[part 7 of 22: package /Cluster]
AUTOSAR XML (schema 4-3-0)
package /Cluster  (continued)
  can cluster E3V_K2CANFD: baudrate=500000, protocol-name=CAN, protocol-version=2.0, bus-off-recovery={bor-counter-l-1-to-l-2=1, bor-time-l-1=0.05, bor-time-l-2=0.2}, can-fd-baudrate=500000  (continued)
    can physical channel CHNL: comm-connectors=CN_E3V_K2CANFD  (continued)
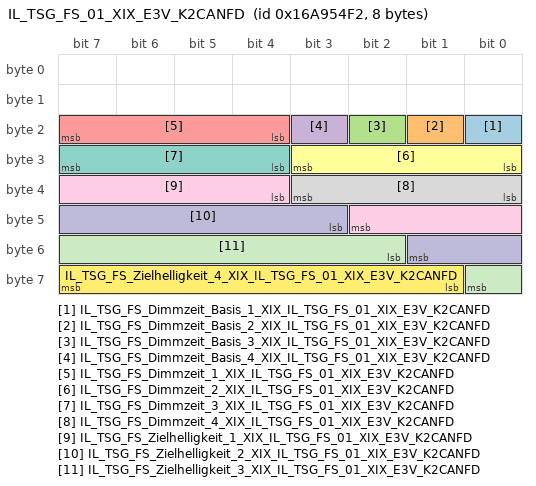
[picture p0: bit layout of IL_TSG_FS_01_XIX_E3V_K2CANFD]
      frame IL_TSG_FS_01_XIX_E3V_K2CANFD: id 0x16A954F2, from SAM, frame-length=8, can-addressing-mode=EXTENDED, can-frame-rx-behavior=CAN-FD, can-frame-tx-behavior=CAN-FD
        pdu IL_TSG_FS_01_XIX_E3V_K2CANFD: length=8, minimum-delay=0.05, transmission-mode-true-timing={cyclic-timing={time-offset=0.0, time-period=0.5}, event-controlled-timing={number-of-repetitions=0, repetition-period=0.0}}, unused-bit-pattern=0
          signal IL_TSG_FS_Dimmzeit_Basis_1_XIX_IL_TSG_FS_01_XIX_E3V_K2CANFD: start 16, 1 bit, little-endian, data-type-policy=OVERRIDE, i-signal-type=PRIMITIVE, init-value=0, base-type=BT_IL_TSG_FS_Dimmzeit_Basis_1, compu {0=Cx0_Zeitbasis_50ms (CM_IL_TSG_FS_Dimmzeit_Basis_1_Cx0_Zeitbasis_50ms), 1=Cx1_Zeitbasis_250ms (CM_IL_TSG_FS_Dimmzeit_Basis_1_Cx1_Zeitbasis_250ms)}, range raw 0..1, transfer-property=TRIGGERED-ON-CHANGE-WITHOUT-REPETITION  # Dimmzeit Zeitbasis für Lichtausgang 1 TSG FS umschaltbar zwischen 250ms und 50ms.
          signal IL_TSG_FS_Dimmzeit_Basis_2_XIX_IL_TSG_FS_01_XIX_E3V_K2CANFD: start 17, 1 bit, little-endian, data-type-policy=OVERRIDE, i-signal-type=PRIMITIVE, init-value=0, base-type=BT_IL_TSG_FS_Dimmzeit_Basis_2, compu {0=Cx0_Zeitbasis_50ms (CM_IL_TSG_FS_Dimmzeit_Basis_2_Cx0_Zeitbasis_50ms), 1=Cx1_Zeitbasis_250ms (CM_IL_TSG_FS_Dimmzeit_Basis_2_Cx1_Zeitbasis_250ms)}, range raw 0..1, transfer-property=TRIGGERED-ON-CHANGE-WITHOUT-REPETITION  # Dimmzeit Zeitbasis für Lichtausgang 2 TSG FS umschaltbar zwischen 250ms und 50ms.
          signal IL_TSG_FS_Dimmzeit_Basis_3_XIX_IL_TSG_FS_01_XIX_E3V_K2CANFD: start 18, 1 bit, little-endian, data-type-policy=OVERRIDE, i-signal-type=PRIMITIVE, init-value=0, base-type=BT_IL_TSG_FS_Dimmzeit_Basis_3, compu {0=Cx0_Zeitbasis_50ms (CM_IL_TSG_FS_Dimmzeit_Basis_3_Cx0_Zeitbasis_50ms), 1=Cx1_Zeitbasis_250ms (CM_IL_TSG_FS_Dimmzeit_Basis_3_Cx1_Zeitbasis_250ms)}, range raw 0..1, transfer-property=TRIGGERED-ON-CHANGE-WITHOUT-REPETITION  # Dimmzeit Zeitbasis für Lichtausgang 3 TSG FS umschaltbar zwischen 250ms und 50ms.
          signal IL_TSG_FS_Dimmzeit_Basis_4_XIX_IL_TSG_FS_01_XIX_E3V_K2CANFD: start 19, 1 bit, little-endian, data-type-policy=OVERRIDE, i-signal-type=PRIMITIVE, init-value=0, base-type=BT_IL_TSG_FS_Dimmzeit_Basis_4, compu {0=Cx0_Zeitbasis_50ms (CM_IL_TSG_FS_Dimmzeit_Basis_4_Cx0_Zeitbasis_50ms), 1=Cx1_Zeitbasis_250ms (CM_IL_TSG_FS_Dimmzeit_Basis_4_Cx1_Zeitbasis_250ms)}, range raw 0..1, transfer-property=TRIGGERED-ON-CHANGE-WITHOUT-REPETITION  # Dimmzeit Zeitbasis für Lichtausgang 4 TSG FS umschaltbar zwischen 250ms und 50ms.
          signal IL_TSG_FS_Dimmzeit_1_XIX_IL_TSG_FS_01_XIX_E3V_K2CANFD: start 20, 4 bit, little-endian, data-type-policy=OVERRIDE, i-signal-type=PRIMITIVE, init-value=0, base-type=BT_IL_TSG_FS_Dimmzeit_1, compu {phys=raw for raw 0..15; unit Unit_None}, range phys 0..15 Unit_None, raw 0..15, unit=Unit_None, transfer-property=TRIGGERED-ON-CHANGE-WITHOUT-REPETITION  # Dimmzeit für Ausgang 1 TSG FS als Multiplikator der Dimmzeit Zeitbasis (Hinweis: Dimmzeit Zeitbasis für Ausgang 1 TSG FS beachten)
          signal IL_TSG_FS_Dimmzeit_2_XIX_IL_TSG_FS_01_XIX_E3V_K2CANFD: start 24, 4 bit, little-endian, data-type-policy=OVERRIDE, i-signal-type=PRIMITIVE, init-value=0, base-type=BT_IL_TSG_FS_Dimmzeit_2, compu {phys=raw for raw 0..15; unit Unit_None}, range phys 0..15 Unit_None, raw 0..15, unit=Unit_None, transfer-property=TRIGGERED-ON-CHANGE-WITHOUT-REPETITION  # Dimmzeit für Ausgang 2 TSG FS als Multiplikator der Dimmzeit Zeitbasis (Hinweis: Dimmzeit Zeitbasis für Ausgang 2 TSG FS beachten)
          signal IL_TSG_FS_Dimmzeit_3_XIX_IL_TSG_FS_01_XIX_E3V_K2CANFD: start 28, 4 bit, little-endian, data-type-policy=OVERRIDE, i-signal-type=PRIMITIVE, init-value=0, base-type=BT_IL_TSG_FS_Dimmzeit_3, compu {phys=raw for raw 0..15; unit Unit_None}, range phys 0..15 Unit_None, raw 0..15, unit=Unit_None, transfer-property=TRIGGERED-ON-CHANGE-WITHOUT-REPETITION  # Dimmzeit für Ausgang 3 TSG FS als Multiplikator der Dimmzeit Zeitbasis (Hinweis: Dimmzeit Zeitbasis für Ausgang 3 TSG FS beachten)
          signal IL_TSG_FS_Dimmzeit_4_XIX_IL_TSG_FS_01_XIX_E3V_K2CANFD: start 32, 4 bit, little-endian, data-type-policy=OVERRIDE, i-signal-type=PRIMITIVE, init-value=0, base-type=BT_IL_TSG_FS_Dimmzeit_4, compu {phys=raw for raw 0..15; unit Unit_None}, range phys 0..15 Unit_None, raw 0..15, unit=Unit_None, transfer-property=TRIGGERED-ON-CHANGE-WITHOUT-REPETITION  # Dimmzeit für Ausgang 4 TSG FS als Multiplikator der Dimmzeit Zeitbasis (Hinweis: Dimmzeit Zeitbasis für Ausgang 4 TSG FS beachten)
          signal IL_TSG_FS_Zielhelligkeit_1_XIX_IL_TSG_FS_01_XIX_E3V_K2CANFD: start 36, 7 bit, little-endian, data-type-policy=OVERRIDE, i-signal-type=PRIMITIVE, init-value=0, base-type=BT_IL_TSG_FS_Zielhelligkeit_1, compu {phys=raw for raw 0..100; unit Unit_PerCent}, range phys 0..100 Unit_PerCent, raw 0..100, unit=Unit_PerCent, transfer-property=TRIGGERED-ON-CHANGE-WITHOUT-REPETITION  # Intensität für Ausgang 1 TSG FS
          signal IL_TSG_FS_Zielhelligkeit_2_XIX_IL_TSG_FS_01_XIX_E3V_K2CANFD: start 43, 7 bit, little-endian, data-type-policy=OVERRIDE, i-signal-type=PRIMITIVE, init-value=0, base-type=BT_IL_TSG_FS_Zielhelligkeit_2, compu {phys=raw for raw 0..100; unit Unit_PerCent}, range phys 0..100 Unit_PerCent, raw 0..100, unit=Unit_PerCent, transfer-property=TRIGGERED-ON-CHANGE-WITHOUT-REPETITION  # Intensität für Ausgang 2 TSG FS
          signal IL_TSG_FS_Zielhelligkeit_3_XIX_IL_TSG_FS_01_XIX_E3V_K2CANFD: start 50, 7 bit, little-endian, data-type-policy=OVERRIDE, i-signal-type=PRIMITIVE, init-value=0, base-type=BT_IL_TSG_FS_Zielhelligkeit_3, compu {phys=raw for raw 0..100; unit Unit_PerCent}, range phys 0..100 Unit_PerCent, raw 0..100, unit=Unit_PerCent, transfer-property=TRIGGERED-ON-CHANGE-WITHOUT-REPETITION  # Intensität für Ausgang 3 TSG FS
          signal IL_TSG_FS_Zielhelligkeit_4_XIX_IL_TSG_FS_01_XIX_E3V_K2CANFD: start 57, 7 bit, little-endian, data-type-policy=OVERRIDE, i-signal-type=PRIMITIVE, init-value=0, base-type=BT_IL_TSG_FS_Zielhelligkeit_4, compu {phys=raw for raw 0..100; unit Unit_PerCent}, range phys 0..100 Unit_PerCent, raw 0..100, unit=Unit_PerCent, transfer-property=TRIGGERED-ON-CHANGE-WITHOUT-REPETITION  # Intensität für Ausgang 4 TSG FS
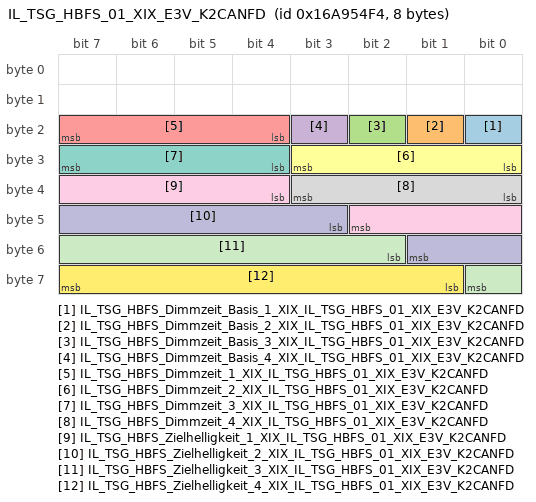
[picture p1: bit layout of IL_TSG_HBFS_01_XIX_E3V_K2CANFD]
      frame IL_TSG_HBFS_01_XIX_E3V_K2CANFD: id 0x16A954F4, from SAM, frame-length=8, can-addressing-mode=EXTENDED, can-frame-rx-behavior=CAN-FD, can-frame-tx-behavior=CAN-FD
        pdu IL_TSG_HBFS_01_XIX_E3V_K2CANFD: length=8, minimum-delay=0.05, transmission-mode-true-timing={cyclic-timing={time-offset=0.0, time-period=0.5}, event-controlled-timing={number-of-repetitions=0, repetition-period=0.0}}, unused-bit-pattern=0
          signal IL_TSG_HBFS_Dimmzeit_Basis_1_XIX_IL_TSG_HBFS_01_XIX_E3V_K2CANFD: start 16, 1 bit, little-endian, data-type-policy=OVERRIDE, i-signal-type=PRIMITIVE, init-value=0, base-type=BT_IL_TSG_HBFS_Dimmzeit_Basis_1, compu {0=Cx0_Zeitbasis_50ms (CM_IL_TSG_HBFS_Dimmzeit_Basis_1_Cx0_Zeitbasis_50ms), 1=Cx1_Zeitbasis_250ms (CM_IL_TSG_HBFS_Dimmzeit_Basis_1_Cx1_Zeitbasis_250ms)}, range raw 0..1, transfer-property=TRIGGERED-ON-CHANGE-WITHOUT-REPETITION  # Dimmzeit Zeitbasis für Lichtausgang 1 TSG HBFS umschaltbar zwischen 250ms und 50ms.
          signal IL_TSG_HBFS_Dimmzeit_Basis_2_XIX_IL_TSG_HBFS_01_XIX_E3V_K2CANFD: start 17, 1 bit, little-endian, data-type-policy=OVERRIDE, i-signal-type=PRIMITIVE, init-value=0, base-type=BT_IL_TSG_HBFS_Dimmzeit_Basis_2, compu {0=Cx0_Zeitbasis_50ms (CM_IL_TSG_HBFS_Dimmzeit_Basis_2_Cx0_Zeitbasis_50ms), 1=Cx1_Zeitbasis_250ms (CM_IL_TSG_HBFS_Dimmzeit_Basis_2_Cx1_Zeitbasis_250ms)}, range raw 0..1, transfer-property=TRIGGERED-ON-CHANGE-WITHOUT-REPETITION  # Dimmzeit Zeitbasis für Lichtausgang 2 TSG HBFS umschaltbar zwischen 250ms und 50ms.
          signal IL_TSG_HBFS_Dimmzeit_Basis_3_XIX_IL_TSG_HBFS_01_XIX_E3V_K2CANFD: start 18, 1 bit, little-endian, data-type-policy=OVERRIDE, i-signal-type=PRIMITIVE, init-value=0, base-type=BT_IL_TSG_HBFS_Dimmzeit_Basis_3, compu {0=Cx0_Zeitbasis_50ms (CM_IL_TSG_HBFS_Dimmzeit_Basis_3_Cx0_Zeitbasis_50ms), 1=Cx1_Zeitbasis_250ms (CM_IL_TSG_HBFS_Dimmzeit_Basis_3_Cx1_Zeitbasis_250ms)}, range raw 0..1, transfer-property=TRIGGERED-ON-CHANGE-WITHOUT-REPETITION  # Dimmzeit Zeitbasis für Lichtausgang 3 TSG HBFS umschaltbar zwischen 250ms und 50ms.
          signal IL_TSG_HBFS_Dimmzeit_Basis_4_XIX_IL_TSG_HBFS_01_XIX_E3V_K2CANFD: start 19, 1 bit, little-endian, data-type-policy=OVERRIDE, i-signal-type=PRIMITIVE, init-value=0, base-type=BT_IL_TSG_HBFS_Dimmzeit_Basis_4, compu {0=Cx0_Zeitbasis_50ms (CM_IL_TSG_HBFS_Dimmzeit_Basis_4_Cx0_Zeitbasis_50ms), 1=Cx1_Zeitbasis_250ms (CM_IL_TSG_HBFS_Dimmzeit_Basis_4_Cx1_Zeitbasis_250ms)}, range raw 0..1, transfer-property=TRIGGERED-ON-CHANGE-WITHOUT-REPETITION  # Dimmzeit Zeitbasis für Lichtausgang 4 TSG HBFS umschaltbar zwischen 250ms und 50ms.
          signal IL_TSG_HBFS_Dimmzeit_1_XIX_IL_TSG_HBFS_01_XIX_E3V_K2CANFD: start 20, 4 bit, little-endian, data-type-policy=OVERRIDE, i-signal-type=PRIMITIVE, init-value=0, base-type=BT_IL_TSG_HBFS_Dimmzeit_1, compu {phys=raw for raw 0..15; unit Unit_None}, range phys 0..15 Unit_None, raw 0..15, unit=Unit_None, transfer-property=TRIGGERED-ON-CHANGE-WITHOUT-REPETITION  # Dimmzeit für Ausgang 1 TSG HBFS als Multiplikator der Dimmzeit Zeitbasis (Hinweis: Dimmzeit Zeitbasis für Ausgang 1 TSG HBFS beachten)
          signal IL_TSG_HBFS_Dimmzeit_2_XIX_IL_TSG_HBFS_01_XIX_E3V_K2CANFD: start 24, 4 bit, little-endian, data-type-policy=OVERRIDE, i-signal-type=PRIMITIVE, init-value=0, base-type=BT_IL_TSG_HBFS_Dimmzeit_2, compu {phys=raw for raw 0..15; unit Unit_None}, range phys 0..15 Unit_None, raw 0..15, unit=Unit_None, transfer-property=TRIGGERED-ON-CHANGE-WITHOUT-REPETITION  # Dimmzeit für Ausgang 2 TSG HBFS als Multiplikator der Dimmzeit Zeitbasis (Hinweis: Dimmzeit Zeitbasis für Ausgang 2 TSG HBFS beachten)
          signal IL_TSG_HBFS_Dimmzeit_3_XIX_IL_TSG_HBFS_01_XIX_E3V_K2CANFD: start 28, 4 bit, little-endian, data-type-policy=OVERRIDE, i-signal-type=PRIMITIVE, init-value=0, base-type=BT_IL_TSG_HBFS_Dimmzeit_3, compu {phys=raw for raw 0..15; unit Unit_None}, range phys 0..15 Unit_None, raw 0..15, unit=Unit_None, transfer-property=TRIGGERED-ON-CHANGE-WITHOUT-REPETITION  # Dimmzeit für Ausgang 3 TSG HBFS als Multiplikator der Dimmzeit Zeitbasis (Hinweis: Dimmzeit Zeitbasis für Ausgang 3 TSG HBFS beachten)
          signal IL_TSG_HBFS_Dimmzeit_4_XIX_IL_TSG_HBFS_01_XIX_E3V_K2CANFD: start 32, 4 bit, little-endian, data-type-policy=OVERRIDE, i-signal-type=PRIMITIVE, init-value=0, base-type=BT_IL_TSG_HBFS_Dimmzeit_4, compu {phys=raw for raw 0..15; unit Unit_None}, range phys 0..15 Unit_None, raw 0..15, unit=Unit_None, transfer-property=TRIGGERED-ON-CHANGE-WITHOUT-REPETITION  # Dimmzeit für Ausgang 4 TSG HBFS als Multiplikator der Dimmzeit Zeitbasis (Hinweis: Dimmzeit Zeitbasis für Ausgang 4 TSG HBFS beachten)
          signal IL_TSG_HBFS_Zielhelligkeit_1_XIX_IL_TSG_HBFS_01_XIX_E3V_K2CANFD: start 36, 7 bit, little-endian, data-type-policy=OVERRIDE, i-signal-type=PRIMITIVE, init-value=0, base-type=BT_IL_TSG_HBFS_Zielhelligkeit_1, compu {phys=raw for raw 0..100; unit Unit_PerCent}, range phys 0..100 Unit_PerCent, raw 0..100, unit=Unit_PerCent, transfer-property=TRIGGERED-ON-CHANGE-WITHOUT-REPETITION  # Intensität für Ausgang 1 TSG HBFS
          signal IL_TSG_HBFS_Zielhelligkeit_2_XIX_IL_TSG_HBFS_01_XIX_E3V_K2CANFD: start 43, 7 bit, little-endian, data-type-policy=OVERRIDE, i-signal-type=PRIMITIVE, init-value=0, base-type=BT_IL_TSG_HBFS_Zielhelligkeit_2, compu {phys=raw for raw 0..100; unit Unit_PerCent}, range phys 0..100 Unit_PerCent, raw 0..100, unit=Unit_PerCent, transfer-property=TRIGGERED-ON-CHANGE-WITHOUT-REPETITION  # Intensität für Ausgang 2 TSG HBFS
          signal IL_TSG_HBFS_Zielhelligkeit_3_XIX_IL_TSG_HBFS_01_XIX_E3V_K2CANFD: start 50, 7 bit, little-endian, data-type-policy=OVERRIDE, i-signal-type=PRIMITIVE, init-value=0, base-type=BT_IL_TSG_HBFS_Zielhelligkeit_3, compu {phys=raw for raw 0..100; unit Unit_PerCent}, range phys 0..100 Unit_PerCent, raw 0..100, unit=Unit_PerCent, transfer-property=TRIGGERED-ON-CHANGE-WITHOUT-REPETITION  # Intensität für Ausgang 3 TSG HBFS
          signal IL_TSG_HBFS_Zielhelligkeit_4_XIX_IL_TSG_HBFS_01_XIX_E3V_K2CANFD: start 57, 7 bit, little-endian, data-type-policy=OVERRIDE, i-signal-type=PRIMITIVE, init-value=0, base-type=BT_IL_TSG_HBFS_Zielhelligkeit_4, compu {phys=raw for raw 0..100; unit Unit_PerCent}, range phys 0..100 Unit_PerCent, raw 0..100, unit=Unit_PerCent, transfer-property=TRIGGERED-ON-CHANGE-WITHOUT-REPETITION  # Intensität für Ausgang 4 TSG HBFS
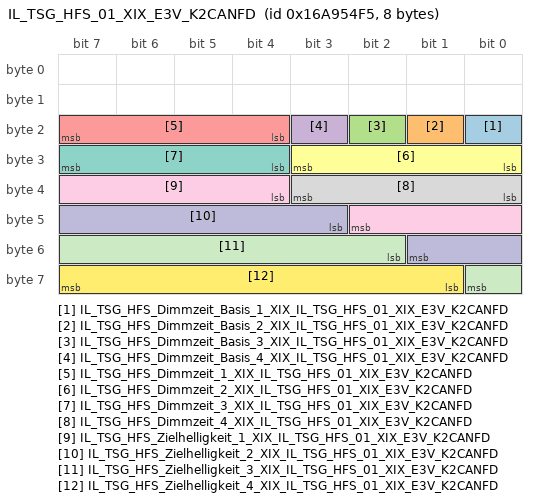
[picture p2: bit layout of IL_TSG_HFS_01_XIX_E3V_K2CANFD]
      frame IL_TSG_HFS_01_XIX_E3V_K2CANFD: id 0x16A954F5, from SAM, frame-length=8, can-addressing-mode=EXTENDED, can-frame-rx-behavior=CAN-FD, can-frame-tx-behavior=CAN-FD
        pdu IL_TSG_HFS_01_XIX_E3V_K2CANFD: length=8, minimum-delay=0.05, transmission-mode-true-timing={cyclic-timing={time-offset=0.0, time-period=0.5}, event-controlled-timing={number-of-repetitions=0, repetition-period=0.0}}, unused-bit-pattern=0
          signal IL_TSG_HFS_Dimmzeit_Basis_1_XIX_IL_TSG_HFS_01_XIX_E3V_K2CANFD: start 16, 1 bit, little-endian, data-type-policy=OVERRIDE, i-signal-type=PRIMITIVE, init-value=0, base-type=BT_IL_TSG_HFS_Dimmzeit_Basis_1, compu {0=Cx0_Zeitbasis_50ms (CM_IL_TSG_HFS_Dimmzeit_Basis_1_Cx0_Zeitbasis_50ms), 1=Cx1_Zeitbasis_250ms (CM_IL_TSG_HFS_Dimmzeit_Basis_1_Cx1_Zeitbasis_250ms)}, range raw 0..1, transfer-property=TRIGGERED-ON-CHANGE-WITHOUT-REPETITION  # Dimmzeit Zeitbasis für Lichtausgang 1 TSG HFS umschaltbar zwischen 250ms und 50ms.
          signal IL_TSG_HFS_Dimmzeit_Basis_2_XIX_IL_TSG_HFS_01_XIX_E3V_K2CANFD: start 17, 1 bit, little-endian, data-type-policy=OVERRIDE, i-signal-type=PRIMITIVE, init-value=0, base-type=BT_IL_TSG_HFS_Dimmzeit_Basis_2, compu {0=Cx0_Zeitbasis_50ms (CM_IL_TSG_HFS_Dimmzeit_Basis_2_Cx0_Zeitbasis_50ms), 1=Cx1_Zeitbasis_250ms (CM_IL_TSG_HFS_Dimmzeit_Basis_2_Cx1_Zeitbasis_250ms)}, range raw 0..1, transfer-property=TRIGGERED-ON-CHANGE-WITHOUT-REPETITION  # Dimmzeit Zeitbasis für Lichtausgang 2 TSG HFS umschaltbar zwischen 250ms und 50ms.
          signal IL_TSG_HFS_Dimmzeit_Basis_3_XIX_IL_TSG_HFS_01_XIX_E3V_K2CANFD: start 18, 1 bit, little-endian, data-type-policy=OVERRIDE, i-signal-type=PRIMITIVE, init-value=0, base-type=BT_IL_TSG_HFS_Dimmzeit_Basis_3, compu {0=Cx0_Zeitbasis_50ms (CM_IL_TSG_HFS_Dimmzeit_Basis_3_Cx0_Zeitbasis_50ms), 1=Cx1_Zeitbasis_250ms (CM_IL_TSG_HFS_Dimmzeit_Basis_3_Cx1_Zeitbasis_250ms)}, range raw 0..1, transfer-property=TRIGGERED-ON-CHANGE-WITHOUT-REPETITION  # Dimmzeit Zeitbasis für Lichtausgang 3 TSG HFS umschaltbar zwischen 250ms und 50ms.
          signal IL_TSG_HFS_Dimmzeit_Basis_4_XIX_IL_TSG_HFS_01_XIX_E3V_K2CANFD: start 19, 1 bit, little-endian, data-type-policy=OVERRIDE, i-signal-type=PRIMITIVE, init-value=0, base-type=BT_IL_TSG_HFS_Dimmzeit_Basis_4, compu {0=Cx0_Zeitbasis_50ms (CM_IL_TSG_HFS_Dimmzeit_Basis_4_Cx0_Zeitbasis_50ms), 1=Cx1_Zeitbasis_250ms (CM_IL_TSG_HFS_Dimmzeit_Basis_4_Cx1_Zeitbasis_250ms)}, range raw 0..1, transfer-property=TRIGGERED-ON-CHANGE-WITHOUT-REPETITION  # Dimmzeit Zeitbasis für Lichtausgang 4 TSG HFS umschaltbar zwischen 250ms und 50ms.
          signal IL_TSG_HFS_Dimmzeit_1_XIX_IL_TSG_HFS_01_XIX_E3V_K2CANFD: start 20, 4 bit, little-endian, data-type-policy=OVERRIDE, i-signal-type=PRIMITIVE, init-value=0, base-type=BT_IL_TSG_HFS_Dimmzeit_1, compu {phys=raw for raw 0..15; unit Unit_None}, range phys 0..15 Unit_None, raw 0..15, unit=Unit_None, transfer-property=TRIGGERED-ON-CHANGE-WITHOUT-REPETITION  # Dimmzeit für Ausgang 1 TSG HFS als Multiplikator der Dimmzeit Zeitbasis (Hinweis: Dimmzeit Zeitbasis für Ausgang 1 TSG HFS beachten)
          signal IL_TSG_HFS_Dimmzeit_2_XIX_IL_TSG_HFS_01_XIX_E3V_K2CANFD: start 24, 4 bit, little-endian, data-type-policy=OVERRIDE, i-signal-type=PRIMITIVE, init-value=0, base-type=BT_IL_TSG_HFS_Dimmzeit_2, compu {phys=raw for raw 0..15; unit Unit_None}, range phys 0..15 Unit_None, raw 0..15, unit=Unit_None, transfer-property=TRIGGERED-ON-CHANGE-WITHOUT-REPETITION  # Dimmzeit für Ausgang TSG HFS als Multiplikator der Dimmzeit Zeitbasis (Hinweis: Dimmzeit Zeitbasis für Ausgang 2 TSG HFS beachten)
          signal IL_TSG_HFS_Dimmzeit_3_XIX_IL_TSG_HFS_01_XIX_E3V_K2CANFD: start 28, 4 bit, little-endian, data-type-policy=OVERRIDE, i-signal-type=PRIMITIVE, init-value=0, base-type=BT_IL_TSG_HFS_Dimmzeit_3, compu {phys=raw for raw 0..15; unit Unit_None}, range phys 0..15 Unit_None, raw 0..15, unit=Unit_None, transfer-property=TRIGGERED-ON-CHANGE-WITHOUT-REPETITION  # Dimmzeit für Ausgang 3 TSG HFS als Multiplikator der Dimmzeit Zeitbasis (Hinweis: Dimmzeit Zeitbasis für Ausgang 3 TSG HFS beachten)
          signal IL_TSG_HFS_Dimmzeit_4_XIX_IL_TSG_HFS_01_XIX_E3V_K2CANFD: start 32, 4 bit, little-endian, data-type-policy=OVERRIDE, i-signal-type=PRIMITIVE, init-value=0, base-type=BT_IL_TSG_HFS_Dimmzeit_4, compu {phys=raw for raw 0..15; unit Unit_None}, range phys 0..15 Unit_None, raw 0..15, unit=Unit_None, transfer-property=TRIGGERED-ON-CHANGE-WITHOUT-REPETITION  # Dimmzeit für Ausgang 4 TSG HFS als Multiplikator der Dimmzeit Zeitbasis (Hinweis: Dimmzeit Zeitbasis für Ausgang 4 TSG HFS beachten)
          signal IL_TSG_HFS_Zielhelligkeit_1_XIX_IL_TSG_HFS_01_XIX_E3V_K2CANFD: start 36, 7 bit, little-endian, data-type-policy=OVERRIDE, i-signal-type=PRIMITIVE, init-value=0, base-type=BT_IL_TSG_HFS_Zielhelligkeit_1, compu {phys=raw for raw 0..100; unit Unit_PerCent}, range phys 0..100 Unit_PerCent, raw 0..100, unit=Unit_PerCent, transfer-property=TRIGGERED-ON-CHANGE-WITHOUT-REPETITION  # Intensität für Ausgang 1 TSG HFS
          signal IL_TSG_HFS_Zielhelligkeit_2_XIX_IL_TSG_HFS_01_XIX_E3V_K2CANFD: start 43, 7 bit, little-endian, data-type-policy=OVERRIDE, i-signal-type=PRIMITIVE, init-value=0, base-type=BT_IL_TSG_HFS_Zielhelligkeit_2, compu {phys=raw for raw 0..100; unit Unit_PerCent}, range phys 0..100 Unit_PerCent, raw 0..100, unit=Unit_PerCent, transfer-property=TRIGGERED-ON-CHANGE-WITHOUT-REPETITION  # Intensität für Ausgang 2 TSG HFS
          signal IL_TSG_HFS_Zielhelligkeit_3_XIX_IL_TSG_HFS_01_XIX_E3V_K2CANFD: start 50, 7 bit, little-endian, data-type-policy=OVERRIDE, i-signal-type=PRIMITIVE, init-value=0, base-type=BT_IL_TSG_HFS_Zielhelligkeit_3, compu {phys=raw for raw 0..100; unit Unit_PerCent}, range phys 0..100 Unit_PerCent, raw 0..100, unit=Unit_PerCent, transfer-property=TRIGGERED-ON-CHANGE-WITHOUT-REPETITION  # Intensität für Ausgang 3 TSG HFS
          signal IL_TSG_HFS_Zielhelligkeit_4_XIX_IL_TSG_HFS_01_XIX_E3V_K2CANFD: start 57, 7 bit, little-endian, data-type-policy=OVERRIDE, i-signal-type=PRIMITIVE, init-value=0, base-type=BT_IL_TSG_HFS_Zielhelligkeit_4, compu {phys=raw for raw 0..100; unit Unit_PerCent}, range phys 0..100 Unit_PerCent, raw 0..100, unit=Unit_PerCent, transfer-property=TRIGGERED-ON-CHANGE-WITHOUT-REPETITION  # Intensität für Ausgang 4 TSG HFS
      frame Innenlicht_11_XIX_E3V_K2CANFD: id 0x5F4, from SAM, frame-length=8, can-addressing-mode=STANDARD, can-frame-rx-behavior=CAN-FD, can-frame-tx-behavior=CAN-FD
        pdu Innenlicht_11_XIX_E3V_K2CANFD: length=8, minimum-delay=0.05, transmission-mode-true-timing={cyclic-timing={time-offset=0.0, time-period=0.5}, event-controlled-timing={number-of-repetitions=0, repetition-period=0.0}}, unused-bit-pattern=0
          signal IL_Dimmung_V_Tuerkontur_XIX_Innenlicht_11_XIX_E3V_K2CANFD: start 0, 8 bit, little-endian, data-type-policy=OVERRIDE, i-signal-type=PRIMITIVE, init-value=0, base-type=BT_IL_Dimmung_V_Tuerkontur, compu {phys=raw for raw 0..100; unit Unit_PerCent}, range phys 0..100 Unit_PerCent, raw 0..100, unit=Unit_PerCent, transfer-property=TRIGGERED-ON-CHANGE-WITHOUT-REPETITION  # Dimmung Türkontur vorne (bei Änderung im 30 ms Raster)
          signal IL_Dimmung_H_Tuerkontur_XIX_Innenlicht_11_XIX_E3V_K2CANFD: start 8, 8 bit, little-endian, data-type-policy=OVERRIDE, i-signal-type=PRIMITIVE, init-value=0, base-type=BT_IL_Dimmung_H_Tuerkontur, compu {phys=raw for raw 0..100; unit Unit_PerCent}, range phys 0..100 Unit_PerCent, raw 0..100, unit=Unit_PerCent, transfer-property=TRIGGERED-ON-CHANGE-WITHOUT-REPETITION  # Dimmung Türkontur hinten (bei Änderung im 30 ms Raster)
          signal IL_Dimmung_Tuerinnengriff_XIX_Innenlicht_11_XIX_E3V_K2CANFD: start 16, 8 bit, little-endian, data-type-policy=OVERRIDE, i-signal-type=PRIMITIVE, init-value=0, base-type=BT_IL_Dimmung_Tuerinnengriff, compu {phys=raw for raw 0..100; unit Unit_PerCent}, range phys 0..100 Unit_PerCent, raw 0..100, unit=Unit_PerCent, transfer-property=TRIGGERED-ON-CHANGE-WITHOUT-REPETITION  # Dimmung Türinnengriff
          signal IL_Dimmung_Umfeldbel_XIX_Innenlicht_11_XIX_E3V_K2CANFD: start 24, 8 bit, little-endian, data-type-policy=OVERRIDE, i-signal-type=PRIMITIVE, init-value=0, base-type=BT_IL_Dimmung_Umfeldbel, compu {phys=raw for raw 0..100; unit Unit_PerCent}, range phys 0..100 Unit_PerCent, raw 0..100, unit=Unit_PerCent, transfer-property=TRIGGERED-ON-CHANGE-WITHOUT-REPETITION  # Dimmung Umfeldbeleuchtung an Türaußenseite oder Außenspiegel
          signal IL_Bel_FS_Ausstieg_XIX_Innenlicht_11_XIX_E3V_K2CANFD: start 32, 1 bit, little-endian, data-type-policy=OVERRIDE, i-signal-type=PRIMITIVE, init-value=0, base-type=BT_IL_Bel_FS_Ausstieg, compu {0=Cx0_inaktiv (CM_IL_Bel_FS_Ausstieg_Cx0_inaktiv), 1=Cx1_aktiv (CM_IL_Bel_FS_Ausstieg_Cx1_aktiv)}, range raw 0..1, transfer-property=TRIGGERED-ON-CHANGE-WITHOUT-REPETITION  # Einschalten der Ausstiegsleuchten oder Türwarnleuchten in Tür oder im Schweller
          signal IL_Bel_BFS_Ausstieg_XIX_Innenlicht_11_XIX_E3V_K2CANFD: start 33, 1 bit, little-endian, data-type-policy=OVERRIDE, i-signal-type=PRIMITIVE, init-value=0, base-type=BT_IL_Bel_BFS_Ausstieg, compu {0=Cx0_inaktiv (CM_IL_Bel_BFS_Ausstieg_Cx0_inaktiv), 1=Cx1_aktiv (CM_IL_Bel_BFS_Ausstieg_Cx1_aktiv)}, range raw 0..1, transfer-property=TRIGGERED-ON-CHANGE-WITHOUT-REPETITION  # Einschalten der Ausstiegsleuchten oder Türwarnleuchten in Tür oder im Schweller
          signal IL_Bel_HFS_Ausstieg_XIX_Innenlicht_11_XIX_E3V_K2CANFD: start 34, 1 bit, little-endian, data-type-policy=OVERRIDE, i-signal-type=PRIMITIVE, init-value=0, base-type=BT_IL_Bel_HFS_Ausstieg, compu {0=Cx0_inaktiv (CM_IL_Bel_HFS_Ausstieg_Cx0_inaktiv), 1=Cx1_aktiv (CM_IL_Bel_HFS_Ausstieg_Cx1_aktiv)}, range raw 0..1, transfer-property=TRIGGERED-ON-CHANGE-WITHOUT-REPETITION  # Einschalten der Ausstiegsleuchten oder Türwarnleuchten in Tür oder im Schweller
          signal IL_Bel_HBFS_Ausstieg_XIX_Innenlicht_11_XIX_E3V_K2CANFD: start 35, 1 bit, little-endian, data-type-policy=OVERRIDE, i-signal-type=PRIMITIVE, init-value=0, base-type=BT_IL_Bel_HBFS_Ausstieg, compu {0=Cx0_inaktiv (CM_IL_Bel_HBFS_Ausstieg_Cx0_inaktiv), 1=Cx1_aktiv (CM_IL_Bel_HBFS_Ausstieg_Cx1_aktiv)}, range raw 0..1, transfer-property=TRIGGERED-ON-CHANGE-WITHOUT-REPETITION  # Einschalten der Ausstiegsleuchten oder Türwarnleuchten in Tür oder im Schweller
          signal BCM1_Innenlicht_gedimmt_V_XIX_Innenlicht_11_XIX_E3V_K2CANFD: start 36, 1 bit, little-endian, data-type-policy=OVERRIDE, i-signal-type=PRIMITIVE, init-value=0, base-type=BT_BCM1_Innenlicht_gedimmt_V, compu {0=Cx0_100_Innenlicht (CM_BCM1_Innenlicht_gedimmt_V_Cx0_100_Innenlicht) (100% Innenlicht), 1=Cx1_gedimmtes_Innenlicht (CM_BCM1_Innenlicht_gedimmt_V_Cx1_gedimmtes_Innenlicht) (gedimmtes Innenlicht)}, range raw 0..1, transfer-property=TRIGGERED-ON-CHANGE-WITHOUT-REPETITION  # Steuerung von BCM_Innenlicht_V
          signal BCM1_Innenlicht_gedimmt_H_XIX_Innenlicht_11_XIX_E3V_K2CANFD: start 37, 1 bit, little-endian, data-type-policy=OVERRIDE, i-signal-type=PRIMITIVE, init-value=0, base-type=BT_BCM1_Innenlicht_gedimmt_H, compu {0=Cx0_100_Innenlicht (CM_BCM1_Innenlicht_gedimmt_H_Cx0_100_Innenlicht) (100% Innenlicht), 1=Cx1_gedimmtes_Innenlicht (CM_BCM1_Innenlicht_gedimmt_H_Cx1_gedimmtes_Innenlicht) (gedimmtes Innenlicht)}, range raw 0..1, transfer-property=TRIGGERED-ON-CHANGE-WITHOUT-REPETITION  # Steuerung von BCM_Innenlicht_H
          signal IL_Innenlicht_aktiv_XIX_Innenlicht_11_XIX_E3V_K2CANFD: start 38, 1 bit, little-endian, data-type-policy=OVERRIDE, i-signal-type=PRIMITIVE, init-value=1, base-type=BT_IL_Innenlicht_aktiv, compu {0=Cx0_Innenlicht_inaktiv (CM_IL_Innenlicht_aktiv_Cx0_Innenlicht_inaktiv) (Innenlicht inaktiv), 1=Cx1_Innenlicht_aktiv (CM_IL_Innenlicht_aktiv_Cx1_Innenlicht_aktiv) (Innenlicht aktiv)}, range raw 0..1, transfer-property=TRIGGERED-ON-CHANGE-WITHOUT-REPETITION  # Status Innenlicht
          signal IL_Klemme_30G_aktiv_XIX_Innenlicht_11_XIX_E3V_K2CANFD: start 39, 1 bit, little-endian, data-type-policy=OVERRIDE, i-signal-type=PRIMITIVE, init-value=0, base-type=BT_IL_Klemme_30G_aktiv, compu {0=Cx0_Kl_30G_abgeschaltet (CM_IL_Klemme_30G_aktiv_Cx0_Kl_30G_abgeschaltet), 1=Cx1_eingeschaltet (CM_IL_Klemme_30G_aktiv_Cx1_eingeschaltet)}, range raw 0..1, transfer-property=TRIGGERED-ON-CHANGE-WITHOUT-REPETITION  # Synchrones Abschalten
          signal BCM1_DI_Rampe_Innenlicht_XIX_Innenlicht_11_XIX_E3V_K2CANFD: start 40, 1 bit, little-endian, data-type-policy=OVERRIDE, i-signal-type=PRIMITIVE, init-value=0, base-type=BT_BCM1_DI_Rampe_Innenlicht, compu {0=Cx0_Dimmrampe_0 (CM_BCM1_DI_Rampe_Innenlicht_Cx0_Dimmrampe_0) (Dimmrampe 0), 1=Cx1_Dimmrampe_1 (CM_BCM1_DI_Rampe_Innenlicht_Cx1_Dimmrampe_1) (Dimmrampe 1)}, range raw 0..1, transfer-property=TRIGGERED-ON-CHANGE-WITHOUT-REPETITION  # Dimmrampe Innenlicht
          signal BCM1_DI_Rampe_Leselicht_XIX_Innenlicht_11_XIX_E3V_K2CANFD: start 41, 1 bit, little-endian, data-type-policy=OVERRIDE, i-signal-type=PRIMITIVE, init-value=0, base-type=BT_BCM1_DI_Rampe_Leselicht, compu {0=Cx0_Dimmrampe_0 (CM_BCM1_DI_Rampe_Leselicht_Cx0_Dimmrampe_0) (Dimmrampe 0), 1=Cx1_Dimmrampe_1 (CM_BCM1_DI_Rampe_Leselicht_Cx1_Dimmrampe_1) (Dimmrampe 1)}, range raw 0..1, transfer-property=TRIGGERED-ON-CHANGE-WITHOUT-REPETITION  # Dimmrampe Leselicht
          signal BCM1_Innenlicht_H_XIX_Innenlicht_11_XIX_E3V_K2CANFD: start 42, 1 bit, little-endian, data-type-policy=OVERRIDE, i-signal-type=PRIMITIVE, init-value=0, base-type=BT_BCM1_Innenlicht_H, compu {0=Cx0_Aus (CM_BCM1_Innenlicht_H_Cx0_Aus), 1=Cx1_Ein (CM_BCM1_Innenlicht_H_Cx1_Ein)}, range raw 0..1, transfer-property=TRIGGERED-ON-CHANGE-WITHOUT-REPETITION  # Anforderung Innenlicht hinten
          signal BCM1_Innenlicht_V_XIX_Innenlicht_11_XIX_E3V_K2CANFD: start 43, 1 bit, little-endian, data-type-policy=OVERRIDE, i-signal-type=PRIMITIVE, init-value=0, base-type=BT_BCM1_Innenlicht_V, compu {0=Cx0_Aus (CM_BCM1_Innenlicht_V_Cx0_Aus), 1=Cx1_Ein (CM_BCM1_Innenlicht_V_Cx1_Ein)}, range raw 0..1, transfer-property=TRIGGERED-ON-CHANGE-WITHOUT-REPETITION  # Anforderung Innenlicht vorne
          signal BCM1_Leselicht_Anf_hl_XIX_Innenlicht_11_XIX_E3V_K2CANFD: start 44, 1 bit, little-endian, data-type-policy=OVERRIDE, i-signal-type=PRIMITIVE, init-value=0, base-type=BT_BCM1_Leselicht_Anf_hl, compu {0=Cx0_Aus (CM_BCM1_Leselicht_Anf_hl_Cx0_Aus), 1=Cx1_Ein (CM_BCM1_Leselicht_Anf_hl_Cx1_Ein)}, range raw 0..1, transfer-property=TRIGGERED-ON-CHANGE-WITHOUT-REPETITION  # Leselicht hinten links Anforderung
          signal BCM1_Leselicht_Anf_hr_XIX_Innenlicht_11_XIX_E3V_K2CANFD: start 45, 1 bit, little-endian, data-type-policy=OVERRIDE, i-signal-type=PRIMITIVE, init-value=0, base-type=BT_BCM1_Leselicht_Anf_hr, compu {0=Cx0_Aus (CM_BCM1_Leselicht_Anf_hr_Cx0_Aus), 1=Cx1_Ein (CM_BCM1_Leselicht_Anf_hr_Cx1_Ein)}, range raw 0..1, transfer-property=TRIGGERED-ON-CHANGE-WITHOUT-REPETITION  # Leselicht hinten rechts Anforderung
          signal BCM1_Leselicht_Anf_vl_XIX_Innenlicht_11_XIX_E3V_K2CANFD: start 46, 1 bit, little-endian, data-type-policy=OVERRIDE, i-signal-type=PRIMITIVE, init-value=0, base-type=BT_BCM1_Leselicht_Anf_vl, compu {0=Cx0_Aus (CM_BCM1_Leselicht_Anf_vl_Cx0_Aus), 1=Cx1_Ein (CM_BCM1_Leselicht_Anf_vl_Cx1_Ein)}, range raw 0..1, transfer-property=TRIGGERED-ON-CHANGE-WITHOUT-REPETITION  # Leselicht vorne links Anforderung
          signal BCM1_Leselicht_Anf_vr_XIX_Innenlicht_11_XIX_E3V_K2CANFD: start 47, 1 bit, little-endian, data-type-policy=OVERRIDE, i-signal-type=PRIMITIVE, init-value=0, base-type=BT_BCM1_Leselicht_Anf_vr, compu {0=Cx0_Aus (CM_BCM1_Leselicht_Anf_vr_Cx0_Aus), 1=Cx1_Ein (CM_BCM1_Leselicht_Anf_vr_Cx1_Ein)}, range raw 0..1, transfer-property=TRIGGERED-ON-CHANGE-WITHOUT-REPETITION  # Leselicht vorne rechts Anforderung
          signal BCM1_Leuchten_Aus_XIX_Innenlicht_11_XIX_E3V_K2CANFD: start 48, 1 bit, little-endian, data-type-policy=OVERRIDE, i-signal-type=PRIMITIVE, init-value=0, base-type=BT_BCM1_Leuchten_Aus, compu {0=Cx0_keine_Aenderung (CM_BCM1_Leuchten_Aus_Cx0_keine_Aenderung) (keine Aenderung), 1=Cx1_Aus (CM_BCM1_Leuchten_Aus_Cx1_Aus)}, range raw 0..1, transfer-property=TRIGGERED-ON-CHANGE-WITHOUT-REPETITION  # Innenbeleuchtung ausschalten (keine Änderung / ausschalten)
          signal AMB_Charisma_FahrPr_XIX_Innenlicht_11_XIX_E3V_K2CANFD: start 49, 4 bit, little-endian, data-type-policy=OVERRIDE, i-signal-type=PRIMITIVE, init-value=0, base-type=BT_AMB_Charisma_FahrPr, compu {0=Cx0_keine_Funktion (CM_AMB_Charisma_FahrPr_Cx0_keine_Funktion), 1=Cx1_Programm_1 (CM_AMB_Charisma_FahrPr_Cx1_Programm_1), 2=Cx2_Programm_2 (CM_AMB_Charisma_FahrPr_Cx2_Programm_2), 3=Cx3_Programm_3 (CM_AMB_Charisma_FahrPr_Cx3_Programm_3), 4=Cx4_Programm_4 (CM_AMB_Charisma_FahrPr_Cx4_Programm_4), 5=Cx5_Programm_5 (CM_AMB_Charisma_FahrPr_Cx5_Programm_5), 6=Cx6_Programm_6 (CM_AMB_Charisma_FahrPr_Cx6_Programm_6), 7=Cx7_Programm_7 (CM_AMB_Charisma_FahrPr_Cx7_Programm_7), 8=Cx8_Programm_8 (CM_AMB_Charisma_FahrPr_Cx8_Programm_8), 9=Cx9_Programm_9 (CM_AMB_Charisma_FahrPr_Cx9_Programm_9), 10=Cxa_Programm_10 (CM_AMB_Charisma_FahrPr_Cxa_Programm_10), 11=Cxb_Programm_11 (CM_AMB_Charisma_FahrPr_Cxb_Programm_11), 12=Cxc_Programm_12 (CM_AMB_Charisma_FahrPr_Cxc_Programm_12), 13=Cxd_Programm_13 (CM_AMB_Charisma_FahrPr_Cxd_Programm_13), 14=Cxe_Programm_14 (CM_AMB_Charisma_FahrPr_Cxe_Programm_14), 15=Cxf_Programm_15 (CM_AMB_Charisma_FahrPr_Cxf_Programm_15)}, range raw 0..15, transfer-property=TRIGGERED-ON-CHANGE-WITHOUT-REPETITION  # MLBevo: Aktuelles Fahrprogramm des Charisma-Teilnehmers (siehe Systemlastenheft Drive Select) MQB: Istwert der Kennlinie (siehe Systemlastenheft MQB FPA)
          signal AMB_Charisma_Status_XIX_Innenlicht_11_XIX_E3V_K2CANFD: start 53, 2 bit, little-endian, data-type-policy=OVERRIDE, i-signal-type=PRIMITIVE, init-value=0, base-type=BT_AMB_Charisma_Status, compu {0=Cx0_Init (CM_AMB_Charisma_Status_Cx0_Init), 1=Cx1_verfuegbar (CM_AMB_Charisma_Status_Cx1_verfuegbar), 2=Cx2_nicht_verfuegbar (CM_AMB_Charisma_Status_Cx2_nicht_verfuegbar), 3=Cx3_asynchron_durch_Fahrerwunsch (CM_AMB_Charisma_Status_Cx3_asynchron_durch_Fahrerwunsch)}, range raw 0..3, transfer-property=TRIGGERED-ON-CHANGE-WITHOUT-REPETITION  # Systemstatus des Charismateilnehmers Wert 0x3 ist nur für Fahrzeuge ab MQB relevant
          signal IL_Tuerkontakt_Taster_XIX_Innenlicht_11_XIX_E3V_K2CANFD: start 55, 1 bit, little-endian, data-type-policy=OVERRIDE, i-signal-type=PRIMITIVE, init-value=0, base-type=BT_IL_Tuerkontakt_Taster, compu {0=Cx0_nicht_betaetigt (CM_IL_Tuerkontakt_Taster_Cx0_nicht_betaetigt), 1=Cx1_betaetigt (CM_IL_Tuerkontakt_Taster_Cx1_betaetigt)}, range raw 0..1, transfer-property=TRIGGERED-ON-CHANGE-WITHOUT-REPETITION  # Statussignal des Türkontakts-Tasters der Dachkonsole
          signal IL_Dimmung_Lautspr_XIX_Innenlicht_11_XIX_E3V_K2CANFD: start 56, 8 bit, little-endian, data-type-policy=OVERRIDE, i-signal-type=PRIMITIVE, init-value=0, base-type=BT_IL_Dimmung_Lautspr, compu {phys=raw for raw 0..100; unit Unit_PerCent}, range phys 0..100 Unit_PerCent, raw 0..100, unit=Unit_PerCent, transfer-property=TRIGGERED-ON-CHANGE-WITHOUT-REPETITION  # Dimmung Umfeldbeleuchtung an Türaußenseite oder Außenspiegel
      frame IPA_02_XIX_E3V_K2CANFD: id 0x16A9545F, to SAM, frame-length=8, can-addressing-mode=EXTENDED, can-frame-rx-behavior=CAN-FD, can-frame-tx-behavior=CAN-FD
        pdu IPA_02_XIX_E3V_K2CANFD: length=8, minimum-delay=0.05, transmission-mode-true-timing={cyclic-timing={time-offset=0.0, time-period=1.0}, event-controlled-timing={number-of-repetitions=5, repetition-period=0.1}}, unused-bit-pattern=0  # ehemals ZFAS_01
          signal IPA_02_CRC_XIX_IPA_02_XIX_E3V_K2CANFD: start 0, 8 bit, little-endian, data-type-policy=OVERRIDE, i-signal-type=PRIMITIVE, base-type=BT_IPA_02_CRC, compu {phys=raw for raw 0..255}, range phys 0..255, raw 0..255, transfer-property=PENDING  # Für MLB: Berechnung siehe Lastenheft "Kommunikationsabsicherung für FlexRay und CAN" Ab MQB und MLBevo: Berechnung siehe Lastenheft "End-to-End Kommunikationsabsicherung" Endwerte siehe Begleitdokument "S-PDU Kennungsfolgen"
          signal IPA_02_BZ_XIX_IPA_02_XIX_E3V_K2CANFD: start 8, 4 bit, little-endian, data-type-policy=OVERRIDE, i-signal-type=PRIMITIVE, base-type=BT_IPA_02_BZ, compu {phys=raw for raw 0..15}, range phys 0..15, raw 0..15, transfer-property=PENDING  # 4bit Botschaftszähler, wird mit jeder Sendebotschaft inkrementiert
          signal IPA_PL_Anzeige_links_XIX_IPA_02_XIX_E3V_K2CANFD: start 12, 2 bit, little-endian, data-type-policy=OVERRIDE, i-signal-type=PRIMITIVE, init-value=0, base-type=BT_IPA_PL_Anzeige_links, compu {0=Cx0_keine_PL_erkannt (CM_IPA_PL_Anzeige_links_Cx0_keine_PL_erkannt), 1=Cx1_links_Quer (CM_IPA_PL_Anzeige_links_Cx1_links_Quer), 2=Cx2_links_Laengs (CM_IPA_PL_Anzeige_links_Cx2_links_Laengs), 3=Cx3_reserviert (CM_IPA_PL_Anzeige_links_Cx3_reserviert)}, range raw 0..3, transfer-property=PENDING  # Zeigt an, ob auf der linken Seite eine Parklücke erkannt wurde.
          signal IPA_PL_Anzeige_rechts_XIX_IPA_02_XIX_E3V_K2CANFD: start 14, 2 bit, little-endian, data-type-policy=OVERRIDE, i-signal-type=PRIMITIVE, init-value=0, base-type=BT_IPA_PL_Anzeige_rechts, compu {0=Cx0_keine_PL_erkannt (CM_IPA_PL_Anzeige_rechts_Cx0_keine_PL_erkannt), 1=Cx1_rechts_Quer (CM_IPA_PL_Anzeige_rechts_Cx1_rechts_Quer), 2=Cx2_rechts_Laengs (CM_IPA_PL_Anzeige_rechts_Cx2_rechts_Laengs), 3=Cx3_reserviert (CM_IPA_PL_Anzeige_rechts_Cx3_reserviert)}, range raw 0..3, transfer-property=PENDING  # Zeigt an, ob auf der rechten Seite eine Parklücke erkannt wurde.
          signal FoD_DTC_RPA_EPH_XIX_IPA_02_XIX_E3V_K2CANFD: start 16, 1 bit, little-endian, data-type-policy=OVERRIDE, i-signal-type=PRIMITIVE, init-value=0, base-type=BT_FoD_DTC_RPA_EPH, compu {0=Cx0_Kein_DTC (CM_FoD_DTC_RPA_EPH_Cx0_Kein_DTC), 1=Cx1_RPA_DTC_vorhanden (CM_FoD_DTC_RPA_EPH_Cx1_RPA_DTC_vorhanden)}, range raw 0..1, transfer-property=PENDING  # Function on Demand DTC for RPA from EPH to Function Master
          signal FoD_DTC_IPA_EPH_XIX_IPA_02_XIX_E3V_K2CANFD: start 17, 1 bit, little-endian, data-type-policy=OVERRIDE, i-signal-type=PRIMITIVE, init-value=0, base-type=BT_FoD_DTC_IPA_EPH, compu {0=Cx0_Kein_DTC (CM_FoD_DTC_IPA_EPH_Cx0_Kein_DTC), 1=Cx1_IPA_DTC_vorhanden (CM_FoD_DTC_IPA_EPH_Cx1_IPA_DTC_vorhanden)}, range raw 0..1, transfer-property=PENDING  # Function on Demand DTC for IPA from EPH to Function Master
          signal FoD_DTC_TPA_rTPA_EPH_XIX_IPA_02_XIX_E3V_K2CANFD: start 18, 2 bit, little-endian, data-type-policy=OVERRIDE, i-signal-type=PRIMITIVE, init-value=0, base-type=BT_FoD_DTC_TPA_rTPA_EPH, compu {0=Cx0_Kein_DTC (CM_FoD_DTC_TPA_rTPA_EPH_Cx0_Kein_DTC), 1=Cx1_TPA_DTC_vorhanden (CM_FoD_DTC_TPA_rTPA_EPH_Cx1_TPA_DTC_vorhanden), 2=Cx2_rTPA_DTC_vorhanden (CM_FoD_DTC_TPA_rTPA_EPH_Cx2_rTPA_DTC_vorhanden), 3=Cx3_TPA_und_rTPA_DTC_vorhanden (CM_FoD_DTC_TPA_rTPA_EPH_Cx3_TPA_und_rTPA_DTC_vorhanden)}, range raw 0..3, transfer-property=PENDING  # Function on Demand DTC for TPA and rTPA from EPH to Function Master
          signal Parken_Seitenspiegel_Anf_XIX_IPA_02_XIX_E3V_K2CANFD: start 20, 2 bit, little-endian, data-type-policy=OVERRIDE, i-signal-type=PRIMITIVE, init-value=0, base-type=BT_Parken_Seitenspiegel_Anf, compu {0=Cx0_Keine_Anforderung (CM_Parken_Seitenspiegel_Anf_Cx0_Keine_Anforderung), 1=Cx1_Seitenspiegel_anklappen (CM_Parken_Seitenspiegel_Anf_Cx1_Seitenspiegel_anklappen), 2=Cx2_Seitenspiegel_abklappen (CM_Parken_Seitenspiegel_Anf_Cx2_Seitenspiegel_abklappen)}, range raw 0..2, transfer-property=TRIGGERED-ON-CHANGE  # Anforderung für Seitenspiegel an- oder abklappen beim PiloPa
          signal Parken_ZV_Schliessen_XIX_IPA_02_XIX_E3V_K2CANFD: start 22, 2 bit, little-endian, data-type-policy=OVERRIDE, i-signal-type=PRIMITIVE, init-value=0, base-type=BT_Parken_ZV_Schliessen, compu {0=Cx0_Keine_Anforderung (CM_Parken_ZV_Schliessen_Cx0_Keine_Anforderung), 1=Cx1_ZV_verriegeln (CM_Parken_ZV_Schliessen_Cx1_ZV_verriegeln), 2=Cx2_ZV_safen (CM_Parken_ZV_Schliessen_Cx2_ZV_safen)}, range raw 0..2, transfer-property=TRIGGERED-ON-CHANGE  # Anforderung für Zentralverriegelung verriegeln oder safen beim PiloPa
          signal Parken_aktives_System_02_XIX_IPA_02_XIX_E3V_K2CANFD: start 24, 5 bit, little-endian, data-type-policy=OVERRIDE, i-signal-type=PRIMITIVE, init-value=0, base-type=BT_Parken_aktives_System_02, compu {0=Cx0_Init (CM_Parken_aktives_System_02_Cx0_Init), 1=Cx1_Keine_Aktivitaet (CM_Parken_aktives_System_02_Cx1_Keine_Aktivitaet), 2=Cx2_RPA (CM_Parken_aktives_System_02_Cx2_RPA), 3=Cx3_IPA (CM_Parken_aktives_System_02_Cx3_IPA), 4=Cx4_MA (CM_Parken_aktives_System_02_Cx4_MA), 5=Cx5_TP (CM_Parken_aktives_System_02_Cx5_TP), 6=Cx6_rTP (CM_Parken_aktives_System_02_Cx6_rTP), 7=Cx7_AAA (CM_Parken_aktives_System_02_Cx7_AAA), 8=Cx8_rAAA (CM_Parken_aktives_System_02_Cx8_rAAA), 9=Cx9_ARA_1 (CM_Parken_aktives_System_02_Cx9_ARA_1), 10=Cxa_PLA (CM_Parken_aktives_System_02_Cxa_PLA), 11=Cxb_RBF (CM_Parken_aktives_System_02_Cxb_RBF), 12=Cxc_PHP (CM_Parken_aktives_System_02_Cxc_PHP), 13=Cxd_RA (CM_Parken_aktives_System_02_Cxd_RA)}, range raw 0..13, transfer-property=TRIGGERED-ON-CHANGE, to SAM(timeout 5 s)  # zeigt an welches parkendes System aktiv ist
          signal Parken_ZR_Sondermodus_Anf_XIX_IPA_02_XIX_E3V_K2CANFD: start 29, 2 bit, little-endian, data-type-policy=OVERRIDE, i-signal-type=PRIMITIVE, init-value=0, base-type=BT_Parken_ZR_Sondermodus_Anf, compu {0=Cx0_Init (CM_Parken_ZR_Sondermodus_Anf_Cx0_Init), 1=Cx1_Keine_Anforderung (CM_Parken_ZR_Sondermodus_Anf_Cx1_Keine_Anforderung), 2=Cx2_Anforderung_Sondermodus (CM_Parken_ZR_Sondermodus_Anf_Cx2_Anforderung_Sondermodus)}, range raw 0..2, transfer-property=TRIGGERED-ON-CHANGE  # Anforderung Sondermodus, um beim „pilotierten Parken“ spezielle Funktionsanpassungen im Infotainment-Bereich zu ermöglichen (u.a. schnellerer Startup, Abschaltung BT)
          signal Parken_Schluesselsuche_Anf_XIX_IPA_02_XIX_E3V_K2CANFD: start 31, 1 bit, little-endian, data-type-policy=OVERRIDE, i-signal-type=PRIMITIVE, init-value=0, base-type=BT_Parken_Schluesselsuche_Anf, compu {0=Cx0_keine_Anforderung (CM_Parken_Schluesselsuche_Anf_Cx0_keine_Anforderung), 1=Cx1_Anforderung_Schluesselsuche (CM_Parken_Schluesselsuche_Anf_Cx1_Anforderung_Schluesselsuche)}, range raw 0..1, transfer-property=TRIGGERED-ON-CHANGE  # Ansteuerung der Schlüsselsuche für das pilotierte Parken.
          signal Parken_FFB_LED_Anf_XIX_IPA_02_XIX_E3V_K2CANFD: start 32, 2 bit, little-endian, data-type-policy=OVERRIDE, i-signal-type=PRIMITIVE, init-value=0, base-type=BT_Parken_FFB_LED_Anf, compu {0=Cx0_keine_Anforderung (CM_Parken_FFB_LED_Anf_Cx0_keine_Anforderung), 1=Cx1_Abbruch_Fehler (CM_Parken_FFB_LED_Anf_Cx1_Abbruch_Fehler), 2=Cx2_Bereit_OK (CM_Parken_FFB_LED_Anf_Cx2_Bereit_OK), 3=Cx3_Beendet (CM_Parken_FFB_LED_Anf_Cx3_Beendet)}, range raw 0..3, transfer-property=TRIGGERED-ON-CHANGE  # Statusinformation des Pilotierten Parkens für die Ansteuerung der LED auf der Funkfernbedienung.
          signal Parken_Wegfahrsperren_Anf_XIX_IPA_02_XIX_E3V_K2CANFD: start 34, 2 bit, little-endian, data-type-policy=OVERRIDE, i-signal-type=PRIMITIVE, init-value=0, base-type=BT_Parken_Wegfahrsperren_Anf, compu {0=Cx0_keine_Anforderung (CM_Parken_Wegfahrsperren_Anf_Cx0_keine_Anforderung), 1=Cx1_Anforderung_Fahreruebernahme (CM_Parken_Wegfahrsperren_Anf_Cx1_Anforderung_Fahreruebernahme), 2=Cx2_Anforderung_Fahreruebergabe (CM_Parken_Wegfahrsperren_Anf_Cx2_Anforderung_Fahreruebergabe)}, range raw 0..2, transfer-property=TRIGGERED-ON-CHANGE  # Ansteuerung der Wegfahrsperren Komponenten für das pilotierte Parken.
          signal Parken_Aktivierungslicht_Anf_XIX_IPA_02_XIX_E3V_K2CANFD: start 36, 1 bit, little-endian, data-type-policy=OVERRIDE, i-signal-type=PRIMITIVE, init-value=0, base-type=BT_Parken_Aktivierungslicht_Anf, compu {0=Cx0_keine_Anforderung (CM_Parken_Aktivierungslicht_Anf_Cx0_keine_Anforderung), 1=Cx1_Aktivierungslicht (CM_Parken_Aktivierungslicht_Anf_Cx1_Aktivierungslicht)}, range raw 0..1, transfer-property=TRIGGERED-ON-CHANGE  # Anforderung des Aktivierungslichts nach erfolgreicher Aktivierungshandlung seitens Pilotiertem Parken.
          signal Parken_Fahrtrichtungslicht_Anf_XIX_IPA_02_XIX_E3V_K2CANFD: start 37, 2 bit, little-endian, data-type-policy=OVERRIDE, i-signal-type=PRIMITIVE, init-value=0, base-type=BT_Parken_Fahrtrichtungslicht_Anf, compu {0=Cx0_keine_Anforderung (CM_Parken_Fahrtrichtungslicht_Anf_Cx0_keine_Anforderung), 1=Cx1_Vorwaerts (CM_Parken_Fahrtrichtungslicht_Anf_Cx1_Vorwaerts), 2=Cx2_Rueckwaerts (CM_Parken_Fahrtrichtungslicht_Anf_Cx2_Rueckwaerts)}, range raw 0..2, transfer-property=TRIGGERED-ON-CHANGE  # Anforderung seitens Pilotiertem Parken für die Anzeige der initialen Fahrtrichtung nach Systemaktivierung.
          signal Parken_Lichtnachlauf_Anf_XIX_IPA_02_XIX_E3V_K2CANFD: start 39, 1 bit, little-endian, data-type-policy=OVERRIDE, i-signal-type=PRIMITIVE, init-value=0, base-type=BT_Parken_Lichtnachlauf_Anf, compu {0=Cx0_keine_Anforderung (CM_Parken_Lichtnachlauf_Anf_Cx0_keine_Anforderung), 1=Cx1_Anforderung_Lichtnachlauf (CM_Parken_Lichtnachlauf_Anf_Cx1_Anforderung_Lichtnachlauf)}, range raw 0..1, transfer-property=TRIGGERED-ON-CHANGE  # Anforderung des Lichtnachlaufs beim BCM1 (analog Verlassenskonzept) für das Pilotierte Parken.
          signal IPA_Akustik_PL_gefunden_XIX_IPA_02_XIX_E3V_K2CANFD: start 45, 1 bit, little-endian, data-type-policy=OVERRIDE, i-signal-type=PRIMITIVE, init-value=0, base-type=BT_IPA_Akustik_PL_gefunden, compu {0=Cx0_keinen_Ton_ausgeben (CM_IPA_Akustik_PL_gefunden_Cx0_keinen_Ton_ausgeben), 1=Cx1_Ton_ausgeben (CM_IPA_Akustik_PL_gefunden_Cx1_Ton_ausgeben)}, range raw 0..1, transfer-property=PENDING  # Signalisiert ein akustische Benachrichtigung, dass Parklücken gefunden wurden.
          signal Parken_Fahrerhinweise_Anf_XIX_IPA_02_XIX_E3V_K2CANFD: start 51, 1 bit, little-endian, data-type-policy=OVERRIDE, i-signal-type=PRIMITIVE, init-value=0, base-type=BT_Parken_Fahrerhinweise_Anf, compu {0=Cx0_keine_Anforderung (CM_Parken_Fahrerhinweise_Anf_Cx0_keine_Anforderung), 1=Cx1_Fahrerhinweise_anzeigen (CM_Parken_Fahrerhinweise_Anf_Cx1_Fahrerhinweise_anzeigen)}, range raw 0..1, transfer-property=TRIGGERED-ON-CHANGE  # Anforderung zur erneuten Lampenaufprüfung und Anzeige von Warnhinweisen nach einem pilotierten Ausparkvorgang.
          signal Parken_Bestaetigungsblinken_Anf_XIX_IPA_02_XIX_E3V_K2CANFD: start 52, 2 bit, little-endian, data-type-policy=OVERRIDE, i-signal-type=PRIMITIVE, init-value=0, base-type=BT_Parken_Bestaetigungsblinken_Anf, compu {0=Cx0_keine_Anforderung (CM_Parken_Bestaetigungsblinken_Anf_Cx0_keine_Anforderung), 1=Cx1_Erfolgsblinken_Einparken (CM_Parken_Bestaetigungsblinken_Anf_Cx1_Erfolgsblinken_Einparken), 2=Cx2_Abbruchsblinken (CM_Parken_Bestaetigungsblinken_Anf_Cx2_Abbruchsblinken), 3=Cx3_Erfolgsblinken_Ausparken (CM_Parken_Bestaetigungsblinken_Anf_Cx3_Erfolgsblinken_Ausparken)}, range raw 0..3, transfer-property=TRIGGERED-ON-CHANGE  # Anforderung seitens Pilotiertem Parken für ein Erfolgsblinken nach dem Erreichen der Zielposition bzw. für ein Abbruchsblinken bei Eintreten einer Abbruchsbedingung.
          signal Parken_Fahrbereitschaftlicht_Anf_XIX_IPA_02_XIX_E3V_K2CANFD: start 54, 1 bit, little-endian, data-type-policy=OVERRIDE, i-signal-type=PRIMITIVE, init-value=0, base-type=BT_Parken_Fahrbereitschaftlicht_Anf, compu {0=Cx0_keine_Anforderung (CM_Parken_Fahrbereitschaftlicht_Anf_Cx0_keine_Anforderung), 1=Cx1_Fahrbereitschaftslicht (CM_Parken_Fahrbereitschaftlicht_Anf_Cx1_Fahrbereitschaftslicht)}, range raw 0..1, transfer-property=TRIGGERED-ON-CHANGE  # Anforderung des Fahrbereitschaftslichts
          signal Parken_Lichtsteuerung_Anf_XIX_IPA_02_XIX_E3V_K2CANFD: start 55, 1 bit, little-endian, data-type-policy=OVERRIDE, i-signal-type=PRIMITIVE, init-value=0, base-type=BT_Parken_Lichtsteuerung_Anf, compu {0=Cx0_keine_Anforderung (CM_Parken_Lichtsteuerung_Anf_Cx0_keine_Anforderung), 1=Cx1_Automatik_Lichtmodus_aktivieren (CM_Parken_Lichtsteuerung_Anf_Cx1_Automatik_Lichtmodus_aktivieren)}, range raw 0..1, transfer-property=TRIGGERED-ON-CHANGE  # Anforderung zum Setzen des Lichtmodus des Fahrzeuges von der Parkfunktion
          signal IPA_Anf_Meldungen_XIX_IPA_02_XIX_E3V_K2CANFD: start 56, 8 bit, little-endian, data-type-policy=OVERRIDE, i-signal-type=PRIMITIVE, init-value=0, base-type=BT_IPA_Anf_Meldungen, compu {0=Cx0_keine_Meldung (CM_IPA_Anf_Meldungen_Cx0_keine_Meldung) (keine Meldung), 1=Cx1_beendet (CM_IPA_Anf_Meldungen_Cx1_beendet), 2=Cx2_Fahrinf_Bremse_FT_betaetigen (CM_IPA_Anf_Meldungen_Cx2_Fahrinf_Bremse_FT_betaetigen), 3=Cx3_Suche_fortsetzen_ESC_Eingriff (CM_IPA_Anf_Meldungen_Cx3_Suche_fortsetzen_ESC_Eingriff), 4=Cx4_n_a_temp_ESC_deaktiviert (CM_IPA_Anf_Meldungen_Cx4_n_a_temp_ESC_deaktiviert), 5=Cx5_n_a_temp_Anhaengerbetrieb (CM_IPA_Anf_Meldungen_Cx5_n_a_temp_Anhaengerbetrieb), 6=Cx6_Suche_Zeitlimit_ueberschritten (CM_IPA_Anf_Meldungen_Cx6_Suche_Zeitlimit_ueberschritten), 7=Cx7_IPAAP_Touch_nicht_moegl (CM_IPA_Anf_Meldungen_Cx7_IPAAP_Touch_nicht_moegl), 8=Cx8_IPALP_nicht_verf_Kamera (CM_IPA_Anf_Meldungen_Cx8_IPALP_nicht_verf_Kamera), 9=Cx9_RPARemoteWunschAbgebrochen (CM_IPA_Anf_Meldungen_Cx9_RPARemoteWunschAbgebrochen), 10=Cxa_IPAGeschwindigkeitReduzieren (CM_IPA_Anf_Meldungen_Cxa_IPAGeschwindigkeitReduzieren), 11=Cxb_IPARPAAktivierung2 (CM_IPA_Anf_Meldungen_Cxb_IPARPAAktivierung2), 12=Cxc_AP_nicht_moeglich (CM_IPA_Anf_Meldungen_Cxc_AP_nicht_moeglich), 13=Cxd_RPAGarageStart (CM_IPA_Anf_Meldungen_Cxd_RPAGarageStart), 14=Cxe_IPAAbbruch_Suchfahrt_Tuer (CM_IPA_Anf_Meldungen_Cxe_IPAAbbruch_Suchfahrt_Tuer), 15=Cxf_Stby_Tuer_Heckklappe_schliessen (CM_IPA_Anf_Meldungen_Cxf_Stby_Tuer_Heckklappe_schliessen), 16=Cx10_PP_aktiv_nur_aussen_bedienbar (CM_IPA_Anf_Meldungen_Cx10_PP_aktiv_nur_aussen_bedienbar), 17=Cx11_IPALP (CM_IPA_Anf_Meldungen_Cx11_IPALP) (IPALP_), 18=Cx12_IPALP_nicht_verf_Spiegel (CM_IPA_Anf_Meldungen_Cx12_IPALP_nicht_verf_Spiegel), 19=Cx13_PP_Schluessel_oder_App_bedienen (CM_IPA_Anf_Meldungen_Cx13_PP_Schluessel_oder_App_bedienen), 20=Cx14_RPAUebergabe1 (CM_IPA_Anf_Meldungen_Cx14_RPAUebergabe1), 21=Cx15_PP_Schluessel_bedienen (CM_IPA_Anf_Meldungen_Cx15_PP_Schluessel_bedienen), 22=Cx16_IPAAbbruchSuchfahrt (CM_IPA_Anf_Meldungen_Cx16_IPAAbbruchSuchfahrt), 23=Cx17_IPA_Lokalisierungsfehler (CM_IPA_Anf_Meldungen_Cx17_IPA_Lokalisierungsfehler), 24=Cx18_n_a_temp_Sensorsicht (CM_IPA_Anf_Meldungen_Cx18_n_a_temp_Sensorsicht), 25=Cx19_IPAAbbruchSuchfahrtLadestecke (CM_IPA_Anf_Meldungen_Cx19_IPAAbbruchSuchfahrtLadestecke), 26=Cx1a_IPAPausierenWeiterfahrt (CM_IPA_Anf_Meldungen_Cx1a_IPAPausierenWeiterfahrt), 27=Cx1b_n_a_temp_FAS_aktiv (CM_IPA_Anf_Meldungen_Cx1b_n_a_temp_FAS_aktiv), 28=Cx1c_PP_BT_unterbrochen (CM_IPA_Anf_Meldungen_Cx1c_PP_BT_unterbrochen), 29=Cx1d_Hindernis_in_Fahrtrichtung (CM_IPA_Anf_Meldungen_Cx1d_Hindernis_in_Fahrtrichtung), 30=Cx1e_IPAAusparkenBlinker (CM_IPA_Anf_Meldungen_Cx1e_IPAAusparkenBlinker), 31=Cx1f_RPAUebernahme (CM_IPA_Anf_Meldungen_Cx1f_RPAUebernahme), 32=Cx20_Suche_Rangierflaeche_zu_klein (CM_IPA_Anf_Meldungen_Cx20_Suche_Rangierflaeche_zu_klein), 33=Cx21_n_a_temp_Drive_Select (CM_IPA_Anf_Meldungen_Cx21_n_a_temp_Drive_Select), 34=Cx22_IPAAktivierung1 (CM_IPA_Anf_Meldungen_Cx22_IPAAktivierung1), 35=Cx23_Fahrinf_Fahrtrichtungswechsel (CM_IPA_Anf_Meldungen_Cx23_Fahrinf_Fahrtrichtungswechsel), 36=Cx24_RPARemoteWunsch (CM_IPA_Anf_Meldungen_Cx24_RPARemoteWunsch), 37=Cx25_GP_Fzgposition_vor_Garage (CM_IPA_Anf_Meldungen_Cx25_GP_Fzgposition_vor_Garage), 38=Cx26_GP_RT_Garage_oeffnen (CM_IPA_Anf_Meldungen_Cx26_GP_RT_Garage_oeffnen), 39=Cx27_GP_Kein_Zuparken (CM_IPA_Anf_Meldungen_Cx27_GP_Kein_Zuparken), 40=Cx28_Suche_Fahrinfo_beachten (CM_IPA_Anf_Meldungen_Cx28_Suche_Fahrinfo_beachten), 41=Cx29_GP_Fzgposition_freie_Parkflaeche (CM_IPA_Anf_Meldungen_Cx29_GP_Fzgposition_freie_Parkflaeche), 42=Cx2a_GP_n_a_temp_Laser (CM_IPA_Anf_Meldungen_Cx2a_GP_n_a_temp_Laser), 43=Cx2b_Geschwindigkeitsueberschreitung (CM_IPA_Anf_Meldungen_Cx2b_Geschwindigkeitsueberschreitung), 44=Cx2c_Fahrinf_Weiter_vorfahren (CM_IPA_Anf_Meldungen_Cx2c_Fahrinf_Weiter_vorfahren), 45=Cx2d_RPAAktivierung1 (CM_IPA_Anf_Meldungen_Cx2d_RPAAktivierung1), 46=Cx2e_Fahrinf_Anhalten (CM_IPA_Anf_Meldungen_Cx2e_Fahrinf_Anhalten), 47=Cx2f_GP_AP_nicht_moeglich_Fahrweg (CM_IPA_Anf_Meldungen_Cx2f_GP_AP_nicht_moeglich_Fahrweg), 48=Cx30_RPAAbbruch_RGang (CM_IPA_Anf_Meldungen_Cx30_RPAAbbruch_RGang), 49=Cx31_IPAAP_Blinker_Touch (CM_IPA_Anf_Meldungen_Cx31_IPAAP_Blinker_Touch), 50=Cx32_IPAEingeparkt_Linieueberschrit (CM_IPA_Anf_Meldungen_Cx32_IPAEingeparkt_Linieueberschrit), 128=Cx80_Disclaimer_LP_rechts (CM_IPA_Anf_Meldungen_Cx80_Disclaimer_LP_rechts), 129=Cx81_Disclaimer_LP_links (CM_IPA_Anf_Meldungen_Cx81_Disclaimer_LP_links), 130=Cx82_Disclaimer_RQ_rechts (CM_IPA_Anf_Meldungen_Cx82_Disclaimer_RQ_rechts), 131=Cx83_Disclaimer_RQ_links (CM_IPA_Anf_Meldungen_Cx83_Disclaimer_RQ_links), 132=Cx84_Disclaimer_VQ_rechts (CM_IPA_Anf_Meldungen_Cx84_Disclaimer_VQ_rechts), 133=Cx85_Disclaimer_VQ_links (CM_IPA_Anf_Meldungen_Cx85_Disclaimer_VQ_links), 134=Cx86_Disclaimer_AP_rechts (CM_IPA_Anf_Meldungen_Cx86_Disclaimer_AP_rechts), 135=Cx87_Disclaimer_AP_links (CM_IPA_Anf_Meldungen_Cx87_Disclaimer_AP_links), 136=Cx88_IPARPAAktivierung3 (CM_IPA_Anf_Meldungen_Cx88_IPARPAAktivierung3), 137=Cx89_IPAAbbruchLenkeingriff (CM_IPA_Anf_Meldungen_Cx89_IPAAbbruchLenkeingriff), 138=Cx8a_IPAAbbruchAnhaenger (CM_IPA_Anf_Meldungen_Cx8a_IPAAbbruchAnhaenger), 139=Cx8b_IPARPAAktivierung4 (CM_IPA_Anf_Meldungen_Cx8b_IPARPAAktivierung4), 140=Cx8c_IPAAbbruchZeitlimit (CM_IPA_Anf_Meldungen_Cx8c_IPAAbbruchZeitlimit), 141=Cx8d_IPAFahrzeugAusgeparkt (CM_IPA_Anf_Meldungen_Cx8d_IPAFahrzeugAusgeparkt), 142=Cx8e_IPAFahrzeugEingeparkt (CM_IPA_Anf_Meldungen_Cx8e_IPAFahrzeugEingeparkt), 143=Cx8f_IPAPausieren (CM_IPA_Anf_Meldungen_Cx8f_IPAPausieren), 144=Cx90_IPAAbbruchESC (CM_IPA_Anf_Meldungen_Cx90_IPAAbbruchESC), 145=Cx91_Stby_Verkehr_erkannt (CM_IPA_Anf_Meldungen_Cx91_Stby_Verkehr_erkannt), 146=Cx92_MAAbbruchLenkeingriff (CM_IPA_Anf_Meldungen_Cx92_MAAbbruchLenkeingriff), 147=Cx93_IPAAbbruchSchaltung (CM_IPA_Anf_Meldungen_Cx93_IPAAbbruchSchaltung), 148=Cx94_IPAAbbruchParklueckeKlein (CM_IPA_Anf_Meldungen_Cx94_IPAAbbruchParklueckeKlein), 149=Cx95_IPASteigung_zu_gross (CM_IPA_Anf_Meldungen_Cx95_IPASteigung_zu_gross), 150=Cx96_IPAAbbruchSensorsicht (CM_IPA_Anf_Meldungen_Cx96_IPAAbbruchSensorsicht), 151=Cx97_Beendet_Stoerung_Fzgverbindung (CM_IPA_Anf_Meldungen_Cx97_Beendet_Stoerung_Fzgverbindung), 152=Cx98_Beendet_selbst_bremsen (CM_IPA_Anf_Meldungen_Cx98_Beendet_selbst_bremsen), 153=Cx99_IPAAbbruchFahrdynamischerEing (CM_IPA_Anf_Meldungen_Cx99_IPAAbbruchFahrdynamischerEing), 154=Cx9a_IPAAbbruchFalscheBewegungsric (CM_IPA_Anf_Meldungen_Cx9a_IPAAbbruchFalscheBewegungsric), 155=Cx9b_IPAAbbruchDiETaSchliesskreuz (CM_IPA_Anf_Meldungen_Cx9b_IPAAbbruchDiETaSchliesskreuz), 156=Cx9c_IPAPausierenHindernis (CM_IPA_Anf_Meldungen_Cx9c_IPAPausierenHindernis), 157=Cx9d_FUEN_moeglich (CM_IPA_Anf_Meldungen_Cx9d_FUEN_moeglich), 158=Cx9e_IPABordsteinheber4 (CM_IPA_Anf_Meldungen_Cx9e_IPABordsteinheber4), 159=Cx9f_IPAAbbruchOffroadModus (CM_IPA_Anf_Meldungen_Cx9f_IPAAbbruchOffroadModus), 160=Cxa0_IPAAusparken_Seiteversperrt (CM_IPA_Anf_Meldungen_Cxa0_IPAAusparken_Seiteversperrt), 161=Cxa1_PP_Fehler_Schluesselautorisier (CM_IPA_Anf_Meldungen_Cxa1_PP_Fehler_Schluesselautorisier), 162=Cxa2_IPASuchfahrt (CM_IPA_Anf_Meldungen_Cxa2_IPASuchfahrt), 163=Cxa3_IPABordsteinheber7 (CM_IPA_Anf_Meldungen_Cxa3_IPABordsteinheber7), 164=Cxa4_IPAAbbruch_Zuendung_aus (CM_IPA_Anf_Meldungen_Cxa4_IPAAbbruch_Zuendung_aus), 165=Cxa5_Stby_Hindernis_Richtungswechsel (CM_IPA_Anf_Meldungen_Cxa5_Stby_Hindernis_Richtungswechsel), 166=Cxa6_Stby_erhoehter_Fahrwiderstand (CM_IPA_Anf_Meldungen_Cxa6_Stby_erhoehter_Fahrwiderstand), 167=Cxa7_Abbruch_EPB_aktiviert (CM_IPA_Anf_Meldungen_Cxa7_Abbruch_EPB_aktiviert), 168=Cxa8_Abbruch_MO_nicht_bereit (CM_IPA_Anf_Meldungen_Cxa8_Abbruch_MO_nicht_bereit), 169=Cxa9_IPAAbbruchPDC (CM_IPA_Anf_Meldungen_Cxa9_IPAAbbruchPDC), 170=Cxaa_Abbruch_Gurtschloss_gesteckt (CM_IPA_Anf_Meldungen_Cxaa_Abbruch_Gurtschloss_gesteckt), 171=Cxab_IPAAbbruchGeschwindigkeitHoch (CM_IPA_Anf_Meldungen_Cxab_IPAAbbruchGeschwindigkeitHoch), 172=Cxac_IPAPausierenTueren (CM_IPA_Anf_Meldungen_Cxac_IPAPausierenTueren), 173=Cxad_IPAAbbruchNotstopp (CM_IPA_Anf_Meldungen_Cxad_IPAAbbruchNotstopp), 174=Cxae_IPAAbbruchFahrerabwesenheit (CM_IPA_Anf_Meldungen_Cxae_IPAAbbruchFahrerabwesenheit), 175=Cxaf_IPAAbbruch_Fluchtfunktion (CM_IPA_Anf_Meldungen_Cxaf_IPAAbbruch_Fluchtfunktion), 176=Cxb0_IPAAbbruch_Fahrzeuglokalisierung (CM_IPA_Anf_Meldungen_Cxb0_IPAAbbruch_Fahrzeuglokalisierung), 177=Cxb1_PosOK_Lenkrad_loslassen_FT (CM_IPA_Anf_Meldungen_Cxb1_PosOK_Lenkrad_loslassen_FT), 178=Cxb2_IPA_Wiederaufnahme (CM_IPA_Anf_Meldungen_Cxb2_IPA_Wiederaufnahme), 179=Cxb3_IPABordsteinheber9 (CM_IPA_Anf_Meldungen_Cxb3_IPABordsteinheber9), 180=Cxb4_RPA_ChildPresenceDetection (CM_IPA_Anf_Meldungen_Cxb4_RPA_ChildPresenceDetection), 181=Cxb5_IPABordsteinheber8 (CM_IPA_Anf_Meldungen_Cxb5_IPABordsteinheber8), 192=Cxc0_TPA_aborted_deviated_from_trajec (CM_IPA_Anf_Meldungen_Cxc0_TPA_aborted_deviated_from_trajec), 193=Cxc1_TPA_aborted_limited_visibility (CM_IPA_Anf_Meldungen_Cxc1_TPA_aborted_limited_visibility), 194=Cxc2_TPA_aborted_localization_failure (CM_IPA_Anf_Meldungen_Cxc2_TPA_aborted_localization_failure), 195=Cxc3_TPA_aborted_System_error (CM_IPA_Anf_Meldungen_Cxc3_TPA_aborted_System_error), 196=Cxc4_TPA_aborted_TPA_canceled (CM_IPA_Anf_Meldungen_Cxc4_TPA_aborted_TPA_canceled), 197=Cxc5_TPA_unavlbl_localization_failure (CM_IPA_Anf_Meldungen_Cxc5_TPA_unavlbl_localization_failure), 198=Cxc6_TPA_unavlbl_limited_visibility (CM_IPA_Anf_Meldungen_Cxc6_TPA_unavlbl_limited_visibility), 199=Cxc7_TPA_unavlbl_System_error (CM_IPA_Anf_Meldungen_Cxc7_TPA_unavlbl_System_error), 200=Cxc8_TPA_temp_unavailable (CM_IPA_Anf_Meldungen_Cxc8_TPA_temp_unavailable), 201=Cxc9_rTPA_nicht_verfuegbar_TPA_bis_ZP (CM_IPA_Anf_Meldungen_Cxc9_rTPA_nicht_verfuegbar_TPA_bis_ZP), 202=Cxca_TPA_PP_belegt_TPA_Altern (CM_IPA_Anf_Meldungen_Cxca_TPA_PP_belegt_TPA_Altern), 203=Cxcb_TPA_PP_belegt_IPA_0_Altern (CM_IPA_Anf_Meldungen_Cxcb_TPA_PP_belegt_IPA_0_Altern), 204=Cxcc_TPA_PP_belegt_IPA_1_Altern (CM_IPA_Anf_Meldungen_Cxcc_TPA_PP_belegt_IPA_1_Altern), 205=Cxcd_TPA_PP_belegt_IPA_mehr_Altern (CM_IPA_Anf_Meldungen_Cxcd_TPA_PP_belegt_IPA_mehr_Altern), 206=Cxce_TPA_ausgerichtetes_Parken_aktiv (CM_IPA_Anf_Meldungen_Cxce_TPA_ausgerichtetes_Parken_aktiv), 207=Cxcf_TPA_Ausparken_eingeschraenkt (CM_IPA_Anf_Meldungen_Cxcf_TPA_Ausparken_eingeschraenkt)}, range raw 0..207, transfer-property=TRIGGERED-ON-CHANGE  # Das Signal fordert die Anzeige einer Meldung an. Jedem Signalwert ist eine Meldung zugeordnet. Das Signal ist derzeit für die Funktionen IPA/RPA und TPA implementiert.
      frame ISO_BCM1_Req_XIX_E3V_K2CANFD: id 0x70E, to SAM, frame-length=8, can-addressing-mode=STANDARD, can-frame-rx-behavior=CAN-FD, can-frame-tx-behavior=CAN-FD
        n pdu ISO_BCM1_Req_XIX_E3V_K2CANFD: length=8
      frame ISO_BCM1_Resp_XIX_E3V_K2CANFD: id 0x778, from SAM, frame-length=8, can-addressing-mode=STANDARD, can-frame-rx-behavior=CAN-FD, can-frame-tx-behavior=CAN-FD
        n pdu ISO_BCM1_Resp_XIX_E3V_K2CANFD: length=8
      frame ISO_Funktionaler_Req_All_XIX_E3V_K2CANFD: id 0x700, to SAM, frame-length=8, can-addressing-mode=STANDARD, can-frame-rx-behavior=CAN-FD, can-frame-tx-behavior=CAN-FD
        n pdu ISO_Funktionaler_Req_All_XIX_E3V_K2CANFD: length=8
      frame ISOx_BCM1_Req_FD_XIX_E3V_K2CANFD: id 0x1C40000E, to SAM, frame-length=64, can-addressing-mode=EXTENDED, can-frame-rx-behavior=CAN-FD, can-frame-tx-behavior=CAN-FD
        n pdu ISOx_BCM1_Req_FD_XIX_E3V_K2CANFD: length=64
      frame ISOx_BCM1_Resp_FD_XIX_E3V_K2CANFD: id 0x1C42000E, from SAM, frame-length=64, can-addressing-mode=EXTENDED, can-frame-rx-behavior=CAN-FD, can-frame-tx-behavior=CAN-FD
        n pdu ISOx_BCM1_Resp_FD_XIX_E3V_K2CANFD: length=64
      frame ISOx_Funkt_Req_All_FD_XIX_E3V_K2CANFD: id 0x1C410000, to SAM, frame-length=64, can-addressing-mode=EXTENDED, can-frame-rx-behavior=CAN-FD, can-frame-tx-behavior=CAN-FD
        n pdu ISOx_Funkt_Req_All_FD_XIX_E3V_K2CANFD: length=64
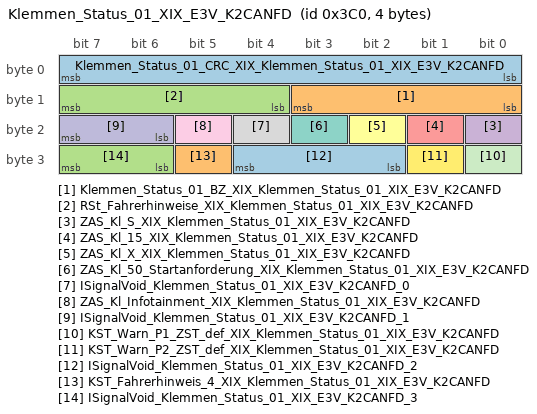
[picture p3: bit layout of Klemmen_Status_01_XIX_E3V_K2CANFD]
      frame Klemmen_Status_01_XIX_E3V_K2CANFD: id 0x3C0, to SAM, frame-length=4, can-addressing-mode=STANDARD, can-frame-rx-behavior=CAN-FD, can-frame-tx-behavior=CAN-FD
        pdu Klemmen_Status_01_XIX_E3V_K2CANFD_E2E: length=4, minimum-delay=0.01, transmission-mode-true-timing=event-controlled-timing={number-of-repetitions=0, repetition-period=0.0}, unused-bit-pattern=0  # Fuer die Botschaft ist das Cyclic-Timing 0.1 zu verwenden.
          signal Klemmen_Status_01_CRC_XIX_Klemmen_Status_01_XIX_E3V_K2CANFD: start 0, 8 bit, little-endian, data-type-policy=OVERRIDE, i-signal-type=PRIMITIVE, base-type=BT_Klemmen_Status_01_CRC, compu {phys=raw for raw 0..255}, range phys 0..255, raw 0..255, to SAM(timeout 1 s)  # Für MLB: "Berechnung siehe Lastenheft "Kommunikationsabsicherung für FlexRay und CAN"" Ab MQB und MLBevo: "Berechnung siehe Lastenheft "End-to-End Kommunikationsabsicherung"" Endwerte siehe Begleitdokument "S-PDU Kennungsfolgen"
          signal Klemmen_Status_01_BZ_XIX_Klemmen_Status_01_XIX_E3V_K2CANFD: start 8, 4 bit, little-endian, data-type-policy=OVERRIDE, i-signal-type=PRIMITIVE, base-type=BT_Klemmen_Status_01_BZ, compu {phys=raw for raw 0..15}, range phys 0..15, raw 0..15, to SAM(timeout 1 s)  # 4bit Botschaftszaehler; wird in jeder Sendebotschaft inkrementiert
          signal RSt_Fahrerhinweise_XIX_Klemmen_Status_01_XIX_E3V_K2CANFD: start 12, 4 bit, little-endian, data-type-policy=OVERRIDE, i-signal-type=PRIMITIVE, init-value=0, base-type=BT_RSt_Fahrerhinweise, compu {0=Cx0_Init (CM_RSt_Fahrerhinweise_Cx0_Init), 1=Cx1_Fahreruebernahme_Hinweis_ZAT_Automat_ohne_Gong (CM_RSt_Fahrerhinweise_Cx1_Fahreruebernahme_Hinweis_ZAT_Automat_ohne_Gong), 2=Cx2_Fahreruebernahme_Hinweis_ZAT_Automat_mit_Gong (CM_RSt_Fahrerhinweise_Cx2_Fahreruebernahme_Hinweis_ZAT_Automat_mit_Gong), 3=Cx3_Fahreruebernahme_Hinweis_ZAT_Handschalter_ohne_Gong (CM_RSt_Fahrerhinweise_Cx3_Fahreruebernahme_Hinweis_ZAT_Handschalter_ohne_Gong), 4=Cx4_Fahreruebernahme_Hinweis_ZAT_Handschalter_mit_Gong (CM_RSt_Fahrerhinweise_Cx4_Fahreruebernahme_Hinweis_ZAT_Handschalter_mit_Gong), 5=Cx5_Fahreruebernahme_Hinweis_ZAS_Automat_ohne_Gong (CM_RSt_Fahrerhinweise_Cx5_Fahreruebernahme_Hinweis_ZAS_Automat_ohne_Gong), 6=Cx6_Fahreruebernahme_Hinweis_ZAS_Automat_mit_Gong (CM_RSt_Fahrerhinweise_Cx6_Fahreruebernahme_Hinweis_ZAS_Automat_mit_Gong), 7=Cx7_Fahreruebernahme_Hinweis_ZAS_Handschalter_ohne_Gong (CM_RSt_Fahrerhinweise_Cx7_Fahreruebernahme_Hinweis_ZAS_Handschalter_ohne_Gong), 8=Cx8_Fahreruebernahme_Hinweis_ZAS_Handschalter_mit_Gong (CM_RSt_Fahrerhinweise_Cx8_Fahreruebernahme_Hinweis_ZAS_Handschalter_mit_Gong), 9=Cx9_RemoteStart_aktiv_ohne_Gong (CM_RSt_Fahrerhinweise_Cx9_RemoteStart_aktiv_ohne_Gong), 10=Cxa_RemoteStart_aktiv_mit_Gong (CM_RSt_Fahrerhinweise_Cxa_RemoteStart_aktiv_mit_Gong), 11=Cxb_void (CM_RSt_Fahrerhinweise_Cxb_void), 12=Cxc_void (CM_RSt_Fahrerhinweise_Cxc_void), 13=Cxd_void (CM_RSt_Fahrerhinweise_Cxd_void), 14=Cxe_void (CM_RSt_Fahrerhinweise_Cxe_void), 15=Cxf_void (CM_RSt_Fahrerhinweise_Cxf_void)}, range raw 0..15  # Über das Signal fordert das BCM Fahrerhinweise im Kombi für die Funktion RemoteStart an.
          signal ZAS_Kl_S_XIX_Klemmen_Status_01_XIX_E3V_K2CANFD: start 16, 1 bit, little-endian, data-type-policy=OVERRIDE, i-signal-type=PRIMITIVE, init-value=0, base-type=BT_ZAS_Kl_S, compu {0=Cx0_aus (CM_ZAS_Kl_S_Cx0_aus), 1=Cx1_S_Kontakt_ein (CM_ZAS_Kl_S_Cx1_S_Kontakt_ein)}, range raw 0..1, to SAM(timeout 1 s)  # Klemme S: S-Kontakt (Schluessel steckt)
          signal ZAS_Kl_15_XIX_Klemmen_Status_01_XIX_E3V_K2CANFD: start 17, 1 bit, little-endian, data-type-policy=OVERRIDE, i-signal-type=PRIMITIVE, init-value=0, base-type=BT_ZAS_Kl_15, compu {0=Cx0_aus (CM_ZAS_Kl_15_Cx0_aus), 1=Cx1_ein (CM_ZAS_Kl_15_Cx1_ein)}, range raw 0..1, to SAM(timeout 1 s)  # Klemme 15: Zuendung (SW-Kl.15)
          signal ZAS_Kl_X_XIX_Klemmen_Status_01_XIX_E3V_K2CANFD: start 18, 1 bit, little-endian, data-type-policy=OVERRIDE, i-signal-type=PRIMITIVE, init-value=0, base-type=BT_ZAS_Kl_X, compu {0=Cx0_aus (CM_ZAS_Kl_X_Cx0_aus), 1=Cx1_ein (CM_ZAS_Kl_X_Cx1_ein)}, range raw 0..1, to SAM  # Klemme 75
          signal ZAS_Kl_50_Startanforderung_XIX_Klemmen_Status_01_XIX_E3V_K2CANFD: start 19, 1 bit, little-endian, data-type-policy=OVERRIDE, i-signal-type=PRIMITIVE, init-value=0, base-type=BT_ZAS_Kl_50_Startanforderung, compu {0=Cx0_aus (CM_ZAS_Kl_50_Startanforderung_Cx0_aus), 1=Cx1_KL50_ein_Startwunsch_Fahrer (CM_ZAS_Kl_50_Startanforderung_Cx1_KL50_ein_Startwunsch_Fahrer)}, range raw 0..1  # Klemme 50: Startwunsch Fahrer
          signal ISignalVoid_Klemmen_Status_01_XIX_E3V_K2CANFD_0: start 20, 1 bit, little-endian, system signal SignalVoid_Klemmen_Status_01_0, data-type-policy=OVERRIDE, i-signal-type=PRIMITIVE, base-type=BT_SignalVoid
          signal ZAS_Kl_Infotainment_XIX_Klemmen_Status_01_XIX_E3V_K2CANFD: start 21, 1 bit, little-endian, data-type-policy=OVERRIDE, i-signal-type=PRIMITIVE, init-value=0, base-type=BT_ZAS_Kl_Infotainment, compu {0=Cx0_inaktiv (CM_ZAS_Kl_Infotainment_Cx0_inaktiv), 1=Cx1_aktiv (CM_ZAS_Kl_Infotainment_Cx1_aktiv)}, range raw 0..1  # Separate Klemmeninformation für das Infotainment. Signal entspricht im wesentlichen einer Klemme S Information, kann aber über einen Vor - bzw. Nachlauf zu Klemme S verfügen. Ein konkreter Anwendungsfall für einen Nachlauf ist die Abschaltung der Klemme 15 über Verlassenskonzept, bei der ein Nachlauf des Infotainments benötigt wird.
          signal ISignalVoid_Klemmen_Status_01_XIX_E3V_K2CANFD_1: start 22, 2 bit, little-endian, system signal SignalVoid_Klemmen_Status_01_1, data-type-policy=OVERRIDE, i-signal-type=PRIMITIVE, base-type=BT_SignalVoid
          signal KST_Warn_P1_ZST_def_XIX_Klemmen_Status_01_XIX_E3V_K2CANFD: start 24, 1 bit, little-endian, data-type-policy=OVERRIDE, i-signal-type=PRIMITIVE, init-value=0, base-type=BT_KST_Warn_P1_ZST_def, compu {0=Cx0_nicht_defekt (CM_KST_Warn_P1_ZST_def_Cx0_nicht_defekt), 1=Cx1_defekt (CM_KST_Warn_P1_ZST_def_Cx1_defekt)}, range raw 0..1  # Kombi Prio Warnung Klemmensteuerung Zündschloß defekt, Service aufsuchen!
          signal KST_Warn_P2_ZST_def_XIX_Klemmen_Status_01_XIX_E3V_K2CANFD: start 25, 1 bit, little-endian, data-type-policy=OVERRIDE, i-signal-type=PRIMITIVE, init-value=0, base-type=BT_KST_Warn_P2_ZST_def, compu {0=Cx0_nicht_defekt (CM_KST_Warn_P2_ZST_def_Cx0_nicht_defekt), 1=Cx1_defekt (CM_KST_Warn_P2_ZST_def_Cx1_defekt)}, range raw 0..1  # Kombi Prio Warnung Klemmensteuerung Zündschloß defekt!
          signal ISignalVoid_Klemmen_Status_01_XIX_E3V_K2CANFD_2: start 26, 3 bit, little-endian, system signal SignalVoid_Klemmen_Status_01_2, data-type-policy=OVERRIDE, i-signal-type=PRIMITIVE, base-type=BT_SignalVoid
          signal KST_Fahrerhinweis_4_XIX_Klemmen_Status_01_XIX_E3V_K2CANFD: start 29, 1 bit, little-endian, data-type-policy=OVERRIDE, i-signal-type=PRIMITIVE, init-value=0, base-type=BT_KST_Fahrerhinweis_4, compu {0=Cx0_inaktiv (CM_KST_Fahrerhinweis_4_Cx0_inaktiv), 1=Cx1_aktiv (CM_KST_Fahrerhinweis_4_Cx1_aktiv)}, range raw 0..1  # Signalisierung Fahrerhinweis 4 der Klemmensteuerung an das Kombi
          signal ISignalVoid_Klemmen_Status_01_XIX_E3V_K2CANFD_3: start 30, 2 bit, little-endian, system signal SignalVoid_Klemmen_Status_01_3, data-type-policy=OVERRIDE, i-signal-type=PRIMITIVE, base-type=BT_SignalVoid
          mapping SG_Klemmen_Status_01_XIX_E3V_K2CANFD: i-signal-group=SG_Klemmen_Status_01_XIX_E3V_K2CANFD, transfer-property=TRIGGERED-WITHOUT-REPETITION
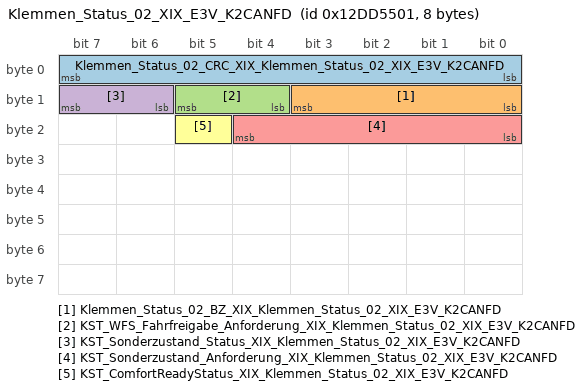
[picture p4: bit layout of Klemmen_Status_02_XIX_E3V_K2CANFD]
      frame Klemmen_Status_02_XIX_E3V_K2CANFD: id 0x12DD5501, to SAM, frame-length=8, can-addressing-mode=EXTENDED, can-frame-rx-behavior=CAN-FD, can-frame-tx-behavior=CAN-FD
        pdu Klemmen_Status_02_XIX_E3V_K2CANFD: length=8, minimum-delay=0.01, transmission-mode-true-timing={cyclic-timing={time-offset=0.0, time-period=1.0}, event-controlled-timing={number-of-repetitions=5, repetition-period=0.1}}, unused-bit-pattern=0
          signal Klemmen_Status_02_CRC_XIX_Klemmen_Status_02_XIX_E3V_K2CANFD: start 0, 8 bit, little-endian, data-type-policy=OVERRIDE, i-signal-type=PRIMITIVE, base-type=BT_Klemmen_Status_02_CRC, compu {phys=raw for raw 0..255}, range phys 0..255, raw 0..255, transfer-property=PENDING  # Für MLB: Berechnung siehe Lastenheft "Kommunikationsabsicherung für FlexRay und CAN" Ab MQB und MLBevo: Berechnung siehe Lastenheft "End-to-End Kommunikationsabsicherung" Endwerte siehe Begleitdokument "S-PDU Kennungsfolgen"
          signal Klemmen_Status_02_BZ_XIX_Klemmen_Status_02_XIX_E3V_K2CANFD: start 8, 4 bit, little-endian, data-type-policy=OVERRIDE, i-signal-type=PRIMITIVE, base-type=BT_Klemmen_Status_02_BZ, compu {phys=raw for raw 0..15}, range phys 0..15, raw 0..15, transfer-property=PENDING  # 4bit Botschaftszähler, wird mit jeder Sendebotschaft inkrementiert
          signal KST_WFS_Fahrfreigabe_Anforderung_XIX_Klemmen_Status_02_XIX_E3V_K2CANFD: start 12, 2 bit, little-endian, data-type-policy=OVERRIDE, i-signal-type=PRIMITIVE, init-value=0, base-type=BT_KST_WFS_Fahrfreigabe_Anforderung, compu {0=Cx0_Keine (CM_KST_WFS_Fahrfreigabe_Anforderung_Cx0_Keine), 1=Cx1_Uneingeschraenkt (CM_KST_WFS_Fahrfreigabe_Anforderung_Cx1_Uneingeschraenkt), 2=Cx2_Eingeschraenkt (CM_KST_WFS_Fahrfreigabe_Anforderung_Cx2_Eingeschraenkt)}, range raw 0..2, transfer-property=TRIGGERED-ON-CHANGE  # Hiermit wird den Wegfahrsperren-Teilnehmern signalisiert welche Art der Fahrfreigabe von der anfordernden Sonderfunktion benötigt wird
          signal KST_Sonderzustand_Status_XIX_Klemmen_Status_02_XIX_E3V_K2CANFD: start 14, 2 bit, little-endian, data-type-policy=OVERRIDE, i-signal-type=PRIMITIVE, init-value=0, base-type=BT_KST_Sonderzustand_Status, invalid-value=Invalid_KST_Sonderzustand_Status_XIX_Klemmen_Status_02_XIX_E3V_K2CANFD:3, compu {0=Cx0_Init (CM_KST_Sonderzustand_Status_Cx0_Init), 1=Cx1_Uebergang_neue_Anforderung (CM_KST_Sonderzustand_Status_Cx1_Uebergang_neue_Anforderung), 2=Cx2_Aktiv (CM_KST_Sonderzustand_Status_Cx2_Aktiv), 3=Cx3_Fehler (CM_KST_Sonderzustand_Status_Cx3_Fehler)}, range raw 0..3, transfer-property=TRIGGERED-ON-CHANGE, to SAM(timeout 5 s)  # Hiermit wird signalisiert, dass eine Sonderfunktion aktiv ist und die Klemme 15 durch diese angefordert wurde bzw. ein Übergang von Sonderfunktionen stattfindet
          signal KST_Sonderzustand_Anforderung_XIX_Klemmen_Status_02_XIX_E3V_K2CANFD: start 16, 5 bit, little-endian, data-type-policy=OVERRIDE, i-signal-type=PRIMITIVE, init-value=0, base-type=BT_KST_Sonderzustand_Anforderung, invalid-value=Invalid_KST_Sonderzustand_Anforderung_XIX_Klemmen_Status_02_XIX_E3V_K2CANFD:31, compu {0=Cx0_Init (CM_KST_Sonderzustand_Anforderung_Cx0_Init), 1=Cx1_RemoteStart (CM_KST_Sonderzustand_Anforderung_Cx1_RemoteStart), 2=Cx2_RemoteParkAssist (CM_KST_Sonderzustand_Anforderung_Cx2_RemoteParkAssist), 3=Cx3_IntelligentParkAssist (CM_KST_Sonderzustand_Anforderung_Cx3_IntelligentParkAssist), 4=Cx4_TrainiertesParken (CM_KST_Sonderzustand_Anforderung_Cx4_TrainiertesParken), 5=Cx5_OnlineRemoteUpdate (CM_KST_Sonderzustand_Anforderung_Cx5_OnlineRemoteUpdate), 6=Cx6_Einfrierschutz (CM_KST_Sonderzustand_Anforderung_Cx6_Einfrierschutz), 7=Cx7_Klemme15ViaDiagnose (CM_KST_Sonderzustand_Anforderung_Cx7_Klemme15ViaDiagnose), 8=Cx8_RueckwandklappenSicherungPDC (CM_KST_Sonderzustand_Anforderung_Cx8_RueckwandklappenSicherungPDC), 9=Cx9_ParkHausPilot (CM_KST_Sonderzustand_Anforderung_Cx9_ParkHausPilot), 10=Cxa_AnhaengerAnkuppelAssistent (CM_KST_Sonderzustand_Anforderung_Cxa_AnhaengerAnkuppelAssistent), 11=Cxb_MotorWeiterlaufSchaltung (CM_KST_Sonderzustand_Anforderung_Cxb_MotorWeiterlaufSchaltung), 12=Cxc_RemoteActivationDeactivationAD (CM_KST_Sonderzustand_Anforderung_Cxc_RemoteActivationDeactivationAD), 31=Cx1f_Fehler (CM_KST_Sonderzustand_Anforderung_Cx1f_Fehler)}, range raw 0..31, transfer-property=TRIGGERED-ON-CHANGE, to SAM(timeout 5 s)  # Hiermit wird die aktive bzw. aktuell angeforderte (s. KST_Sonderzustand_Status) Sonderfunktion identifiziert
          signal KST_ComfortReadyStatus_XIX_Klemmen_Status_02_XIX_E3V_K2CANFD: start 21, 1 bit, little-endian, data-type-policy=OVERRIDE, i-signal-type=PRIMITIVE, init-value=0, base-type=BT_KST_ComfortReadyStatus, compu {0=Cx0_aus (CM_KST_ComfortReadyStatus_Cx0_aus), 1=Cx1_ComfortReadyStatus_ein (CM_KST_ComfortReadyStatus_Cx1_ComfortReadyStatus_ein)}, range raw 0..1, transfer-property=TRIGGERED-ON-CHANGE  # Zustand des ComfortReadyStatus über den Komfortfunktionen aktiviert werden können.
      frame Klemmen_Steuerung_01_XIX_E3V_K2CANFD: id 0x58C, to SAM, frame-length=8, can-addressing-mode=STANDARD, can-frame-rx-behavior=CAN-FD, can-frame-tx-behavior=CAN-FD
        pdu Klemmen_Steuerung_01_XIX_E3V_K2CANFD_E2E: length=8, minimum-delay=0.01, transmission-mode-true-timing=event-controlled-timing={number-of-repetitions=0, repetition-period=0.0}, unused-bit-pattern=0  # Fuer die Botschaft ist das Cyclic-Timing 1.0 zu verwenden.
          signal Klemmen_Steuerung_01_CRC_XIX_Klemmen_Steuerung_01_XIX_E3V_K2CANFD: start 0, 8 bit, little-endian, data-type-policy=OVERRIDE, i-signal-type=PRIMITIVE, base-type=BT_Klemmen_Steuerung_01_CRC, compu {phys=raw for raw 0..255}, range phys 0..255, raw 0..255, to SAM(timeout 5 s)  # Ab MQB und MLBevo: "Berechnung siehe Lastenheft "End-to-End Kommunikationsabsicherung"" Endwerte siehe Begleitdokument "S-PDU Kennungsfolgen"
          signal Klemmen_Steuerung_01_BZ_XIX_Klemmen_Steuerung_01_XIX_E3V_K2CANFD: start 8, 4 bit, little-endian, data-type-policy=OVERRIDE, i-signal-type=PRIMITIVE, base-type=BT_Klemmen_Steuerung_01_BZ, compu {phys=raw for raw 0..15}, range phys 0..15, raw 0..15, to SAM(timeout 5 s)  # 4bit Botschaftszaehler; wird in jeder Sendebotschaft inkrementiert
          signal KST_Anf_Klemme_15_XIX_Klemmen_Steuerung_01_XIX_E3V_K2CANFD: start 12, 1 bit, little-endian, data-type-policy=OVERRIDE, i-signal-type=PRIMITIVE, init-value=0, base-type=BT_KST_Anf_Klemme_15, compu {0=Cx0_nicht_angefordert (CM_KST_Anf_Klemme_15_Cx0_nicht_angefordert), 1=Cx1_angefordert (CM_KST_Anf_Klemme_15_Cx1_angefordert)}, range raw 0..1  # Anforderung der Klemme 15 an das BCM. Signal wird zur Plausibilisierung parallel zum Klemmensignal auf dem CAN übertragen.
          signal KST_Anf_Klemme_50_XIX_Klemmen_Steuerung_01_XIX_E3V_K2CANFD: start 13, 1 bit, little-endian, data-type-policy=OVERRIDE, i-signal-type=PRIMITIVE, init-value=0, base-type=BT_KST_Anf_Klemme_50, compu {0=Cx0_nicht_angefordert (CM_KST_Anf_Klemme_50_Cx0_nicht_angefordert), 1=Cx1_angefordert (CM_KST_Anf_Klemme_50_Cx1_angefordert)}, range raw 0..1  # Anforderung der Klemme 50 an das MSG. Signal wird zur Plausibilisierung parallel zum Klemmensignal auf dem CAN übertragen.
          signal KST_Anf_Klemme_S_XIX_Klemmen_Steuerung_01_XIX_E3V_K2CANFD: start 14, 1 bit, little-endian, data-type-policy=OVERRIDE, i-signal-type=PRIMITIVE, init-value=0, base-type=BT_KST_Anf_Klemme_S, compu {0=Cx0_nicht_angefordert (CM_KST_Anf_Klemme_S_Cx0_nicht_angefordert), 1=Cx1_angefordert (CM_KST_Anf_Klemme_S_Cx1_angefordert)}, range raw 0..1, to SAM(timeout 5 s)  # Anforderung der Klemme S an das BCM. Signal wird zur Plausibilisierung parallel zum Klemmensignal auf dem CAN übertragen.
          signal KST_Txt_Werkstatt_XIX_Klemmen_Steuerung_01_XIX_E3V_K2CANFD: start 15, 1 bit, little-endian, data-type-policy=OVERRIDE, i-signal-type=PRIMITIVE, init-value=0, base-type=BT_KST_Txt_Werkstatt, compu {0=Cx0_Aus (CM_KST_Txt_Werkstatt_Cx0_Aus), 1=Cx1_Ein (CM_KST_Txt_Werkstatt_Cx1_Ein)}, range raw 0..1  # Text: 'Klemmensteuerung! Werkstatt!'
          signal KST_Txt_P_Gang_XIX_Klemmen_Steuerung_01_XIX_E3V_K2CANFD: start 16, 1 bit, little-endian, data-type-policy=OVERRIDE, i-signal-type=PRIMITIVE, init-value=0, base-type=BT_KST_Txt_P_Gang, compu {0=Cx0_Aus (CM_KST_Txt_P_Gang_Cx0_Aus), 1=Cx1_Ein (CM_KST_Txt_P_Gang_Cx1_Ein)}, range raw 0..1  # Text: 'Wählhebel in Position P bringen!'
          signal KST_Txt_Panikabschaltung_XIX_Klemmen_Steuerung_01_XIX_E3V_K2CANFD: start 17, 1 bit, little-endian, data-type-policy=OVERRIDE, i-signal-type=PRIMITIVE, init-value=0, base-type=BT_KST_Txt_Panikabschaltung, compu {0=Cx0_Aus (CM_KST_Txt_Panikabschaltung_Cx0_Aus), 1=Cx1_Ein (CM_KST_Txt_Panikabschaltung_Cx1_Ein)}, range raw 0..1  # Text: 'Notabschaltung''
          signal KST_Anf_Klemmenfreigabe_ELV_XIX_Klemmen_Steuerung_01_XIX_E3V_K2CANFD: start 18, 1 bit, little-endian, data-type-policy=OVERRIDE, i-signal-type=PRIMITIVE, init-value=0, base-type=BT_KST_Anf_Klemmenfreigabe_ELV, compu {0=Cx0_nicht_angefordert (CM_KST_Anf_Klemmenfreigabe_ELV_Cx0_nicht_angefordert), 1=Cx1_angefordert (CM_KST_Anf_Klemmenfreigabe_ELV_Cx1_angefordert)}, range raw 0..1  # Klemmensteuerung fordert Klemmen-Freigabe durch die ELV an.
          signal KST_Txt_Komfortabschaltung_XIX_Klemmen_Steuerung_01_XIX_E3V_K2CANFD: start 19, 1 bit, little-endian, data-type-policy=OVERRIDE, i-signal-type=PRIMITIVE, init-value=0, base-type=BT_KST_Txt_Komfortabschaltung, compu {0=Cx0_inaktiv (CM_KST_Txt_Komfortabschaltung_Cx0_inaktiv), 1=Cx1_aktiv (CM_KST_Txt_Komfortabschaltung_Cx1_aktiv)}, range raw 0..1  # Dieses Signal fordert im Kombi die Meldung an, die den Fahrer über die ausgeführte automatische Zündungsabschaltung informiert. Signal wird für10s gesendet.
          signal KST_ZAT_betaetigt_XIX_Klemmen_Steuerung_01_XIX_E3V_K2CANFD: start 20, 1 bit, little-endian, data-type-policy=OVERRIDE, i-signal-type=PRIMITIVE, init-value=0, base-type=BT_KST_ZAT_betaetigt, compu {0=Cx0_Aus (CM_KST_ZAT_betaetigt_Cx0_Aus), 1=Cx1_Ein (CM_KST_ZAT_betaetigt_Cx1_Ein)}, range raw 0..1  # Zündanlass-Taster (ZAT) betätigt
          signal KST_Unterdr_Zuendungsmeldung_XIX_Klemmen_Steuerung_01_XIX_E3V_K2CANFD: start 21, 1 bit, little-endian, data-type-policy=OVERRIDE, i-signal-type=PRIMITIVE, init-value=0, base-type=BT_KST_Unterdr_Zuendungsmeldung, compu {0=Cx0_keine_Unterdr_der_Zuendungsmeldung (CM_KST_Unterdr_Zuendungsmeldung_Cx0_keine_Unterdr_der_Zuendungsmeldung), 1=Cx1_Unterdr_der_Zuendungsmeldung_aktiv (CM_KST_Unterdr_Zuendungsmeldung_Cx1_Unterdr_der_Zuendungsmeldung_aktiv)}, range raw 0..1  # Bei aktivem Signal soll die Zündungsmeldung durch das Kombi unterdrückt werden.
          signal KST_aut_Abschaltung_Zuendung_XIX_Klemmen_Steuerung_01_XIX_E3V_K2CANFD: start 22, 1 bit, little-endian, data-type-policy=OVERRIDE, i-signal-type=PRIMITIVE, init-value=0, base-type=BT_KST_aut_Abschaltung_Zuendung, compu {0=Cx0_Zuendung_wird_bei_Verl_nicht_deaktiviert (CM_KST_aut_Abschaltung_Zuendung_Cx0_Zuendung_wird_bei_Verl_nicht_deaktiviert), 1=Cx1_Zuendung_wird_bei_Verl_deaktiviert (CM_KST_aut_Abschaltung_Zuendung_Cx1_Zuendung_wird_bei_Verl_deaktiviert)}, range raw 0..1  # Falls bei eingeschalteter Zündung das Abblendlicht aktiv war, muss nach der automatischen Abschaltung der Kl_15 & Kl_S, dass Standlicht aktiv bleiben. Das Signal sendet die Information, dass eine automatische Abschaltung der Kl_15 und Kl_S erfogt.
          signal KST_Anf_Klemmenfreigabe_WFS_XIX_Klemmen_Steuerung_01_XIX_E3V_K2CANFD: start 23, 1 bit, little-endian, data-type-policy=OVERRIDE, i-signal-type=PRIMITIVE, init-value=0, base-type=BT_KST_Anf_Klemmenfreigabe_WFS, compu {0=Cx0_nicht_angefordert (CM_KST_Anf_Klemmenfreigabe_WFS_Cx0_nicht_angefordert), 1=Cx1_angefordert (CM_KST_Anf_Klemmenfreigabe_WFS_Cx1_angefordert)}, range raw 0..1  # Anforderung der Freigabe von der WFS zum Einschalten von Klemme 15 und Klemme S
          signal KST_Anf_ZV_Verriegelung_XIX_Klemmen_Steuerung_01_XIX_E3V_K2CANFD: start 24, 1 bit, little-endian, data-type-policy=OVERRIDE, i-signal-type=PRIMITIVE, init-value=0, base-type=BT_KST_Anf_ZV_Verriegelung, compu {0=Cx0_inaktiv (CM_KST_Anf_ZV_Verriegelung_Cx0_inaktiv), 1=Cx1_aktiv (CM_KST_Anf_ZV_Verriegelung_Cx1_aktiv)}, range raw 0..1  # Neuer Verriegelungstrigger für die ZV nach der automatischen Klemmenabschaltung. Wird bei Kessyfahrzeugen mit StartStop ein aktiver Stop-Mode und Fahrerverlassen erkannt, startet ein 30 Sekunden-Timer. Innerhalb dieser 30 Sekunden hat der Fahrer die Möglichkeit, sein Fahrzeug zu verriegeln. Nach Erkennung des Verriegelungswunsches werden die Kl_15 und Kl_S deaktiviert und die Anforderung zum Verriegeln ZV über das Signal VLK_ZV_Verriegelung an den ZV-Master gesendet.
          signal Relais_VoKo_angesteuert_XIX_Klemmen_Steuerung_01_XIX_E3V_K2CANFD: start 25, 1 bit, little-endian, data-type-policy=OVERRIDE, i-signal-type=PRIMITIVE, init-value=0, base-type=BT_Relais_VoKo_angesteuert, compu {0=Cx0_nicht_angesteuert (CM_Relais_VoKo_angesteuert_Cx0_nicht_angesteuert), 1=Cx1_angesteuert (CM_Relais_VoKo_angesteuert_Cx1_angesteuert)}, range raw 0..1  # Signal zur Rückmeldung, ob das Relais für die Verbraucher von erweiterte Voko / RemoteStart angesteuert wird.
          signal RSt_Anforderung_HMS_XIX_Klemmen_Steuerung_01_XIX_E3V_K2CANFD: start 26, 3 bit, little-endian, data-type-policy=OVERRIDE, i-signal-type=PRIMITIVE, init-value=0, base-type=BT_RSt_Anforderung_HMS, compu {0=Cx0_keine_Anforderung (CM_RSt_Anforderung_HMS_Cx0_keine_Anforderung), 1=Cx1_halten (CM_RSt_Anforderung_HMS_Cx1_halten), 2=Cx2_parken (CM_RSt_Anforderung_HMS_Cx2_parken), 3=Cx3_halten_Standby (CM_RSt_Anforderung_HMS_Cx3_halten_Standby), 4=Cx4_anfahren (CM_RSt_Anforderung_HMS_Cx4_anfahren), 5=Cx5_Loesen_ueber_Rampe (CM_RSt_Anforderung_HMS_Cx5_Loesen_ueber_Rampe), 6=Cx6_Parken_mit_P (CM_RSt_Anforderung_HMS_Cx6_Parken_mit_P)}, range raw 0..6  # Anforderung vom RSt (Remote Start) an das HMS (Haltemanagement System)
          signal KST_Zuendungswarnung_XIX_Klemmen_Steuerung_01_XIX_E3V_K2CANFD: start 29, 2 bit, little-endian, data-type-policy=OVERRIDE, i-signal-type=PRIMITIVE, init-value=0, base-type=BT_KST_Zuendungswarnung, compu {0=Cx0_keine_Ausgabe_Zuendungswarnung (CM_KST_Zuendungswarnung_Cx0_keine_Ausgabe_Zuendungswarnung), 1=Cx1_Ausg_Zuendungswarnung_Stillstand (CM_KST_Zuendungswarnung_Cx1_Ausg_Zuendungswarnung_Stillstand), 2=Cx2_Ausg_Zuendungswarnung_Fahrt (CM_KST_Zuendungswarnung_Cx2_Ausg_Zuendungswarnung_Fahrt), 3=Cx3_reserved (CM_KST_Zuendungswarnung_Cx3_reserved)}, range raw 0..3  # Bei aktivem Signal soll je nach gesetztem Status eine Warnung durch das Kombi ausgegeben werden
          signal KST_Fahrer_Info_Text_XIX_Klemmen_Steuerung_01_XIX_E3V_K2CANFD: start 31, 3 bit, little-endian, data-type-policy=OVERRIDE, i-signal-type=PRIMITIVE, init-value=0, base-type=BT_KST_Fahrer_Info_Text, compu {0=Cx0_nicht_Aktiv (CM_KST_Fahrer_Info_Text_Cx0_nicht_Aktiv), 1=Cx1_Fahrerhinweis_1 (CM_KST_Fahrer_Info_Text_Cx1_Fahrerhinweis_1), 2=Cx2_Fahrerhinweis_2 (CM_KST_Fahrer_Info_Text_Cx2_Fahrerhinweis_2)}, range raw 0..2  # Hinweise für den Fahrer für die Fahrzeugaktivierung / -deaktivierung
          signal KST_KL15LockStatus_XIX_Klemmen_Steuerung_01_XIX_E3V_K2CANFD: start 34, 2 bit, little-endian, data-type-policy=OVERRIDE, i-signal-type=PRIMITIVE, init-value=0, base-type=BT_KST_KL15LockStatus, compu {0=Cx0_Idle (CM_KST_KL15LockStatus_Cx0_Idle), 1=Cx1_LockReleased (CM_KST_KL15LockStatus_Cx1_LockReleased), 2=Cx2_LockActive (CM_KST_KL15LockStatus_Cx2_LockActive)}, range raw 0..2, to SAM(timeout 5 s)
          signal ISignalVoid_Klemmen_Steuerung_01_XIX_E3V_K2CANFD_0: start 36, 4 bit, little-endian, system signal SignalVoid_Klemmen_Steuerung_01_0, data-type-policy=OVERRIDE, i-signal-type=PRIMITIVE, base-type=BT_SignalVoid
          signal ISignalVoid_Klemmen_Steuerung_01_XIX_E3V_K2CANFD_1: start 40, 8 bit, little-endian, system signal SignalVoid_Klemmen_Steuerung_01_1, data-type-policy=OVERRIDE, i-signal-type=PRIMITIVE, base-type=BT_SignalVoid
          signal ISignalVoid_Klemmen_Steuerung_01_XIX_E3V_K2CANFD_2: start 48, 8 bit, little-endian, system signal SignalVoid_Klemmen_Steuerung_01_2, data-type-policy=OVERRIDE, i-signal-type=PRIMITIVE, base-type=BT_SignalVoid
          signal ISignalVoid_Klemmen_Steuerung_01_XIX_E3V_K2CANFD_3: start 56, 8 bit, little-endian, system signal SignalVoid_Klemmen_Steuerung_01_3, data-type-policy=OVERRIDE, i-signal-type=PRIMITIVE, base-type=BT_SignalVoid
          mapping SG_Klemmen_Steuerung_01_XIX_E3V_K2CANFD: i-signal-group=SG_Klemmen_Steuerung_01_XIX_E3V_K2CANFD, transfer-property=TRIGGERED-WITHOUT-REPETITION
      frame Klima_12_XIX_E3V_K2CANFD: id 0x668, to SAM, frame-length=8, can-addressing-mode=STANDARD, can-frame-rx-behavior=CAN-FD, can-frame-tx-behavior=CAN-FD
        pdu Klima_12_XIX_E3V_K2CANFD: length=8, minimum-delay=0.05, transmission-mode-true-timing={cyclic-timing={time-offset=0.0, time-period=0.2}, event-controlled-timing={number-of-repetitions=5, repetition-period=0.1}}, unused-bit-pattern=0  # ab MQB IS-4
          signal KL_LRH_Taster_XIX_Klima_12_XIX_E3V_K2CANFD: start 0, 1 bit, little-endian, data-type-policy=OVERRIDE, i-signal-type=PRIMITIVE, init-value=0, base-type=BT_KL_LRH_Taster, compu {0=Cx0_nicht_betaetigt (CM_KL_LRH_Taster_Cx0_nicht_betaetigt), 1=Cx1_betaetigt (CM_KL_LRH_Taster_Cx1_betaetigt)}, range raw 0..1, transfer-property=TRIGGERED-ON-CHANGE, to SAM(timeout 2 s)  # Tasterbetätigung Lenkradheizung
          signal KL_LRH_Stufe_XIX_Klima_12_XIX_E3V_K2CANFD: start 1, 2 bit, little-endian, data-type-policy=OVERRIDE, i-signal-type=PRIMITIVE, init-value=1, base-type=BT_KL_LRH_Stufe, compu {0=Cx0_Stufe_niedrig (CM_KL_LRH_Stufe_Cx0_Stufe_niedrig), 1=Cx1_Stufe_mittel (CM_KL_LRH_Stufe_Cx1_Stufe_mittel), 2=Cx2_Stufe_hoch (CM_KL_LRH_Stufe_Cx2_Stufe_hoch), 3=Cx3_AUS (CM_KL_LRH_Stufe_Cx3_AUS)}, range raw 0..3, transfer-property=TRIGGERED-ON-CHANGE-WITHOUT-REPETITION, to SAM(timeout 2 s)  # Eingestellte Temperaturstufe der Lenkradheizung
          signal HSH_Taster_XIX_Klima_12_XIX_E3V_K2CANFD: start 3, 2 bit, little-endian, data-type-policy=OVERRIDE, i-signal-type=PRIMITIVE, init-value=0, base-type=BT_HSH_Taster, compu {0=Cx0_nicht_betaetigt (CM_HSH_Taster_Cx0_nicht_betaetigt), 1=Cx1_short_push (CM_HSH_Taster_Cx1_short_push), 2=Cx2_long_push (CM_HSH_Taster_Cx2_long_push), 3=Cx3_tbd (CM_HSH_Taster_Cx3_tbd)}, range raw 0..3, transfer-property=TRIGGERED-ON-CHANGE  # An-/Abforderung Heckscheibenheizung über spezielles Tastersignal
          signal FSH_Taster_XIX_Klima_12_XIX_E3V_K2CANFD: start 5, 1 bit, little-endian, data-type-policy=OVERRIDE, i-signal-type=PRIMITIVE, init-value=0, base-type=BT_FSH_Taster, compu {0=Cx0_nicht_betaetigt (CM_FSH_Taster_Cx0_nicht_betaetigt), 1=Cx1_betaetigt (CM_FSH_Taster_Cx1_betaetigt)}, range raw 0..1, transfer-property=TRIGGERED-ON-CHANGE  # Tasterbetätigung Frontscheibenheizung
          signal KL_Zuheizer_Freigabe_XIX_Klima_12_XIX_E3V_K2CANFD: start 6, 1 bit, little-endian, data-type-policy=OVERRIDE, i-signal-type=PRIMITIVE, init-value=0, base-type=BT_KL_Zuheizer_Freigabe, compu {0=Cx0_keine_Freigabe_Zuheizer (CM_KL_Zuheizer_Freigabe_Cx0_keine_Freigabe_Zuheizer), 1=Cx1_Zuheizerfreigabe (CM_KL_Zuheizer_Freigabe_Cx1_Zuheizerfreigabe)}, range raw 0..1, transfer-property=TRIGGERED-ON-CHANGE-WITHOUT-REPETITION  # Freigabe Zuheizer
          signal KL_Beschlagsgefahr_XIX_Klima_12_XIX_E3V_K2CANFD: start 7, 1 bit, little-endian, data-type-policy=OVERRIDE, i-signal-type=PRIMITIVE, init-value=0, base-type=BT_KL_Beschlagsgefahr, compu {0=Cx0_keine_Beschlagsgefahr (CM_KL_Beschlagsgefahr_Cx0_keine_Beschlagsgefahr), 1=Cx1_Beschlagsgefahr (CM_KL_Beschlagsgefahr_Cx1_Beschlagsgefahr)}, range raw 0..1, transfer-property=TRIGGERED-ON-CHANGE-WITHOUT-REPETITION  # Beschlagsgefahr auf der Frontscheibe im Bereich des Spiegelfusses. Dient zur präventiven Ansteuerung der Kamera-Scheibenheizung, um Kamera-Blindheit zu vermeiden PHEV: volle Leistungsfreigabe HV Heizer und HV EKK bei Scheibenbeschlag
          signal KL_SIH_Soll_li_XIX_Klima_12_XIX_E3V_K2CANFD: start 8, 3 bit, little-endian, data-type-policy=OVERRIDE, i-signal-type=PRIMITIVE, init-value=0, base-type=BT_KL_SIH_Soll_li, compu {phys=raw for raw 0..6}, range phys 0..6, raw 0..6, transfer-property=TRIGGERED-ON-CHANGE-WITHOUT-REPETITION  # Einstellung Sitzheizung Fahrer (0...6)
          signal KL_SIH_Soll_re_XIX_Klima_12_XIX_E3V_K2CANFD: start 11, 3 bit, little-endian, data-type-policy=OVERRIDE, i-signal-type=PRIMITIVE, init-value=0, base-type=BT_KL_SIH_Soll_re, compu {phys=raw for raw 0..6}, range phys 0..6, raw 0..6, transfer-property=TRIGGERED-ON-CHANGE-WITHOUT-REPETITION  # Einstellung Sitzheizung Beifahrer (0...6)
          signal KRH_Soll_li_XIX_Klima_12_XIX_E3V_K2CANFD: start 14, 2 bit, little-endian, data-type-policy=OVERRIDE, i-signal-type=PRIMITIVE, init-value=0, base-type=BT_KRH_Soll_li, compu {0=Cx0_aus (CM_KRH_Soll_li_Cx0_aus), 1=Cx1_Stufe_1 (CM_KRH_Soll_li_Cx1_Stufe_1), 2=Cx2_Stufe_2 (CM_KRH_Soll_li_Cx2_Stufe_2), 3=Cx3_Stufe_3 (CM_KRH_Soll_li_Cx3_Stufe_3)}, range raw 0..3, transfer-property=TRIGGERED-ON-CHANGE-WITHOUT-REPETITION  # Ausgabe des Sollwertes für die Kopfraumheizung links.
          signal KL_SIL_Soll_li_XIX_Klima_12_XIX_E3V_K2CANFD: start 16, 3 bit, little-endian, data-type-policy=OVERRIDE, i-signal-type=PRIMITIVE, init-value=0, base-type=BT_KL_SIL_Soll_li, compu {phys=raw for raw 0..6}, range phys 0..6, raw 0..6, transfer-property=TRIGGERED-ON-CHANGE-WITHOUT-REPETITION, to SAM(timeout 2 s)  # Einstellung Sitzlüftung Fahrer (0...6)
          signal KL_SIL_Soll_re_XIX_Klima_12_XIX_E3V_K2CANFD: start 19, 3 bit, little-endian, data-type-policy=OVERRIDE, i-signal-type=PRIMITIVE, init-value=0, base-type=BT_KL_SIL_Soll_re, compu {phys=raw for raw 0..6}, range phys 0..6, raw 0..6, transfer-property=TRIGGERED-ON-CHANGE-WITHOUT-REPETITION, to SAM(timeout 2 s)  # Einstellung Sitzlüftung Beifahrer (0...6)
          signal KRH_Soll_re_XIX_Klima_12_XIX_E3V_K2CANFD: start 22, 2 bit, little-endian, data-type-policy=OVERRIDE, i-signal-type=PRIMITIVE, init-value=0, base-type=BT_KRH_Soll_re, compu {0=Cx0_aus (CM_KRH_Soll_re_Cx0_aus), 1=Cx1_Stufe_1 (CM_KRH_Soll_re_Cx1_Stufe_1), 2=Cx2_Stufe_2 (CM_KRH_Soll_re_Cx2_Stufe_2), 3=Cx3_Stufe_3 (CM_KRH_Soll_re_Cx3_Stufe_3)}, range raw 0..3, transfer-property=TRIGGERED-ON-CHANGE-WITHOUT-REPETITION  # Ausgabe des Sollwertes für die Kopfraumheizung rechts.
          signal KL_Geblspng_Soll_XIX_Klima_12_XIX_E3V_K2CANFD: start 24, 8 bit, little-endian, data-type-policy=OVERRIDE, i-signal-type=PRIMITIVE, init-value=0, base-type=BT_KL_Geblspng_Soll, invalid-value=Invalid_KL_Geblspng_Soll_XIX_Klima_12_XIX_E3V_K2CANFD:255, compu {0=Cx0_0V_Motorspannung (CM_KL_Geblspng_Soll_Cx0_0V_Motorspannung), phys=raw*0.05+1.45 for raw 1..251, 252=Cxfc_0V_sofort_Abschalten (CM_KL_Geblspng_Soll_Cxfc_0V_sofort_Abschalten), 253=Cxfd_0V_senken_mit_Rampe (CM_KL_Geblspng_Soll_Cxfd_0V_senken_mit_Rampe), 254=Cxfe_reserviert (CM_KL_Geblspng_Soll_Cxfe_reserviert), 255=Cxff_Fehler (CM_KL_Geblspng_Soll_Cxff_Fehler); unit Unit_Volt}, range phys 1.5..14 Unit_Volt, raw 0..255, unit=Unit_Volt, transfer-property=PENDING  # Ausgabe des Sollwertes für die Spannung des Klimagebläsemotores vorne.
          signal KL_Geblspng_Fond_Soll_XIX_Klima_12_XIX_E3V_K2CANFD: start 32, 8 bit, little-endian, data-type-policy=OVERRIDE, i-signal-type=PRIMITIVE, init-value=0, base-type=BT_KL_Geblspng_Fond_Soll, invalid-value=Invalid_KL_Geblspng_Fond_Soll_XIX_Klima_12_XIX_E3V_K2CANFD:255, compu {0=Cx0_0V_Motorspannung (CM_KL_Geblspng_Fond_Soll_Cx0_0V_Motorspannung), phys=raw*0.05+1.45 for raw 1..251, 252=Cxfc_0V_sofort_Abschalten (CM_KL_Geblspng_Fond_Soll_Cxfc_0V_sofort_Abschalten), 253=Cxfd_0V_senken_mit_Rampe (CM_KL_Geblspng_Fond_Soll_Cxfd_0V_senken_mit_Rampe), 254=Cxfe_reserviert (CM_KL_Geblspng_Fond_Soll_Cxfe_reserviert), 255=Cxff_Fehler (CM_KL_Geblspng_Fond_Soll_Cxff_Fehler); unit Unit_Volt}, range phys 1.5..14 Unit_Volt, raw 0..255, unit=Unit_Volt, transfer-property=PENDING  # Ausgabe des Sollwertes für die Spannung des Klimagebläsemotores hinten.
          signal KL_I_Geblaese_XIX_Klima_12_XIX_E3V_K2CANFD: start 40, 8 bit, little-endian, data-type-policy=OVERRIDE, i-signal-type=PRIMITIVE, init-value=0, base-type=BT_KL_I_Geblaese, invalid-value=Invalid_KL_I_Geblaese_XIX_Klima_12_XIX_E3V_K2CANFD:255, compu {phys=raw*0.25 for raw 0..254, 255=Cxff_Fehler (CM_KL_I_Geblaese_Cxff_Fehler); unit Unit_Amper}, range phys 0..63.5 Unit_Amper, raw 0..255, unit=Unit_Amper, transfer-property=PENDING  # Stromaufnahme Gebläse
          signal KL_Kompressorstrom_soll_XIX_Klima_12_XIX_E3V_K2CANFD: start 48, 10 bit, little-endian, data-type-policy=OVERRIDE, i-signal-type=PRIMITIVE, init-value=1022, base-type=BT_KL_Kompressorstrom_soll, invalid-value=Invalid_KL_Kompressorstrom_soll_XIX_Klima_12_XIX_E3V_K2CANFD:1023, compu {phys=raw for raw 0..1021, 1022=Cx3fe_Init (CM_KL_Kompressorstrom_soll_Cx3fe_Init), 1023=Cx3ff_Fehler (CM_KL_Kompressorstrom_soll_Cx3ff_Fehler)}, range phys 0..1021, raw 0..1023, transfer-property=PENDING  # Sollvorgabe Klima-Kompressorstrom
          signal KL_Umluftklappe_Status_XIX_Klima_12_XIX_E3V_K2CANFD: start 58, 4 bit, little-endian, data-type-policy=OVERRIDE, i-signal-type=PRIMITIVE, init-value=14, base-type=BT_KL_Umluftklappe_Status, invalid-value=Invalid_KL_Umluftklappe_Status_XIX_Klima_12_XIX_E3V_K2CANFD:15, compu {0=Cx0_Frischluft (CM_KL_Umluftklappe_Status_Cx0_Frischluft), 1=Cx1_Teilumluft_10 (CM_KL_Umluftklappe_Status_Cx1_Teilumluft_10), 2=Cx2_Teilumluft_20 (CM_KL_Umluftklappe_Status_Cx2_Teilumluft_20), 3=Cx3_Teilumluft_30 (CM_KL_Umluftklappe_Status_Cx3_Teilumluft_30), 4=Cx4_Teilumluft_40 (CM_KL_Umluftklappe_Status_Cx4_Teilumluft_40), 5=Cx5_Teilumluft_50 (CM_KL_Umluftklappe_Status_Cx5_Teilumluft_50), 6=Cx6_Teilumluft_60 (CM_KL_Umluftklappe_Status_Cx6_Teilumluft_60), 7=Cx7_Teilumluft_70 (CM_KL_Umluftklappe_Status_Cx7_Teilumluft_70), 8=Cx8_Teilumluft_80 (CM_KL_Umluftklappe_Status_Cx8_Teilumluft_80), 9=Cx9_Teilumluft_90 (CM_KL_Umluftklappe_Status_Cx9_Teilumluft_90), 10=Cxa_Umluft (CM_KL_Umluftklappe_Status_Cxa_Umluft), 14=Cxe_Init (CM_KL_Umluftklappe_Status_Cxe_Init), 15=Cxf_Fehler (CM_KL_Umluftklappe_Status_Cxf_Fehler)}, range raw 0..15, transfer-property=PENDING  # Status Umluftklappe
          signal KL_PTC_Verbauinfo_XIX_Klima_12_XIX_E3V_K2CANFD: start 62, 2 bit, little-endian, data-type-policy=OVERRIDE, i-signal-type=PRIMITIVE, init-value=0, base-type=BT_KL_PTC_Verbauinfo, compu {0=Cx0_kein_PTC (CM_KL_PTC_Verbauinfo_Cx0_kein_PTC), 1=Cx1_600W_geschaltet (CM_KL_PTC_Verbauinfo_Cx1_600W_geschaltet), 2=Cx2_1000W_geschaltet (CM_KL_PTC_Verbauinfo_Cx2_1000W_geschaltet), 3=Cx3_1400W_LIN (CM_KL_PTC_Verbauinfo_Cx3_1400W_LIN)}, range raw 0..3, transfer-property=PENDING  # Im Klima- bzw. Heizungsbedienteil wird der Verbau eines PTCs und dessen elektr. Leistungsklasse codiert
      frame Klima_16_XIX_E3V_K2CANFD: id 0x16A95493, to SAM, frame-length=8, can-addressing-mode=EXTENDED, can-frame-rx-behavior=CAN-FD, can-frame-tx-behavior=CAN-FD
        pdu Klima_16_XIX_E3V_K2CANFD: length=8, minimum-delay=0.2, transmission-mode-true-timing={cyclic-timing={time-offset=0.0, time-period=2.0}, event-controlled-timing={number-of-repetitions=0, repetition-period=0.0}}, unused-bit-pattern=0
          signal KL_Voko_Status_XIX_Klima_16_XIX_E3V_K2CANFD: start 0, 4 bit, little-endian, data-type-policy=OVERRIDE, i-signal-type=PRIMITIVE, init-value=14, base-type=BT_KL_Voko_Status, invalid-value=Invalid_KL_Voko_Status_XIX_Klima_16_XIX_E3V_K2CANFD:15, compu {0=Cx0_aus (CM_KL_Voko_Status_Cx0_aus), 1=Cx1_ein (CM_KL_Voko_Status_Cx1_ein), 14=Cxe_Init (CM_KL_Voko_Status_Cxe_Init), 15=Cxf_Fehler (CM_KL_Voko_Status_Cxf_Fehler)}, range raw 0..15, transfer-property=TRIGGERED-ON-CHANGE-WITHOUT-REPETITION  # Status der Vorkonditionierung. 0 = aus 1 = ein 14 = Init 15 = Fehler
          signal KL_LRH_PWM_XIX_Klima_16_XIX_E3V_K2CANFD: start 4, 7 bit, little-endian, data-type-policy=OVERRIDE, i-signal-type=PRIMITIVE, init-value=0, base-type=BT_KL_LRH_PWM, compu {phys=raw for raw 0..100; unit Unit_PerCent}, range phys 0..100 Unit_PerCent, raw 0..100, unit=Unit_PerCent, transfer-property=TRIGGERED-ON-CHANGE-WITHOUT-REPETITION  # LRH PWM Signal zur Ansteuerung der Treiberstufe im SMLS (0% - 100%)
          signal KL_LRH_Soll_XIX_Klima_16_XIX_E3V_K2CANFD: start 11, 1 bit, little-endian, data-type-policy=OVERRIDE, i-signal-type=PRIMITIVE, init-value=0, base-type=BT_KL_LRH_Soll, compu {0=Cx0_nicht_angefordert (CM_KL_LRH_Soll_Cx0_nicht_angefordert), 1=Cx1_angefordert (CM_KL_LRH_Soll_Cx1_angefordert)}, range raw 0..1, transfer-property=TRIGGERED-ON-CHANGE-WITHOUT-REPETITION  # Sollstatus der Lenkradheizung
          signal KL_AL_VR_Anf_XIX_Klima_16_XIX_E3V_K2CANFD: start 12, 2 bit, little-endian, data-type-policy=OVERRIDE, i-signal-type=PRIMITIVE, init-value=0, base-type=BT_KL_AL_VR_Anf, compu {0=Cx0_neutral (CM_KL_AL_VR_Anf_Cx0_neutral), 1=Cx1_waermer (CM_KL_AL_VR_Anf_Cx1_waermer), 2=Cx2_kaelter (CM_KL_AL_VR_Anf_Cx2_kaelter)}, range raw 0..2, transfer-property=TRIGGERED-ON-CHANGE-WITHOUT-REPETITION, to SAM(timeout 5 s)  # Anforderung an das funktionale Ambientelicht eine Solltemperaturveränderung vorn rechts darzustellen.
          signal KL_AL_VL_Anf_XIX_Klima_16_XIX_E3V_K2CANFD: start 14, 2 bit, little-endian, data-type-policy=OVERRIDE, i-signal-type=PRIMITIVE, init-value=0, base-type=BT_KL_AL_VL_Anf, compu {0=Cx0_neutral (CM_KL_AL_VL_Anf_Cx0_neutral), 1=Cx1_waermer (CM_KL_AL_VL_Anf_Cx1_waermer), 2=Cx2_kaelter (CM_KL_AL_VL_Anf_Cx2_kaelter)}, range raw 0..2, transfer-property=TRIGGERED-ON-CHANGE-WITHOUT-REPETITION, to SAM(timeout 5 s)  # Anforderung an das funktionale Ambientelicht eine Solltemperaturveränderung vorn links darzustellen.
          signal KL_AL_HR_Anf_XIX_Klima_16_XIX_E3V_K2CANFD: start 16, 2 bit, little-endian, data-type-policy=OVERRIDE, i-signal-type=PRIMITIVE, init-value=0, base-type=BT_KL_AL_HR_Anf, compu {0=Cx0_neutral (CM_KL_AL_HR_Anf_Cx0_neutral), 1=Cx1_waermer (CM_KL_AL_HR_Anf_Cx1_waermer), 2=Cx2_kaelter (CM_KL_AL_HR_Anf_Cx2_kaelter)}, range raw 0..2, transfer-property=TRIGGERED-ON-CHANGE-WITHOUT-REPETITION, to SAM(timeout 5 s)  # Anforderung an das funktionale Ambientelicht eine Solltemperaturveränderung hinten rechts darzustellen.
          signal KL_AL_HL_Anf_XIX_Klima_16_XIX_E3V_K2CANFD: start 18, 2 bit, little-endian, data-type-policy=OVERRIDE, i-signal-type=PRIMITIVE, init-value=0, base-type=BT_KL_AL_HL_Anf, compu {0=Cx0_neutral (CM_KL_AL_HL_Anf_Cx0_neutral), 1=Cx1_waermer (CM_KL_AL_HL_Anf_Cx1_waermer), 2=Cx2_kaelter (CM_KL_AL_HL_Anf_Cx2_kaelter)}, range raw 0..2, transfer-property=TRIGGERED-ON-CHANGE-WITHOUT-REPETITION, to SAM(timeout 5 s)  # Anforderung an das funktionale Ambientelicht eine Solltemperaturveränderung hinten links darzustellen.
          signal KL_HSH_Soll_XIX_Klima_16_XIX_E3V_K2CANFD: start 20, 1 bit, little-endian, data-type-policy=OVERRIDE, i-signal-type=PRIMITIVE, init-value=0, base-type=BT_KL_HSH_Soll, compu {0=Cx0_nicht_angefordert (CM_KL_HSH_Soll_Cx0_nicht_angefordert), 1=Cx1_angefordert (CM_KL_HSH_Soll_Cx1_angefordert)}, range raw 0..1, transfer-property=TRIGGERED-ON-CHANGE-WITHOUT-REPETITION  # Sollstatus Heckscheibenheizung
          signal KL_FSH_Soll_XIX_Klima_16_XIX_E3V_K2CANFD: start 21, 1 bit, little-endian, data-type-policy=OVERRIDE, i-signal-type=PRIMITIVE, init-value=0, base-type=BT_KL_FSH_Soll, compu {0=Cx0_nicht_angefordert (CM_KL_FSH_Soll_Cx0_nicht_angefordert), 1=Cx1_angefordert (CM_KL_FSH_Soll_Cx1_angefordert)}, range raw 0..1, transfer-property=TRIGGERED-ON-CHANGE-WITHOUT-REPETITION  # Sollstatus der Frontscheibenheizung
          signal KL_ZR_Anforderung_XIX_Klima_16_XIX_E3V_K2CANFD: start 22, 2 bit, little-endian, data-type-policy=OVERRIDE, i-signal-type=PRIMITIVE, init-value=0, base-type=BT_KL_ZR_Anforderung, compu {0=Cx0_init (CM_KL_ZR_Anforderung_Cx0_init), 1=Cx1_inaktiv (CM_KL_ZR_Anforderung_Cx1_inaktiv), 2=Cx2_aktiv (CM_KL_ZR_Anforderung_Cx2_aktiv), 3=Cx3_reserviert (CM_KL_ZR_Anforderung_Cx3_reserviert)}, range raw 0..3, transfer-property=TRIGGERED-ON-CHANGE-WITHOUT-REPETITION  # Anforderung an MIB die Displays zu aktivieren
          signal KL_VoKo_LED_XIX_Klima_16_XIX_E3V_K2CANFD: start 24, 1 bit, little-endian, data-type-policy=OVERRIDE, i-signal-type=PRIMITIVE, init-value=0, base-type=BT_KL_VoKo_LED, compu {0=Cx0_Aus (CM_KL_VoKo_LED_Cx0_Aus), 1=Cx1_Ein (CM_KL_VoKo_LED_Cx1_Ein)}, range raw 0..1, transfer-property=TRIGGERED-ON-CHANGE-WITHOUT-REPETITION  # Signalisierung Vorkonditionierung
          signal KL_Defrost_LED_XIX_Klima_16_XIX_E3V_K2CANFD: start 25, 1 bit, little-endian, data-type-policy=OVERRIDE, i-signal-type=PRIMITIVE, init-value=0, base-type=BT_KL_Defrost_LED, compu {0=Cx0_Aus (CM_KL_Defrost_LED_Cx0_Aus), 1=Cx1_Ein (CM_KL_Defrost_LED_Cx1_Ein)}, range raw 0..1, transfer-property=TRIGGERED-ON-CHANGE-WITHOUT-REPETITION, to SAM(timeout 5 s)  # Beleuchtung LED Defrost
          signal KL_HSH_LED_XIX_Klima_16_XIX_E3V_K2CANFD: start 26, 1 bit, little-endian, data-type-policy=OVERRIDE, i-signal-type=PRIMITIVE, init-value=0, base-type=BT_KL_HSH_LED, compu {0=Cx0_Aus (CM_KL_HSH_LED_Cx0_Aus), 1=Cx1_Ein (CM_KL_HSH_LED_Cx1_Ein)}, range raw 0..1, transfer-property=TRIGGERED-ON-CHANGE-WITHOUT-REPETITION, to SAM(timeout 5 s)  # Beleuchtung LED Heckscheibenheizung
          signal HSH_Relais_Anf_XIX_Klima_16_XIX_E3V_K2CANFD: start 27, 1 bit, little-endian, data-type-policy=OVERRIDE, i-signal-type=PRIMITIVE, init-value=0, base-type=BT_HSH_Relais_Anf, compu {0=Cx0_nicht_angefordert (CM_HSH_Relais_Anf_Cx0_nicht_angefordert), 1=Cx1_angefordert (CM_HSH_Relais_Anf_Cx1_angefordert)}, range raw 0..1, transfer-property=TRIGGERED-ON-CHANGE-WITHOUT-REPETITION, to SAM(timeout 5 s)  # Relaisanforderung Heckscheibenheizung
          signal FSH_Status_XIX_Klima_16_XIX_E3V_K2CANFD: start 28, 2 bit, little-endian, data-type-policy=OVERRIDE, i-signal-type=PRIMITIVE, init-value=0, base-type=BT_FSH_Status, invalid-value=Invalid_FSH_Status_XIX_Klima_16_XIX_E3V_K2CANFD:3, compu {0=Cx0_aus (CM_FSH_Status_Cx0_aus), 1=Cx1_ein (CM_FSH_Status_Cx1_ein), 2=Cx2_tbd (CM_FSH_Status_Cx2_tbd), 3=Cx3_Fehler (CM_FSH_Status_Cx3_Fehler)}, range raw 0..3, transfer-property=PENDING  # Fehlerstatus der Frontscheibenheizung
          signal SIH_Stufe_LED_li_XIX_Klima_16_XIX_E3V_K2CANFD: start 30, 3 bit, little-endian, data-type-policy=OVERRIDE, i-signal-type=PRIMITIVE, init-value=0, base-type=BT_SIH_Stufe_LED_li, compu {0=Cx0_Aus (CM_SIH_Stufe_LED_li_Cx0_Aus), 2=Cx2_Stufe_2 (CM_SIH_Stufe_LED_li_Cx2_Stufe_2), 4=Cx4_Stufe_4 (CM_SIH_Stufe_LED_li_Cx4_Stufe_4), 6=Cx6_Stufe_6 (CM_SIH_Stufe_LED_li_Cx6_Stufe_6)}, range raw 0..6, transfer-property=TRIGGERED-ON-CHANGE-WITHOUT-REPETITION  # Statusmeldung Sitzheizung links
          signal SIH_Stufe_LED_re_XIX_Klima_16_XIX_E3V_K2CANFD: start 33, 3 bit, little-endian, data-type-policy=OVERRIDE, i-signal-type=PRIMITIVE, init-value=0, base-type=BT_SIH_Stufe_LED_re, compu {0=Cx0_Aus (CM_SIH_Stufe_LED_re_Cx0_Aus), 2=Cx2_Stufe_2 (CM_SIH_Stufe_LED_re_Cx2_Stufe_2), 4=Cx4_Stufe_4 (CM_SIH_Stufe_LED_re_Cx4_Stufe_4), 6=Cx6_Stufe_6 (CM_SIH_Stufe_LED_re_Cx6_Stufe_6)}, range raw 0..6, transfer-property=TRIGGERED-ON-CHANGE-WITHOUT-REPETITION  # Statusmeldung Sitzheizung rechts
          signal KL_FSH_LED_XIX_Klima_16_XIX_E3V_K2CANFD: start 36, 1 bit, little-endian, data-type-policy=OVERRIDE, i-signal-type=PRIMITIVE, init-value=0, base-type=BT_KL_FSH_LED, compu {0=Cx0_Aus (CM_KL_FSH_LED_Cx0_Aus), 1=Cx1_Ein (CM_KL_FSH_LED_Cx1_Ein)}, range raw 0..1, transfer-property=TRIGGERED-ON-CHANGE-WITHOUT-REPETITION, to SAM(timeout 5 s)  # Beleuchtung LED Frontscheibenheizung
          signal KL_HUP_aktiv_XIX_Klima_16_XIX_E3V_K2CANFD: start 37, 1 bit, little-endian, data-type-policy=OVERRIDE, i-signal-type=PRIMITIVE, init-value=0, base-type=BT_KL_HUP_aktiv, compu {0=Cx0_Aus (CM_KL_HUP_aktiv_Cx0_Aus), 1=Cx1_Ein (CM_KL_HUP_aktiv_Cx1_Ein)}, range raw 0..1, transfer-property=TRIGGERED-ON-CHANGE-WITHOUT-REPETITION  # Signal des Klimabedienteils ob HUP aktiv ist. 0 = HUP aus 1 = HUP ein
          signal KL_LSH_DBetr_Ein_XIX_Klima_16_XIX_E3V_K2CANFD: start 38, 1 bit, little-endian, data-type-policy=OVERRIDE, i-signal-type=PRIMITIVE, init-value=0, base-type=BT_KL_LSH_DBetr_Ein, compu {0=Cx0_Dauerbetrieb_nicht_gefordert (CM_KL_LSH_DBetr_Ein_Cx0_Dauerbetrieb_nicht_gefordert), 1=Cx1_Dauerbetrieb_gefordert (CM_KL_LSH_DBetr_Ein_Cx1_Dauerbetrieb_gefordert)}, range raw 0..1, transfer-property=TRIGGERED-ON-CHANGE-WITHOUT-REPETITION  # Dauerbetrieb der Luftstandheizung Ein
          signal KL_LSH_DBetr_Bestaet_XIX_Klima_16_XIX_E3V_K2CANFD: start 39, 1 bit, little-endian, data-type-policy=OVERRIDE, i-signal-type=PRIMITIVE, init-value=0, base-type=BT_KL_LSH_DBetr_Bestaet, compu {0=Cx0_kein_Dauerbetrieb (CM_KL_LSH_DBetr_Bestaet_Cx0_kein_Dauerbetrieb), 1=Cx1_Dauerbetrieb_bestaetigt (CM_KL_LSH_DBetr_Bestaet_Cx1_Dauerbetrieb_bestaetigt)}, range raw 0..1, transfer-property=TRIGGERED-ON-CHANGE-WITHOUT-REPETITION  # Bestätigung des Klimabedienteils an die LSH das Dauerbetrieb tatsächlich angefordert ist.
          signal KL_Klappe_Status_XIX_Klima_16_XIX_E3V_K2CANFD: start 40, 3 bit, little-endian, data-type-policy=OVERRIDE, i-signal-type=PRIMITIVE, init-value=0, base-type=BT_KL_Klappe_Status, compu {0=Cx0_Init (CM_KL_Klappe_Status_Cx0_Init), 1=Cx1_Front (CM_KL_Klappe_Status_Cx1_Front), 2=Cx2_Heck (CM_KL_Klappe_Status_Cx2_Heck), 3=Cx3_Front_u_Heck (CM_KL_Klappe_Status_Cx3_Front_u_Heck), 4=Cx4_misch_Front_u_Heck (CM_KL_Klappe_Status_Cx4_misch_Front_u_Heck)}, range raw 0..4, transfer-property=TRIGGERED-ON-CHANGE-WITHOUT-REPETITION  # Status Luftklappe
          signal KL_LSH_Ansteuerung_XIX_Klima_16_XIX_E3V_K2CANFD: start 43, 2 bit, little-endian, data-type-policy=OVERRIDE, i-signal-type=PRIMITIVE, init-value=0, base-type=BT_KL_LSH_Ansteuerung, compu {0=Cx0_Aus (CM_KL_LSH_Ansteuerung_Cx0_Aus), 1=Cx1_Ein (CM_KL_LSH_Ansteuerung_Cx1_Ein), 2=Cx2_Kombi_Betrieb (CM_KL_LSH_Ansteuerung_Cx2_Kombi_Betrieb), 3=Cx3_Heizleistung_reduziert (CM_KL_LSH_Ansteuerung_Cx3_Heizleistung_reduziert)}, range raw 0..3, transfer-property=TRIGGERED-ON-CHANGE-WITHOUT-REPETITION  # Ansteuerung LSH
          signal KL_Heizstufe_LSH_XIX_Klima_16_XIX_E3V_K2CANFD: start 45, 4 bit, little-endian, data-type-policy=OVERRIDE, i-signal-type=PRIMITIVE, init-value=0, base-type=BT_KL_Heizstufe_LSH, invalid-value=Invalid_KL_Heizstufe_LSH_XIX_Klima_16_XIX_E3V_K2CANFD:15, compu {0=Cx0_Init (CM_KL_Heizstufe_LSH_Cx0_Init), 1=Cx1_Stufe_1 (CM_KL_Heizstufe_LSH_Cx1_Stufe_1), 2=Cx2_Stufe_2 (CM_KL_Heizstufe_LSH_Cx2_Stufe_2), 3=Cx3_Stufe_3 (CM_KL_Heizstufe_LSH_Cx3_Stufe_3), 4=Cx4_Stufe_4 (CM_KL_Heizstufe_LSH_Cx4_Stufe_4), 5=Cx5_Stufe_5 (CM_KL_Heizstufe_LSH_Cx5_Stufe_5), 6=Cx6_Stufe_6 (CM_KL_Heizstufe_LSH_Cx6_Stufe_6), 7=Cx7_Stufe_7 (CM_KL_Heizstufe_LSH_Cx7_Stufe_7), 8=Cx8_Stufe_8 (CM_KL_Heizstufe_LSH_Cx8_Stufe_8), 9=Cx9_Stufe_9 (CM_KL_Heizstufe_LSH_Cx9_Stufe_9), 10=Cxa_Stufe_10 (CM_KL_Heizstufe_LSH_Cxa_Stufe_10), 15=Cxf_Fehler (CM_KL_Heizstufe_LSH_Cxf_Fehler)}, range raw 0..15, transfer-property=TRIGGERED-ON-CHANGE-WITHOUT-REPETITION  # Vom Klimabedienteil gesendete Heizstufe der Luftstandheizung
          signal KL_LSH_Betriebsdauer_XIX_Klima_16_XIX_E3V_K2CANFD: start 49, 7 bit, little-endian, data-type-policy=OVERRIDE, i-signal-type=PRIMITIVE, init-value=0, base-type=BT_KL_LSH_Betriebsdauer, compu {phys=raw for raw 0..120, 127=Cx7f_Dauerbetrieb (CM_KL_LSH_Betriebsdauer_Cx7f_Dauerbetrieb); unit Unit_Minut}, range phys 0..120 Unit_Minut, raw 0..127, unit=Unit_Minut, transfer-property=TRIGGERED-ON-CHANGE-WITHOUT-REPETITION  # Betriebsdauer LSH
          signal KL_Temp_ZH_Soll_XIX_Klima_16_XIX_E3V_K2CANFD: start 56, 8 bit, little-endian, data-type-policy=OVERRIDE, i-signal-type=PRIMITIVE, init-value=0, base-type=BT_KL_Temp_ZH_Soll, invalid-value=Invalid_KL_Temp_ZH_Soll_XIX_Klima_16_XIX_E3V_K2CANFD:255, compu {0=Cx0_Funk_nicht_verbaut_nicht_aktiv (CM_KL_Temp_ZH_Soll_Cx0_Funk_nicht_verbaut_nicht_aktiv), phys=raw*0.5 for raw 1..254, 255=Cxff_Fehler (CM_KL_Temp_ZH_Soll_Cxff_Fehler); unit Unit_DegreCelsi}, range phys 0.5..127 Unit_DegreCelsi, raw 0..255, unit=Unit_DegreCelsi, transfer-property=TRIGGERED-ON-CHANGE-WITHOUT-REPETITION  # Übertragung der Temperaturvorgabe der Klimaanlage an die Wasserzusatzheizung
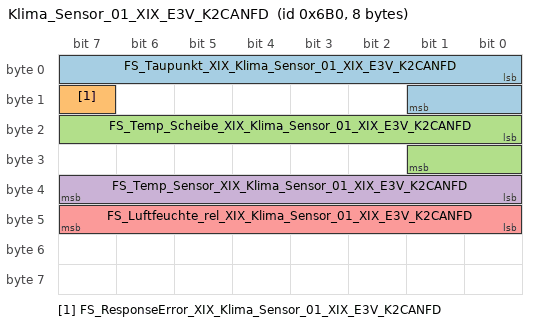
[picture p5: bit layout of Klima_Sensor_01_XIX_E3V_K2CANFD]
      frame Klima_Sensor_01_XIX_E3V_K2CANFD: id 0x6B0, from SAM, frame-length=8, can-addressing-mode=STANDARD, can-frame-rx-behavior=CAN-FD, can-frame-tx-behavior=CAN-FD
        pdu Klima_Sensor_01_XIX_E3V_K2CANFD: length=8, transmission-mode-true-timing=cyclic-timing={time-offset=0.0, time-period=0.5}, unused-bit-pattern=0  # 1:1 LIN-CAN Botschaft, Originalsender ist Regen-/Licht-/Feuchtesensor auf dem BCM-LIN1
          signal FS_Taupunkt_XIX_Klima_Sensor_01_XIX_E3V_K2CANFD: start 0, 10 bit, little-endian, data-type-policy=OVERRIDE, i-signal-type=PRIMITIVE, init-value=0, base-type=BT_FS_Taupunkt, invalid-value=Invalid_FS_Taupunkt_XIX_Klima_Sensor_01_XIX_E3V_K2CANFD:1023, compu {0=Cx0_nicht_verfuegbar (CM_FS_Taupunkt_Cx0_nicht_verfuegbar) (nicht verfuegbar), phys=raw*0.1-39.6 for raw 1..1000, 1023=Cx3ff_Fehler (CM_FS_Taupunkt_Cx3ff_Fehler); unit Unit_DegreCelsi}, range phys -39.5..60.4 Unit_DegreCelsi, raw 0..1023, unit=Unit_DegreCelsi, transfer-property=PENDING  # berechneter Taupunkt
          signal FS_ResponseError_XIX_Klima_Sensor_01_XIX_E3V_K2CANFD: start 15, 1 bit, little-endian, data-type-policy=OVERRIDE, i-signal-type=PRIMITIVE, init-value=0, base-type=BT_FS_ResponseError, invalid-value=Invalid_FS_ResponseError_XIX_Klima_Sensor_01_XIX_E3V_K2CANFD:1, compu {0=Cx0_normal (CM_FS_ResponseError_Cx0_normal), 1=Cx1_Fehler (CM_FS_ResponseError_Cx1_Fehler)}, range raw 0..1, transfer-property=PENDING  # siehe LIN2.0-Specification (Darf nicht über ein Fehlergueltigkeitsbit abgesichtert werden!)
          signal FS_Temp_Scheibe_XIX_Klima_Sensor_01_XIX_E3V_K2CANFD: start 16, 10 bit, little-endian, data-type-policy=OVERRIDE, i-signal-type=PRIMITIVE, init-value=0, base-type=BT_FS_Temp_Scheibe, invalid-value=Invalid_FS_Temp_Scheibe_XIX_Klima_Sensor_01_XIX_E3V_K2CANFD:1023, compu {0=Cx0_nicht_verfuegbar (CM_FS_Temp_Scheibe_Cx0_nicht_verfuegbar) (nicht verfuegbar), phys=raw*0.1-39.6 for raw 1..1000, 1023=Cx3ff_Fehler (CM_FS_Temp_Scheibe_Cx3ff_Fehler); unit Unit_DegreCelsi}, range phys -39.5..60.4 Unit_DegreCelsi, raw 0..1023, unit=Unit_DegreCelsi, transfer-property=PENDING  # gemessene Frontscheibentemperatur
          signal FS_Temp_Sensor_XIX_Klima_Sensor_01_XIX_E3V_K2CANFD: start 32, 8 bit, little-endian, data-type-policy=OVERRIDE, i-signal-type=PRIMITIVE, init-value=0, base-type=BT_FS_Temp_Sensor, invalid-value=Invalid_FS_Temp_Sensor_XIX_Klima_Sensor_01_XIX_E3V_K2CANFD:255, compu {0=Cx0_nicht_verfuegbar (CM_FS_Temp_Sensor_Cx0_nicht_verfuegbar) (nicht verfuegbar), phys=raw*0.5-40 for raw 1..254, 255=Cxff_Fehler (CM_FS_Temp_Sensor_Cxff_Fehler); unit Unit_DegreCelsi}, range phys -39.5..87 Unit_DegreCelsi, raw 0..255, unit=Unit_DegreCelsi, transfer-property=PENDING  # gemessene Sensortemperatur
          signal FS_Luftfeuchte_rel_XIX_Klima_Sensor_01_XIX_E3V_K2CANFD: start 40, 8 bit, little-endian, data-type-policy=OVERRIDE, i-signal-type=PRIMITIVE, init-value=0, base-type=BT_FS_Luftfeuchte_rel, invalid-value=Invalid_FS_Luftfeuchte_rel_XIX_Klima_Sensor_01_XIX_E3V_K2CANFD:255, compu {0=Cx0_nicht_verfuegbar (CM_FS_Luftfeuchte_rel_Cx0_nicht_verfuegbar) (nicht verfuegbar), phys=raw*0.5-0.5 for raw 1..201, 255=Cxff_Fehler (CM_FS_Luftfeuchte_rel_Cxff_Fehler); unit Unit_PerCent}, range phys 0..100 Unit_PerCent, raw 0..255, unit=Unit_PerCent, transfer-property=PENDING  # gemessene relative Luftfeuchte
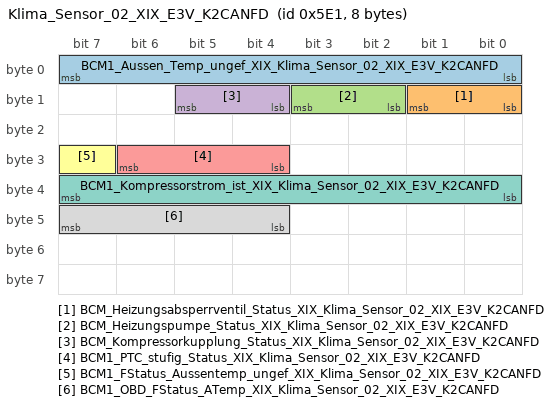
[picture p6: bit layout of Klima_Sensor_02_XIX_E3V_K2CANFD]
      frame Klima_Sensor_02_XIX_E3V_K2CANFD: id 0x5E1, from SAM, frame-length=8, can-addressing-mode=STANDARD, can-frame-rx-behavior=CAN-FD, can-frame-tx-behavior=CAN-FD
        pdu Klima_Sensor_02_XIX_E3V_K2CANFD: length=8, transmission-mode-true-timing=cyclic-timing={time-offset=0.0, time-period=0.2}, unused-bit-pattern=0  # ab MQB 7.3
          signal BCM1_Aussen_Temp_ungef_XIX_Klima_Sensor_02_XIX_E3V_K2CANFD: start 0, 8 bit, little-endian, data-type-policy=OVERRIDE, i-signal-type=PRIMITIVE, init-value=254, base-type=BT_BCM1_Aussen_Temp_ungef, invalid-value=Invalid_BCM1_Aussen_Temp_ungef_XIX_Klima_Sensor_02_XIX_E3V_K2CANFD:255, compu {phys=raw*0.5-50 for raw 0..252, 253=Cxfd_nicht_verbaut (CM_BCM1_Aussen_Temp_ungef_Cxfd_nicht_verbaut), 254=Cxfe_Initwert (CM_BCM1_Aussen_Temp_ungef_Cxfe_Initwert), 255=Cxff_Fehler (CM_BCM1_Aussen_Temp_ungef_Cxff_Fehler); unit Unit_DegreCelsi}, range phys -50..76 Unit_DegreCelsi, raw 0..255, unit=Unit_DegreCelsi, transfer-property=PENDING  # ungefilterter Wert des Aussentemperatursensors
          signal BCM_Heizungsabsperrventil_Status_XIX_Klima_Sensor_02_XIX_E3V_K2CANFD: start 8, 2 bit, little-endian, data-type-policy=OVERRIDE, i-signal-type=PRIMITIVE, init-value=2, base-type=BT_BCM_Heizungsabsperrventil_Status, invalid-value=Invalid_BCM_Heizungsabsperrventil_Status_XIX_Klima_Sensor_02_XIX_E3V_K2CANFD:3, compu {0=Cx0_HAV_offen (CM_BCM_Heizungsabsperrventil_Status_Cx0_HAV_offen), 1=Cx1_HAV_geschlossen (CM_BCM_Heizungsabsperrventil_Status_Cx1_HAV_geschlossen), 2=Cx2_Init_oder_nicht_verbaut (CM_BCM_Heizungsabsperrventil_Status_Cx2_Init_oder_nicht_verbaut), 3=Cx3_Fehler (CM_BCM_Heizungsabsperrventil_Status_Cx3_Fehler)}, range raw 0..3, transfer-property=PENDING  # Das Signal beschreibt den Zustand des Heizungsabsperrventils, welches als Portexpander vom BCM1 elektrisch angesteuert wird.
          signal BCM_Heizungspumpe_Status_XIX_Klima_Sensor_02_XIX_E3V_K2CANFD: start 10, 2 bit, little-endian, data-type-policy=OVERRIDE, i-signal-type=PRIMITIVE, init-value=2, base-type=BT_BCM_Heizungspumpe_Status, invalid-value=Invalid_BCM_Heizungspumpe_Status_XIX_Klima_Sensor_02_XIX_E3V_K2CANFD:3, compu {0=Cx0_Pumpe_aus (CM_BCM_Heizungspumpe_Status_Cx0_Pumpe_aus), 1=Cx1_Pumpe_aktiv_und_Stauts_iO (CM_BCM_Heizungspumpe_Status_Cx1_Pumpe_aktiv_und_Stauts_iO), 2=Cx2_Init_oder_nicht_verbaut (CM_BCM_Heizungspumpe_Status_Cx2_Init_oder_nicht_verbaut), 3=Cx3_Fehler (CM_BCM_Heizungspumpe_Status_Cx3_Fehler)}, range raw 0..3, transfer-property=PENDING  # Das Signal beschreibt den Zustand der Heizungspumpe, welche als Portexpander vom BCM1 elektrisch angesteuert wird.
          signal BCM_Kompressorkupplung_Status_XIX_Klima_Sensor_02_XIX_E3V_K2CANFD: start 12, 2 bit, little-endian, data-type-policy=OVERRIDE, i-signal-type=PRIMITIVE, init-value=2, base-type=BT_BCM_Kompressorkupplung_Status, invalid-value=Invalid_BCM_Kompressorkupplung_Status_XIX_Klima_Sensor_02_XIX_E3V_K2CANFD:3, compu {0=Cx0_Kupplung_offen (CM_BCM_Kompressorkupplung_Status_Cx0_Kupplung_offen), 1=Cx1_Kupplung_geschlossen (CM_BCM_Kompressorkupplung_Status_Cx1_Kupplung_geschlossen), 2=Cx2_Init_oder_nicht_verbaut (CM_BCM_Kompressorkupplung_Status_Cx2_Init_oder_nicht_verbaut), 3=Cx3_Fehler (CM_BCM_Kompressorkupplung_Status_Cx3_Fehler)}, range raw 0..3, transfer-property=PENDING  # Das Signal beschreibt den Zustand der Klimakompressorkupplung, welche als Portexpander vom BCM1 elektrisch angesteuert wird.
          signal BCM1_PTC_stufig_Status_XIX_Klima_Sensor_02_XIX_E3V_K2CANFD: start 28, 3 bit, little-endian, data-type-policy=OVERRIDE, i-signal-type=PRIMITIVE, init-value=6, base-type=BT_BCM1_PTC_stufig_Status, invalid-value=Invalid_BCM1_PTC_stufig_Status_XIX_Klima_Sensor_02_XIX_E3V_K2CANFD:7, compu {0=Cx0_Aus (CM_BCM1_PTC_stufig_Status_Cx0_Aus), 1=Cx1_Stufe_1_aktiv (CM_BCM1_PTC_stufig_Status_Cx1_Stufe_1_aktiv), 2=Cx2_Stufe_2_aktiv (CM_BCM1_PTC_stufig_Status_Cx2_Stufe_2_aktiv), 3=Cx3_Stufe_3_aktiv (CM_BCM1_PTC_stufig_Status_Cx3_Stufe_3_aktiv), 6=Cx6_Init_oder_nicht_verbaut (CM_BCM1_PTC_stufig_Status_Cx6_Init_oder_nicht_verbaut), 7=Cx7_Fehler (CM_BCM1_PTC_stufig_Status_Cx7_Fehler)}, range raw 0..7, transfer-property=PENDING  # Status des BCM1-Heizverbrauchers PTC (stufig)
          signal BCM1_FStatus_Aussentemp_ungef_XIX_Klima_Sensor_02_XIX_E3V_K2CANFD: start 31, 1 bit, little-endian, data-type-policy=OVERRIDE, i-signal-type=PRIMITIVE, init-value=1, base-type=BT_BCM1_FStatus_Aussentemp_ungef, compu {0=Cx0_iO (CM_BCM1_FStatus_Aussentemp_ungef_Cx0_iO), 1=Cx1_niO (CM_BCM1_FStatus_Aussentemp_ungef_Cx1_niO)}, range raw 0..1, transfer-property=PENDING  # Fehlerstatus für Aussentemperatur (Kombianzeige)
          signal BCM1_Kompressorstrom_ist_XIX_Klima_Sensor_02_XIX_E3V_K2CANFD: start 32, 8 bit, little-endian, data-type-policy=OVERRIDE, i-signal-type=PRIMITIVE, init-value=254, base-type=BT_BCM1_Kompressorstrom_ist, invalid-value=Invalid_BCM1_Kompressorstrom_ist_XIX_Klima_Sensor_02_XIX_E3V_K2CANFD:255, compu {phys=raw*4 for raw 0..250, 254=Cxfe_Init_bzw_nicht_verfuegbar (CM_BCM1_Kompressorstrom_ist_Cxfe_Init_bzw_nicht_verfuegbar) (Init, bzw. nicht verfuegbar), 255=Cxff_Fehler (CM_BCM1_Kompressorstrom_ist_Cxff_Fehler); unit Unit_MilliAmper}, range phys 0..1000 Unit_MilliAmper, raw 0..255, unit=Unit_MilliAmper, transfer-property=PENDING  # IST-Strom vom Klima-Kompressor
          signal BCM1_OBD_FStatus_ATemp_XIX_Klima_Sensor_02_XIX_E3V_K2CANFD: start 44, 4 bit, little-endian, data-type-policy=OVERRIDE, i-signal-type=PRIMITIVE, init-value=0, base-type=BT_BCM1_OBD_FStatus_ATemp, compu {0=Cx0_kein_Fehler_Init_nicht_verbaut (CM_BCM1_OBD_FStatus_ATemp_Cx0_kein_Fehler_Init_nicht_verbaut) (kein Fehler / Init / nicht verbaut), 1=Cx1_KS_Kurzschluss_nach_minus (CM_BCM1_OBD_FStatus_ATemp_Cx1_KS_Kurzschluss_nach_minus) (KS- (Kurzschluss nach minus)), 2=Cx2_KS_Kurzschluss_nach_plus (CM_BCM1_OBD_FStatus_ATemp_Cx2_KS_Kurzschluss_nach_plus) (KS+ (Kurzschluss nach plus)), 3=Cx3_OC_Leitungsunterbrechung (CM_BCM1_OBD_FStatus_ATemp_Cx3_OC_Leitungsunterbrechung) (OC (Leitungsunterbrechung)), 4=Cx4_OOR_Signal_zu_gross (CM_BCM1_OBD_FStatus_ATemp_Cx4_OOR_Signal_zu_gross) (OOR+ (Signal zu gross)), 5=Cx5_OOR_Signal_zu_klein (CM_BCM1_OBD_FStatus_ATemp_Cx5_OOR_Signal_zu_klein) (OOR- (Signal zu klein)), 6=Cx6_RC_Signal_unplausibel_zu_gross (CM_BCM1_OBD_FStatus_ATemp_Cx6_RC_Signal_unplausibel_zu_gross) (RC+ (Signal unplausibel zu gross)), 7=Cx7_RC_Signal_unplausibel_zu_klein (CM_BCM1_OBD_FStatus_ATemp_Cx7_RC_Signal_unplausibel_zu_klein) (RC- (Signal unplausibel zu klein)), 8=Cx8_KS_OC_Kurzschluss_nach_plus_Unterbrechung (CM_BCM1_OBD_FStatus_ATemp_Cx8_KS_OC_Kurzschluss_nach_plus_Unterbrechung) (KS+/OC (Kurzschluss nach plus/Unterbrechung)), 9=Cx9_KS_OC_Kurzschluss_nach_minus_Unterbrechung (CM_BCM1_OBD_FStatus_ATemp_Cx9_KS_OC_Kurzschluss_nach_minus_Unterbrechung) (KS-/OC (Kurzschluss nach minus/Unterbrechung)), 10=Cxa_KS_KS_Kurzschluss_nach_minus_plus (CM_BCM1_OBD_FStatus_ATemp_Cxa_KS_KS_Kurzschluss_nach_minus_plus) (KS-/KS+ (Kurzschluss nach minus/plus)), 11=Cxb_KS_KS_OC_Kurzschluss_nach_minus_plus_Unterbrechung (CM_BCM1_OBD_FStatus_ATemp_Cxb_KS_KS_OC_Kurzschluss_nach_minus_plus_Unterbrechung) (KS-/KS+/OC (Kurzschluss nach minus/plus/Unterbrechung)), 12=Cxc_frei (CM_BCM1_OBD_FStatus_ATemp_Cxc_frei), 13=Cxd_frei (CM_BCM1_OBD_FStatus_ATemp_Cxd_frei), 14=Cxe_frei (CM_BCM1_OBD_FStatus_ATemp_Cxe_frei), 15=Cxf_frei (CM_BCM1_OBD_FStatus_ATemp_Cxf_frei)}, range raw 0..15, transfer-property=PENDING  # Fehlerstatus Umgebungstemperatursensor (OBD relevanter Sensor)
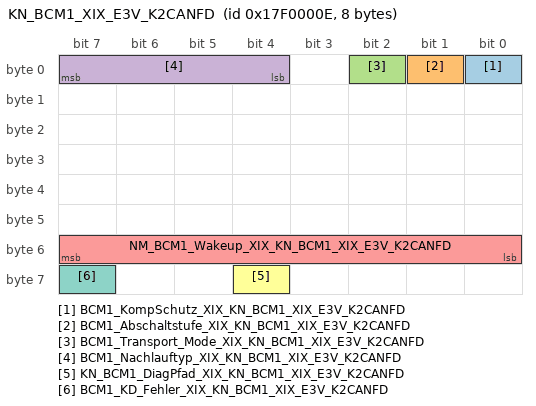
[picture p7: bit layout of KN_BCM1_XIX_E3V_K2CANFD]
      frame KN_BCM1_XIX_E3V_K2CANFD: id 0x17F0000E, from SAM, frame-length=8, can-addressing-mode=EXTENDED, can-frame-rx-behavior=CAN-FD, can-frame-tx-behavior=CAN-FD
        pdu KN_BCM1_XIX_E3V_K2CANFD: length=8, transmission-mode-true-timing=cyclic-timing={time-offset=0.0, time-period=0.5}, unused-bit-pattern=0
          signal BCM1_KompSchutz_XIX_KN_BCM1_XIX_E3V_K2CANFD: start 0, 1 bit, little-endian, data-type-policy=OVERRIDE, i-signal-type=PRIMITIVE, init-value=0, base-type=BT_BCM1_KompSchutz, compu {0=Cx0_inaktiv (CM_BCM1_KompSchutz_Cx0_inaktiv), 1=Cx1_aktiv (CM_BCM1_KompSchutz_Cx1_aktiv)}, range raw 0..1, transfer-property=PENDING  # Funktionseinschränkung aufgrund Komponentenschutz aktiv
          signal BCM1_Abschaltstufe_XIX_KN_BCM1_XIX_E3V_K2CANFD: start 1, 1 bit, little-endian, data-type-policy=OVERRIDE, i-signal-type=PRIMITIVE, init-value=0, base-type=BT_BCM1_Abschaltstufe, compu {0=Cx0_keine_Einschraenkung (CM_BCM1_Abschaltstufe_Cx0_keine_Einschraenkung), 1=Cx1_Funktionseinschraenkung (CM_BCM1_Abschaltstufe_Cx1_Funktionseinschraenkung)}, range raw 0..1, transfer-property=PENDING  # Funktionseinschränkung aufgrund aktiver Abschaltstufe
          signal BCM1_Transport_Mode_XIX_KN_BCM1_XIX_E3V_K2CANFD: start 2, 1 bit, little-endian, data-type-policy=OVERRIDE, i-signal-type=PRIMITIVE, init-value=0, base-type=BT_BCM1_Transport_Mode, compu {0=Cx0_keine_Einschraenkung (CM_BCM1_Transport_Mode_Cx0_keine_Einschraenkung), 1=Cx1_Funktionseinschraenkung (CM_BCM1_Transport_Mode_Cx1_Funktionseinschraenkung)}, range raw 0..1, transfer-property=PENDING  # Funktionseinschränkung aufgrund aktivem Transport Mode und/oder Transport Schutz
          signal BCM1_Nachlauftyp_XIX_KN_BCM1_XIX_E3V_K2CANFD: start 4, 4 bit, little-endian, data-type-policy=OVERRIDE, i-signal-type=PRIMITIVE, init-value=2, base-type=BT_BCM1_Nachlauftyp, compu {0=Cx0_Komm_bei_KL15_EIN (CM_BCM1_Nachlauftyp_Cx0_Komm_bei_KL15_EIN), 1=Cx1_Komm_nach_KL15_AUS (CM_BCM1_Nachlauftyp_Cx1_Komm_nach_KL15_AUS), 2=Cx2_Komm_bei_KL15_AUS (CM_BCM1_Nachlauftyp_Cx2_Komm_bei_KL15_AUS)}, range raw 0..2, transfer-property=PENDING  # Abgebildet wird die von der Hardware vorgegebene Möglichkeit, die Kommunikation nach Klemme 15 = AUS aufrecht zu erhalten. Es wird ein Init-Wert gesendet.
          signal NM_BCM1_Wakeup_XIX_KN_BCM1_XIX_E3V_K2CANFD: start 48, 8 bit, little-endian, data-type-policy=OVERRIDE, i-signal-type=PRIMITIVE, init-value=0, base-type=BT_NM_BCM1_Wakeup, compu {0=Cx0_Peripherie_Wakeup_Ursache_nicht_bekannt (CM_NM_BCM1_Wakeup_Cx0_Peripherie_Wakeup_Ursache_nicht_bekannt) (Peripherie_Wakeup__Ursache_nicht_bekannt), 1=Cx1_CAN_Wakeup (CM_NM_BCM1_Wakeup_Cx1_CAN_Wakeup), 2=Cx2_KL15_HW (CM_NM_BCM1_Wakeup_Cx2_KL15_HW), 3=Cx3_KL30 (CM_NM_BCM1_Wakeup_Cx3_KL30), 4=Cx4_KL58_xs_xt_xd (CM_NM_BCM1_Wakeup_Cx4_KL58_xs_xt_xd), 5=Cx5_Warnblinktaster_EIN (CM_NM_BCM1_Wakeup_Cx5_Warnblinktaster_EIN), 6=Cx6_LDS_Standlicht (CM_NM_BCM1_Wakeup_Cx6_LDS_Standlicht), 7=Cx7_Klemme_S (CM_NM_BCM1_Wakeup_Cx7_Klemme_S), 8=Cx8_Lock_Unlock_Taster (CM_NM_BCM1_Wakeup_Cx8_Lock_Unlock_Taster), 9=Cx9_Heckdeckel_Grifftaster (CM_NM_BCM1_Wakeup_Cx9_Heckdeckel_Grifftaster), 10=Cxa_Funkbefehl (CM_NM_BCM1_Wakeup_Cxa_Funkbefehl), 11=Cxb_Drehfalle_HL (CM_NM_BCM1_Wakeup_Cxb_Drehfalle_HL), 12=Cxc_Drehfalle_HR (CM_NM_BCM1_Wakeup_Cxc_Drehfalle_HR), 13=Cxd_Motorhaubenkontakt (CM_NM_BCM1_Wakeup_Cxd_Motorhaubenkontakt), 14=Cxe_Heckdeckel_Vorraste (CM_NM_BCM1_Wakeup_Cxe_Heckdeckel_Vorraste), 15=Cxf_Heckdeckel_Hauptraste (CM_NM_BCM1_Wakeup_Cxf_Heckdeckel_Hauptraste), 16=Cx10_LDS_Abblendlicht (CM_NM_BCM1_Wakeup_Cx10_LDS_Abblendlicht), 17=Cx11_Drehfalle_FT (CM_NM_BCM1_Wakeup_Cx11_Drehfalle_FT), 18=Cx12_Drehfalle_BT (CM_NM_BCM1_Wakeup_Cx12_Drehfalle_BT), 19=Cx13_Kessy_Schluessel_erkannt (CM_NM_BCM1_Wakeup_Cx13_Kessy_Schluessel_erkannt), 20=Cx14_Heckdeckel_Entriegelungstaster (CM_NM_BCM1_Wakeup_Cx14_Heckdeckel_Entriegelungstaster), 21=Cx15_Schlossrueckmeldung_HL (CM_NM_BCM1_Wakeup_Cx15_Schlossrueckmeldung_HL), 22=Cx16_Schlossrueckmeldung_HR (CM_NM_BCM1_Wakeup_Cx16_Schlossrueckmeldung_HR), 23=Cx17_Lichthupe (CM_NM_BCM1_Wakeup_Cx17_Lichthupe), 25=Cx19_DWA_Heckscheibenbruch (CM_NM_BCM1_Wakeup_Cx19_DWA_Heckscheibenbruch), 26=Cx1a_LIN1 (CM_NM_BCM1_Wakeup_Cx1a_LIN1), 27=Cx1b_LIN2 (CM_NM_BCM1_Wakeup_Cx1b_LIN2), 28=Cx1c_LIN3 (CM_NM_BCM1_Wakeup_Cx1c_LIN3), 29=Cx1d_LIN4 (CM_NM_BCM1_Wakeup_Cx1d_LIN4), 30=Cx1e_LIN5 (CM_NM_BCM1_Wakeup_Cx1e_LIN5), 31=Cx1f_LIN6 (CM_NM_BCM1_Wakeup_Cx1f_LIN6), 33=Cx21_LIN8 (CM_NM_BCM1_Wakeup_Cx21_LIN8), 36=Cx24_LDS_Nebellicht_Nebelschlusslicht (CM_NM_BCM1_Wakeup_Cx24_LDS_Nebellicht_Nebelschlusslicht), 37=Cx25_Valet_Taster (CM_NM_BCM1_Wakeup_Cx25_Valet_Taster), 38=Cx26_Scheinwerferdiebstahlueberwachung (CM_NM_BCM1_Wakeup_Cx26_Scheinwerferdiebstahlueberwachung), 39=Cx27_Versorgung_Innenlicht_KL30g (CM_NM_BCM1_Wakeup_Cx27_Versorgung_Innenlicht_KL30g), 40=Cx28_Display_Taster (CM_NM_BCM1_Wakeup_Cx28_Display_Taster), 41=Cx29_RearMode_Taster (CM_NM_BCM1_Wakeup_Cx29_RearMode_Taster), 42=Cx2a_SAD_Taster (CM_NM_BCM1_Wakeup_Cx2a_SAD_Taster), 43=Cx2b_Rollo_Taster (CM_NM_BCM1_Wakeup_Cx2b_Rollo_Taster), 44=Cx2c_bCall_Taster (CM_NM_BCM1_Wakeup_Cx2c_bCall_Taster), 45=Cx2d_eCall_Taster (CM_NM_BCM1_Wakeup_Cx2d_eCall_Taster), 46=Cx2e_Sitzpneumatikregler (CM_NM_BCM1_Wakeup_Cx2e_Sitzpneumatikregler), 47=Cx2f_Signalhorn (CM_NM_BCM1_Wakeup_Cx2f_Signalhorn), 48=Cx30_Zustandswechsel_ZV_BEV_PHEV (CM_NM_BCM1_Wakeup_Cx30_Zustandswechsel_ZV_BEV_PHEV), 49=Cx31_Ladesteckerentriegelung_BEV_PHEV (CM_NM_BCM1_Wakeup_Cx31_Ladesteckerentriegelung_BEV_PHEV), 50=Cx32_LIN10_WakeUp (CM_NM_BCM1_Wakeup_Cx32_LIN10_WakeUp), 51=Cx33_Taster_Laderaumschliessung (CM_NM_BCM1_Wakeup_Cx33_Taster_Laderaumschliessung), 52=Cx34_STH_Taster (CM_NM_BCM1_Wakeup_Cx34_STH_Taster), 53=Cx35_Defrost_Taster_Betaetigt (CM_NM_BCM1_Wakeup_Cx35_Defrost_Taster_Betaetigt), 54=Cx36_Ladesteckerverriegelung_BEV_PHEV (CM_NM_BCM1_Wakeup_Cx36_Ladesteckerverriegelung_BEV_PHEV), 55=Cx37_TuerInnenGriff_HBFS (CM_NM_BCM1_Wakeup_Cx37_TuerInnenGriff_HBFS), 56=Cx38_TuerInnenGriff_HFS (CM_NM_BCM1_Wakeup_Cx38_TuerInnenGriff_HFS), 57=Cx39_TuerAussenGriff_HBFS (CM_NM_BCM1_Wakeup_Cx39_TuerAussenGriff_HBFS), 58=Cx3a_TuerAussenGriff_HFS (CM_NM_BCM1_Wakeup_Cx3a_TuerAussenGriff_HFS), 60=Cx3c_LIN7_WakeUp (CM_NM_BCM1_Wakeup_Cx3c_LIN7_WakeUp), 61=Cx3d_LIN9_WakeUp (CM_NM_BCM1_Wakeup_Cx3d_LIN9_WakeUp), 62=Cx3e_LIN11_WakeUp (CM_NM_BCM1_Wakeup_Cx3e_LIN11_WakeUp), 63=Cx3f_LIN12_WakeUp (CM_NM_BCM1_Wakeup_Cx3f_LIN12_WakeUp), 64=Cx40_LIN13_WakeUp (CM_NM_BCM1_Wakeup_Cx40_LIN13_WakeUp), 65=Cx41_LIN14_WakeUp (CM_NM_BCM1_Wakeup_Cx41_LIN14_WakeUp), 128=Cx80_ZV_Wiederverriegelung (CM_NM_BCM1_Wakeup_Cx80_ZV_Wiederverriegelung), 129=Cx81_Coming_Home_Ende (CM_NM_BCM1_Wakeup_Cx81_Coming_Home_Ende), 130=Cx82_Leaving_Home_Ende (CM_NM_BCM1_Wakeup_Cx82_Leaving_Home_Ende), 131=Cx83_Softtouch_Freigabe_entziehen (CM_NM_BCM1_Wakeup_Cx83_Softtouch_Freigabe_entziehen), 132=Cx84_Fensterheber_Freigabe_entziehen (CM_NM_BCM1_Wakeup_Cx84_Fensterheber_Freigabe_entziehen), 133=Cx85_Schiebedach_Freigabe_entziehen (CM_NM_BCM1_Wakeup_Cx85_Schiebedach_Freigabe_entziehen), 134=Cx86_Verdeck_Freigabe_entziehen (CM_NM_BCM1_Wakeup_Cx86_Verdeck_Freigabe_entziehen), 135=Cx87_ELV_Freigabe (CM_NM_BCM1_Wakeup_Cx87_ELV_Freigabe), 136=Cx88_KL58xt_Ende (CM_NM_BCM1_Wakeup_Cx88_KL58xt_Ende), 137=Cx89_IRUE_Ausloesung (CM_NM_BCM1_Wakeup_Cx89_IRUE_Ausloesung), 138=Cx8a_NGS_Ausloesung (CM_NM_BCM1_Wakeup_Cx8a_NGS_Ausloesung), 139=Cx8b_Sounder_Alarm (CM_NM_BCM1_Wakeup_Cx8b_Sounder_Alarm), 140=Cx8c_Regenschliessen (CM_NM_BCM1_Wakeup_Cx8c_Regenschliessen), 141=Cx8d_Remotestart (CM_NM_BCM1_Wakeup_Cx8d_Remotestart), 142=Cx8e_Lichtwarnung_Ende (CM_NM_BCM1_Wakeup_Cx8e_Lichtwarnung_Ende), 143=Cx8f_DWA_Alarm (CM_NM_BCM1_Wakeup_Cx8f_DWA_Alarm), 144=Cx90_Innenlicht (CM_NM_BCM1_Wakeup_Cx90_Innenlicht), 145=Cx91_Tankklappe_wurde_geschlossen (CM_NM_BCM1_Wakeup_Cx91_Tankklappe_wurde_geschlossen), 146=Cx92_Parklicht (CM_NM_BCM1_Wakeup_Cx92_Parklicht), 147=Cx93_Klimafunktion (CM_NM_BCM1_Wakeup_Cx93_Klimafunktion), 148=Cx94_Standlicht (CM_NM_BCM1_Wakeup_Cx94_Standlicht), 149=Cx95_Tankklappe_wurde_geoeffnet (CM_NM_BCM1_Wakeup_Cx95_Tankklappe_wurde_geoeffnet), 150=Cx96_SAFE_LED (CM_NM_BCM1_Wakeup_Cx96_SAFE_LED), 151=Cx97_ZV_TAG_aus_einfahren (CM_NM_BCM1_Wakeup_Cx97_ZV_TAG_aus_einfahren), 152=Cx98_CPD_Nutzerwarnung (CM_NM_BCM1_Wakeup_Cx98_CPD_Nutzerwarnung), 254=Cxfe_Watchdog_Test (CM_NM_BCM1_Wakeup_Cxfe_Watchdog_Test), 255=Cxff_Entwicklungsursache (CM_NM_BCM1_Wakeup_Cxff_Entwicklungsursache)}, range raw 0..255, transfer-property=PENDING  # enthält die Weckursache; stehen mehrere Weckursachen parallel an, dann muss der kleinste Wert übertragen werden
          signal KN_BCM1_DiagPfad_XIX_KN_BCM1_XIX_E3V_K2CANFD: start 60, 1 bit, little-endian, data-type-policy=OVERRIDE, i-signal-type=PRIMITIVE, init-value=0, base-type=BT_KN_BCM1_DiagPfad, compu {0=Cx0_aktiv (CM_KN_BCM1_DiagPfad_Cx0_aktiv), 1=Cx1_inaktiv (CM_KN_BCM1_DiagPfad_Cx1_inaktiv)}, range raw 0..1, transfer-property=PENDING  # Kennzeichnung der Diagnosefähigkeit des BusInterfaces eines Steuergerätes (Knoten) Umfang LAH 80127 Bei Nutzung des Signal explizit pro angebundenem BusInterface zu setzen: MQB auf K-CAN = 0 (aktiv) MQB2020 auf K-CAN = 0 (aktiv) MLBevo Gen1 auf K-CAN = 0 (aktiv) MLBevo Gen2 auf K2-CAN = 0 (aktiv) MQBw_Baseline auf K2-CANFD = 0 (aktiv) E3_1_1_MEB auf K-CAN = 0 (aktiv) E3_1_1_UNECE auf K2-CANFD = 0 (aktiv)
          signal BCM1_KD_Fehler_XIX_KN_BCM1_XIX_E3V_K2CANFD: start 63, 1 bit, little-endian, data-type-policy=OVERRIDE, i-signal-type=PRIMITIVE, init-value=0, base-type=BT_BCM1_KD_Fehler, compu {0=Cx0_Kein_KD_Fehler (CM_BCM1_KD_Fehler_Cx0_Kein_KD_Fehler), 1=Cx1_KD_Fehler (CM_BCM1_KD_Fehler_Cx1_KD_Fehler)}, range raw 0..1, transfer-property=PENDING  # Bei gesetztem Bit ist mindestens ein Kundendienstfehler eingetragen
      frame Licht_Anf_01_XIX_E3V_K2CANFD: id 0x3D5, to SAM, frame-length=8, can-addressing-mode=STANDARD, can-frame-rx-behavior=CAN-FD, can-frame-tx-behavior=CAN-FD
        pdu Licht_Anf_01_XIX_E3V_K2CANFD: length=8, minimum-delay=0.05, transmission-mode-true-timing={cyclic-timing={time-offset=0.0, time-period=0.1}, event-controlled-timing={number-of-repetitions=0, repetition-period=0.0}}, unused-bit-pattern=0
          signal Licht_Anf_01_CRC_XIX_Licht_Anf_01_XIX_E3V_K2CANFD: start 0, 8 bit, little-endian, data-type-policy=OVERRIDE, i-signal-type=PRIMITIVE, base-type=BT_Licht_Anf_01_CRC, compu {phys=raw for raw 0..255}, range phys 0..255, raw 0..255, transfer-property=PENDING  # Für MLB: "Berechnung siehe Lastenheft "Kommunikationsabsicherung für FlexRay und CAN"" Ab MQB und MLBevo: "Berechnung siehe Lastenheft "End-to-End Kommunikationsabsicherung"" Endwerte siehe Begleitdokument "S-PDU Kennungsfolgen"
          signal Licht_Anf_01_BZ_XIX_Licht_Anf_01_XIX_E3V_K2CANFD: start 8, 4 bit, little-endian, data-type-policy=OVERRIDE, i-signal-type=PRIMITIVE, base-type=BT_Licht_Anf_01_BZ, compu {phys=raw for raw 0..15}, range phys 0..15, raw 0..15, transfer-property=PENDING  # 4bit Botschaftszaehler, wird mit jeder Sendebotschaft inkrementiert
          signal BCM1_Kurvenlicht_links_Anf_XIX_Licht_Anf_01_XIX_E3V_K2CANFD: start 12, 1 bit, little-endian, data-type-policy=OVERRIDE, i-signal-type=PRIMITIVE, init-value=0, base-type=BT_BCM1_Kurvenlicht_links_Anf, compu {0=Cx0_linkes_Kurvenlicht_Abbiegelicht_durch_BCM1_nicht_angesteuert (CM_BCM1_Kurvenlicht_links_Anf_Cx0_linkes_Kurvenlicht_Abbiegelicht_durch_BCM1_nicht_angesteuert) (linkes_Kurvenlicht/Abbiegelicht_durch_BCM1_nicht_angesteuert), 1=Cx1_linkes_Kurven_Abbiegelicht_durch_BCM1_angesteuert (CM_BCM1_Kurvenlicht_links_Anf_Cx1_linkes_Kurven_Abbiegelicht_durch_BCM1_angesteuert) (linkes_Kurven/Abbiegelicht_durch_BCM1_angesteuert)}, range raw 0..1, transfer-property=PENDING  # Ansteuerung linkes Kurvenlicht/Abbiegelicht duch BCM1
          signal BCM1_Kurvenlicht_rechts_Anf_XIX_Licht_Anf_01_XIX_E3V_K2CANFD: start 13, 1 bit, little-endian, data-type-policy=OVERRIDE, i-signal-type=PRIMITIVE, init-value=0, base-type=BT_BCM1_Kurvenlicht_rechts_Anf, compu {0=Cx0_rechtes_Kurvenlicht_Abbiegelicht_durch_BCM1_nicht_angesteuert (CM_BCM1_Kurvenlicht_rechts_Anf_Cx0_rechtes_Kurvenlicht_Abbiegelicht_durch_BCM1_nicht_angesteuert) (rechtes_Kurvenlicht/Abbiegelicht_durch_BCM1_nicht_angesteuert), 1=Cx1_rechtes_Kurvenlicht_Abbiegelicht_durch_BCM1_angesteuert (CM_BCM1_Kurvenlicht_rechts_Anf_Cx1_rechtes_Kurvenlicht_Abbiegelicht_durch_BCM1_angesteuert) (rechtes_Kurvenlicht/Abbiegelicht_durch_BCM1_angesteuert)}, range raw 0..1, transfer-property=PENDING  # Ansteuerung rechtes Kurvenlicht/Abbiegelicht duch BCM1
          signal BCM1_Standlicht_Anf_XIX_Licht_Anf_01_XIX_E3V_K2CANFD: start 14, 1 bit, little-endian, data-type-policy=OVERRIDE, i-signal-type=PRIMITIVE, init-value=0, base-type=BT_BCM1_Standlicht_Anf, compu {0=Cx0_Licht_nicht_angefordert (CM_BCM1_Standlicht_Anf_Cx0_Licht_nicht_angefordert), 1=Cx1_Licht_ist_einzuschalten (CM_BCM1_Standlicht_Anf_Cx1_Licht_ist_einzuschalten) (Licht ist einzuschalten)}, range raw 0..1, transfer-property=PENDING, to SAM(timeout 1 s)  # Anforderung: Schlusslicht (Sollzustand)
          signal BCM1_Abblendlicht_Anf_XIX_Licht_Anf_01_XIX_E3V_K2CANFD: start 15, 1 bit, little-endian, data-type-policy=OVERRIDE, i-signal-type=PRIMITIVE, init-value=0, base-type=BT_BCM1_Abblendlicht_Anf, compu {0=Cx0_Licht_nicht_angefordert (CM_BCM1_Abblendlicht_Anf_Cx0_Licht_nicht_angefordert), 1=Cx1_Licht_ist_einzuschalten (CM_BCM1_Abblendlicht_Anf_Cx1_Licht_ist_einzuschalten) (Licht ist einzuschalten)}, range raw 0..1, transfer-property=PENDING  # Anforderung Abblendlicht
          signal BCM1_Fernlicht_Anf_XIX_Licht_Anf_01_XIX_E3V_K2CANFD: start 16, 1 bit, little-endian, data-type-policy=OVERRIDE, i-signal-type=PRIMITIVE, init-value=0, base-type=BT_BCM1_Fernlicht_Anf, compu {0=Cx0_Licht_nicht_angefordert (CM_BCM1_Fernlicht_Anf_Cx0_Licht_nicht_angefordert), 1=Cx1_Licht_ist_einzuschalten (CM_BCM1_Fernlicht_Anf_Cx1_Licht_ist_einzuschalten) (Licht ist einzuschalten)}, range raw 0..1, transfer-property=PENDING  # Anforderung Fernlicht
          signal BCM1_Nebellicht_Anf_XIX_Licht_Anf_01_XIX_E3V_K2CANFD: start 17, 1 bit, little-endian, data-type-policy=OVERRIDE, i-signal-type=PRIMITIVE, init-value=0, base-type=BT_BCM1_Nebellicht_Anf, compu {0=Cx0_Licht_nicht_angefordert (CM_BCM1_Nebellicht_Anf_Cx0_Licht_nicht_angefordert), 1=Cx1_Licht_ist_einzuschalten (CM_BCM1_Nebellicht_Anf_Cx1_Licht_ist_einzuschalten) (Licht ist einzuschalten)}, range raw 0..1, transfer-property=PENDING  # Anforderung Nebellicht
          signal BCM1_Parklicht_li_Anf_XIX_Licht_Anf_01_XIX_E3V_K2CANFD: start 18, 1 bit, little-endian, data-type-policy=OVERRIDE, i-signal-type=PRIMITIVE, init-value=0, base-type=BT_BCM1_Parklicht_li_Anf, compu {0=Cx0_Licht_nicht_angefordert (CM_BCM1_Parklicht_li_Anf_Cx0_Licht_nicht_angefordert), 1=Cx1_Licht_ist_einzuschalten (CM_BCM1_Parklicht_li_Anf_Cx1_Licht_ist_einzuschalten) (Licht ist einzuschalten)}, range raw 0..1, transfer-property=PENDING, to SAM(timeout 1 s)  # Anforderung: Parklicht links (Sollzustand)
          signal BCM1_Parklicht_re_Anf_XIX_Licht_Anf_01_XIX_E3V_K2CANFD: start 19, 1 bit, little-endian, data-type-policy=OVERRIDE, i-signal-type=PRIMITIVE, init-value=0, base-type=BT_BCM1_Parklicht_re_Anf, compu {0=Cx0_Licht_nicht_angefordert (CM_BCM1_Parklicht_re_Anf_Cx0_Licht_nicht_angefordert), 1=Cx1_Licht_ist_einzuschalten (CM_BCM1_Parklicht_re_Anf_Cx1_Licht_ist_einzuschalten) (Licht ist einzuschalten)}, range raw 0..1, transfer-property=PENDING, to SAM(timeout 1 s)  # Anforderung: Parklicht rechts (Sollzustand)
          signal BCM1_Nebelschluss_Ahg_Anf_XIX_Licht_Anf_01_XIX_E3V_K2CANFD: start 20, 1 bit, little-endian, data-type-policy=OVERRIDE, i-signal-type=PRIMITIVE, init-value=0, base-type=BT_BCM1_Nebelschluss_Ahg_Anf, compu {0=Cx0_Licht_nicht_angefordert (CM_BCM1_Nebelschluss_Ahg_Anf_Cx0_Licht_nicht_angefordert), 1=Cx1_Licht_ist_einzuschalten (CM_BCM1_Nebelschluss_Ahg_Anf_Cx1_Licht_ist_einzuschalten) (Licht ist einzuschalten)}, range raw 0..1, transfer-property=PENDING  # Anforderung: Nebelschlusslicht Anhänger (Sollzustand)
          signal BCM1_Nebelschluss_Fzg_Anf_XIX_Licht_Anf_01_XIX_E3V_K2CANFD: start 21, 1 bit, little-endian, data-type-policy=OVERRIDE, i-signal-type=PRIMITIVE, init-value=0, base-type=BT_BCM1_Nebelschluss_Fzg_Anf, compu {0=Cx0_Licht_nicht_angefordert (CM_BCM1_Nebelschluss_Fzg_Anf_Cx0_Licht_nicht_angefordert), 1=Cx1_Licht_ist_einzuschalten (CM_BCM1_Nebelschluss_Fzg_Anf_Cx1_Licht_ist_einzuschalten)}, range raw 0..1, transfer-property=PENDING, to SAM(timeout 1 s)  # Anforderung: Nebelschlusslicht Fahrzeug (Sollzustand)
          signal BCM1_Schlusslicht_Anf_XIX_Licht_Anf_01_XIX_E3V_K2CANFD: start 22, 1 bit, little-endian, data-type-policy=OVERRIDE, i-signal-type=PRIMITIVE, init-value=0, base-type=BT_BCM1_Schlusslicht_Anf, compu {0=Cx0_Licht_nicht_angefordert (CM_BCM1_Schlusslicht_Anf_Cx0_Licht_nicht_angefordert), 1=Cx1_Licht_ist_einzuschalten (CM_BCM1_Schlusslicht_Anf_Cx1_Licht_ist_einzuschalten) (Licht ist einzuschalten)}, range raw 0..1, transfer-property=PENDING, to SAM(timeout 1 s)  # Anforderung: Schlusslicht Fahrzeug (Sollzustand)
          signal BCM_Rueckfahrlicht_Anf_XIX_Licht_Anf_01_XIX_E3V_K2CANFD: start 23, 1 bit, little-endian, data-type-policy=OVERRIDE, i-signal-type=PRIMITIVE, init-value=0, base-type=BT_BCM_Rueckfahrlicht_Anf, compu {0=Cx0_Licht_nicht_angefordert (CM_BCM_Rueckfahrlicht_Anf_Cx0_Licht_nicht_angefordert), 1=Cx1_Licht_angefordert (CM_BCM_Rueckfahrlicht_Anf_Cx1_Licht_angefordert)}, range raw 0..1, transfer-property=PENDING, to SAM(timeout 1 s)  # Anforderung Rückfahrlicht (Sollzustand). Das Signal wird entprellt (typisch 400ms) und bei KL15EIN gesendet. Das Signal ist unabhängig von der Position des Heckdeckels (kein Überhitzungsschutz).
          signal BCM1_Signaturlicht_Anf_XIX_Licht_Anf_01_XIX_E3V_K2CANFD: start 24, 1 bit, little-endian, data-type-policy=OVERRIDE, i-signal-type=PRIMITIVE, init-value=0, base-type=BT_BCM1_Signaturlicht_Anf, compu {0=Cx0_Licht_nicht_angefordert (CM_BCM1_Signaturlicht_Anf_Cx0_Licht_nicht_angefordert), 1=Cx1_Licht_ist_einzuschalten (CM_BCM1_Signaturlicht_Anf_Cx1_Licht_ist_einzuschalten)}, range raw 0..1, transfer-property=PENDING  # Signal zur Anforderung des Signaturlichts
          signal BCM1_Umfeldleuchten_Anf_XIX_Licht_Anf_01_XIX_E3V_K2CANFD: start 25, 1 bit, little-endian, data-type-policy=OVERRIDE, i-signal-type=PRIMITIVE, init-value=0, base-type=BT_BCM1_Umfeldleuchten_Anf, compu {0=Cx0_Licht_nicht_angefordert (CM_BCM1_Umfeldleuchten_Anf_Cx0_Licht_nicht_angefordert), 1=Cx1_Licht_ist_einzuschalten (CM_BCM1_Umfeldleuchten_Anf_Cx1_Licht_ist_einzuschalten)}, range raw 0..1, transfer-property=PENDING, to SAM(timeout 1 s)  # Anforderung für Umfeldleuchten
          signal BCM1_Tagfahrlicht_Anf_XIX_Licht_Anf_01_XIX_E3V_K2CANFD: start 26, 1 bit, little-endian, data-type-policy=OVERRIDE, i-signal-type=PRIMITIVE, init-value=0, base-type=BT_BCM1_Tagfahrlicht_Anf, compu {0=Cx0_Licht_nicht_angefordert (CM_BCM1_Tagfahrlicht_Anf_Cx0_Licht_nicht_angefordert), 1=Cx1_Licht_ist_einzuschalten (CM_BCM1_Tagfahrlicht_Anf_Cx1_Licht_ist_einzuschalten) (Licht ist einzuschalten)}, range raw 0..1, transfer-property=PENDING  # Anforderung: Tagfahrlicht (Sollzustand)
          signal BCM1_Regenlicht_Anf_XIX_Licht_Anf_01_XIX_E3V_K2CANFD: start 27, 1 bit, little-endian, data-type-policy=OVERRIDE, i-signal-type=PRIMITIVE, init-value=0, base-type=BT_BCM1_Regenlicht_Anf, compu {0=Cx0_Licht_nicht_angefordert (CM_BCM1_Regenlicht_Anf_Cx0_Licht_nicht_angefordert), 1=Cx1_Licht_ist_einzuschalten (CM_BCM1_Regenlicht_Anf_Cx1_Licht_ist_einzuschalten) (Licht ist einzuschalten)}, range raw 0..1, transfer-property=PENDING  # Anforderung: Regenlicht (Sollzustand)
          signal BCM1_Autobahnlicht_Anf_XIX_Licht_Anf_01_XIX_E3V_K2CANFD: start 28, 1 bit, little-endian, data-type-policy=OVERRIDE, i-signal-type=PRIMITIVE, init-value=0, base-type=BT_BCM1_Autobahnlicht_Anf, compu {0=Cx0_Licht_nicht_angefordert (CM_BCM1_Autobahnlicht_Anf_Cx0_Licht_nicht_angefordert), 1=Cx1_Licht_ist_einzuschalten (CM_BCM1_Autobahnlicht_Anf_Cx1_Licht_ist_einzuschalten) (Licht ist einzuschalten)}, range raw 0..1, transfer-property=PENDING  # Anforderung Autobahnlicht
          signal BCM1_Touristen_Licht_Anf_XIX_Licht_Anf_01_XIX_E3V_K2CANFD: start 29, 1 bit, little-endian, data-type-policy=OVERRIDE, i-signal-type=PRIMITIVE, init-value=0, base-type=BT_BCM1_Touristen_Licht_Anf, compu {0=Cx0_Licht_nicht_angefordert (CM_BCM1_Touristen_Licht_Anf_Cx0_Licht_nicht_angefordert), 1=Cx1_Anforderung_von_Touristenlicht (CM_BCM1_Touristen_Licht_Anf_Cx1_Anforderung_von_Touristenlicht) (Anforderung von Touristenlicht)}, range raw 0..1, transfer-property=PENDING  # Anforderung: Touristenlicht (Sollzustand)
          signal BCM1_CH_aktiv_XIX_Licht_Anf_01_XIX_E3V_K2CANFD: start 30, 1 bit, little-endian, data-type-policy=OVERRIDE, i-signal-type=PRIMITIVE, init-value=0, base-type=BT_BCM1_CH_aktiv, compu {0=Cx0_Inaktiv (CM_BCM1_CH_aktiv_Cx0_Inaktiv), 1=Cx1_Aktiv (CM_BCM1_CH_aktiv_Cx1_Aktiv)}, range raw 0..1, transfer-property=PENDING  # Coming Home (zusätzlich zum Signal 'BCM1_CH_LH_aktiv' in der Botschaft BCM1_01)
          signal BCM1_LH_aktiv_XIX_Licht_Anf_01_XIX_E3V_K2CANFD: start 31, 1 bit, little-endian, data-type-policy=OVERRIDE, i-signal-type=PRIMITIVE, init-value=0, base-type=BT_BCM1_LH_aktiv, compu {0=Cx0_Inaktiv (CM_BCM1_LH_aktiv_Cx0_Inaktiv), 1=Cx1_Aktiv (CM_BCM1_LH_aktiv_Cx1_Aktiv)}, range raw 0..1, transfer-property=PENDING  # Leaving Home (zusätzlich zum Signal 'BCM1_CH_LH_aktiv' in der Botschaft BCM1_01)
          signal BCM1_Gleitende_Leuchtw_Anf_XIX_Licht_Anf_01_XIX_E3V_K2CANFD: start 32, 1 bit, little-endian, data-type-policy=OVERRIDE, i-signal-type=PRIMITIVE, init-value=0, base-type=BT_BCM1_Gleitende_Leuchtw_Anf, compu {0=Cx0_Aus (CM_BCM1_Gleitende_Leuchtw_Anf_Cx0_Aus), 1=Cx1_Ein (CM_BCM1_Gleitende_Leuchtw_Anf_Cx1_Ein)}, range raw 0..1, transfer-property=PENDING  # Funktion "Gleitende Leuchtweite" im AFS-SG freischalten
          signal BCM1_GLW_Fernlicht_Anf_XIX_Licht_Anf_01_XIX_E3V_K2CANFD: start 33, 1 bit, little-endian, data-type-policy=OVERRIDE, i-signal-type=PRIMITIVE, init-value=0, base-type=BT_BCM1_GLW_Fernlicht_Anf, compu {0=Cx0_Aus (CM_BCM1_GLW_Fernlicht_Anf_Cx0_Aus), 1=Cx1_Ein (CM_BCM1_GLW_Fernlicht_Anf_Cx1_Ein)}, range raw 0..1, transfer-property=TRIGGERED-ON-CHANGE-WITHOUT-REPETITION  # Harte Fernlichtanforderung von BCM1 an die Funktion "gleitende Leuchtweite" im AFS-SG
          signal BCM1_Adaptive_Lichtvert_Anf_XIX_Licht_Anf_01_XIX_E3V_K2CANFD: start 34, 1 bit, little-endian, data-type-policy=OVERRIDE, i-signal-type=PRIMITIVE, init-value=0, base-type=BT_BCM1_Adaptive_Lichtvert_Anf, compu {0=Cx0_Aus (CM_BCM1_Adaptive_Lichtvert_Anf_Cx0_Aus), 1=Cx1_Ein (CM_BCM1_Adaptive_Lichtvert_Anf_Cx1_Ein)}, range raw 0..1, transfer-property=PENDING  # Funktion "Adaptive Lichtverteilung" im AFS-SG Ein- und Ausschalten
          signal BCM1_CH_LH_aktiv_XIX_Licht_Anf_01_XIX_E3V_K2CANFD: start 40, 1 bit, little-endian, data-type-policy=OVERRIDE, i-signal-type=PRIMITIVE, init-value=0, base-type=BT_BCM1_CH_LH_aktiv, compu {0=Cx0_Comming_Home_Bzw_Leaving_Home_nicht_aktiv (CM_BCM1_CH_LH_aktiv_Cx0_Comming_Home_Bzw_Leaving_Home_nicht_aktiv) (Comming_Home_Bzw._Leaving_Home_nicht_aktiv), 1=Cx1_Comming_Home_bzw_Leaving_Home_aktiv (CM_BCM1_CH_LH_aktiv_Cx1_Comming_Home_bzw_Leaving_Home_aktiv) (Comming Home bzw. Leaving Home aktiv)}, range raw 0..1, transfer-property=PENDING, to SAM(timeout 1 s)  # Status Comming / Leaving Home
          signal BCM1_Allwetterlicht_Anf_XIX_Licht_Anf_01_XIX_E3V_K2CANFD: start 41, 1 bit, little-endian, data-type-policy=OVERRIDE, i-signal-type=PRIMITIVE, init-value=0, base-type=BT_BCM1_Allwetterlicht_Anf, compu {0=Cx0_Licht_nicht_angefordert (CM_BCM1_Allwetterlicht_Anf_Cx0_Licht_nicht_angefordert), 1=Cx1_Licht_ist_einzuschalten (CM_BCM1_Allwetterlicht_Anf_Cx1_Licht_ist_einzuschalten)}, range raw 0..1, transfer-property=PENDING  # Anforderung eines Allwetterlichts (über AFS-SG realisiert): Licht für schlechte Sichtverhältnisse
          signal TFL_Matrix_Variante01_Anf_XIX_Licht_Anf_01_XIX_E3V_K2CANFD: start 42, 1 bit, little-endian, data-type-policy=OVERRIDE, i-signal-type=PRIMITIVE, init-value=0, base-type=BT_TFL_Matrix_Variante01_Anf, compu {0=Cx0_nicht_angefordert (CM_TFL_Matrix_Variante01_Anf_Cx0_nicht_angefordert), 1=Cx1_angefordert (CM_TFL_Matrix_Variante01_Anf_Cx1_angefordert)}, range raw 0..1, transfer-property=TRIGGERED-ON-CHANGE-WITHOUT-REPETITION  # Gibt die einzustellende Variante der Tagfahrlicht-Matrix an.
          signal TFL_Matrix_Variante02_Anf_XIX_Licht_Anf_01_XIX_E3V_K2CANFD: start 43, 1 bit, little-endian, data-type-policy=OVERRIDE, i-signal-type=PRIMITIVE, init-value=0, base-type=BT_TFL_Matrix_Variante02_Anf, compu {0=Cx0_nicht_angefordert (CM_TFL_Matrix_Variante02_Anf_Cx0_nicht_angefordert), 1=Cx1_angefordert (CM_TFL_Matrix_Variante02_Anf_Cx1_angefordert)}, range raw 0..1, transfer-property=TRIGGERED-ON-CHANGE-WITHOUT-REPETITION  # Gibt die einzustellende Variante der Tagfahrlicht-Matrix an.
          signal TFL_Matrix_Variante03_Anf_XIX_Licht_Anf_01_XIX_E3V_K2CANFD: start 44, 1 bit, little-endian, data-type-policy=OVERRIDE, i-signal-type=PRIMITIVE, init-value=0, base-type=BT_TFL_Matrix_Variante03_Anf, compu {0=Cx0_nicht_angefordert (CM_TFL_Matrix_Variante03_Anf_Cx0_nicht_angefordert), 1=Cx1_angefordert (CM_TFL_Matrix_Variante03_Anf_Cx1_angefordert)}, range raw 0..1, transfer-property=TRIGGERED-ON-CHANGE-WITHOUT-REPETITION  # Gibt die einzustellende Variante der Tagfahrlicht-Matrix an.
          signal TFL_Matrix_Variante04_Anf_XIX_Licht_Anf_01_XIX_E3V_K2CANFD: start 45, 1 bit, little-endian, data-type-policy=OVERRIDE, i-signal-type=PRIMITIVE, init-value=0, base-type=BT_TFL_Matrix_Variante04_Anf, compu {0=Cx0_nicht_angefordert (CM_TFL_Matrix_Variante04_Anf_Cx0_nicht_angefordert), 1=Cx1_angefordert (CM_TFL_Matrix_Variante04_Anf_Cx1_angefordert)}, range raw 0..1, transfer-property=TRIGGERED-ON-CHANGE-WITHOUT-REPETITION  # Gibt die einzustellende Variante der Tagfahrlicht-Matrix an.
          signal BCM1_Fahrlicht_Hinweis_XIX_Licht_Anf_01_XIX_E3V_K2CANFD: start 46, 1 bit, little-endian, data-type-policy=OVERRIDE, i-signal-type=PRIMITIVE, init-value=0, base-type=BT_BCM1_Fahrlicht_Hinweis, compu {0=Cx0_kein_Fahrlicht_Hinweis (CM_BCM1_Fahrlicht_Hinweis_Cx0_kein_Fahrlicht_Hinweis), 1=Cx1_Fahrlicht_Hinweis (CM_BCM1_Fahrlicht_Hinweis_Cx1_Fahrlicht_Hinweis)}, range raw 0..1, transfer-property=TRIGGERED-ON-CHANGE-WITHOUT-REPETITION  # Signal zum Kombi um den Hinweis "Bitte Fahrlicht einschalten" anzufordern
          signal BCM1_Lichtwarn_Texte_XIX_Licht_Anf_01_XIX_E3V_K2CANFD: start 47, 2 bit, little-endian, data-type-policy=OVERRIDE, i-signal-type=PRIMITIVE, init-value=0, base-type=BT_BCM1_Lichtwarn_Texte, compu {0=Cx0_keine_Warnung (CM_BCM1_Lichtwarn_Texte_Cx0_keine_Warnung), 1=Cx1_Standlichtwarnung (CM_BCM1_Lichtwarn_Texte_Cx1_Standlichtwarnung), 2=Cx2_Parklichtwarnung (CM_BCM1_Lichtwarn_Texte_Cx2_Parklichtwarnung), 3=Cx3_Nebelschlusslichtwarnung (CM_BCM1_Lichtwarn_Texte_Cx3_Nebelschlusslichtwarnung)}, range raw 0..3, transfer-property=TRIGGERED-ON-CHANGE-WITHOUT-REPETITION  # Anforderung von Lichtwarnungen vom BCM1 zum Kombi MLB: nur Werte 0..2
          signal BCM1_Hinweis_Lichtnachlauf_XIX_Licht_Anf_01_XIX_E3V_K2CANFD: start 49, 1 bit, little-endian, data-type-policy=OVERRIDE, i-signal-type=PRIMITIVE, init-value=0, base-type=BT_BCM1_Hinweis_Lichtnachlauf, compu {0=Cx0_inaktiv (CM_BCM1_Hinweis_Lichtnachlauf_Cx0_inaktiv), 1=Cx1_aktiv (CM_BCM1_Hinweis_Lichtnachlauf_Cx1_aktiv)}, range raw 0..1, transfer-property=TRIGGERED-ON-CHANGE-WITHOUT-REPETITION  # Signal dient der Anzeige eines aktiven Lichtnachlaufes beim automatischen Abschalten der Klemme S und Klemme 15. Der Lichtnachlauf wird gestartet, wenn die Klemme 15 bei aktivem Fahrlicht deaktiviert wird.
      frame Licht_hinten_Slave_01_XIX_E3V_K2CANFD: id 0x16A954F9, from SAM, frame-length=8, can-addressing-mode=EXTENDED, can-frame-rx-behavior=CAN-FD, can-frame-tx-behavior=CAN-FD
        pdu Licht_hinten_Slave_01_XIX_E3V_K2CANFD: length=8, minimum-delay=0.05, transmission-mode-true-timing={cyclic-timing={time-offset=0.0, time-period=1.0}, event-controlled-timing={number-of-repetitions=0, repetition-period=0.0}}, unused-bit-pattern=0
          signal LH_S_Rueckf_li_def_XIX_Licht_hinten_Slave_01_XIX_E3V_K2CANFD: start 12, 1 bit, little-endian, data-type-policy=OVERRIDE, i-signal-type=PRIMITIVE, init-value=0, base-type=BT_LH_S_Rueckf_li_def, compu {0=Cx0_iO (CM_LH_S_Rueckf_li_def_Cx0_iO), 1=Cx1_defekt (CM_LH_S_Rueckf_li_def_Cx1_defekt)}, range raw 0..1, transfer-property=TRIGGERED-ON-CHANGE-WITHOUT-REPETITION  # Neues Signal Licht-Hinten-Slave an Licht-Master: Fehlererkennung Rückfahrlicht hinten links
          signal LH_S_Rueckf_mi_def_XIX_Licht_hinten_Slave_01_XIX_E3V_K2CANFD: start 13, 1 bit, little-endian, data-type-policy=OVERRIDE, i-signal-type=PRIMITIVE, init-value=0, base-type=BT_LH_S_Rueckf_mi_def, compu {0=Cx0_iO (CM_LH_S_Rueckf_mi_def_Cx0_iO), 1=Cx1_defekt (CM_LH_S_Rueckf_mi_def_Cx1_defekt)}, range raw 0..1, transfer-property=TRIGGERED-ON-CHANGE-WITHOUT-REPETITION  # Neues Signal Licht-Hinten-Slave an Licht-Master: Fehlererkennung Nebelschlusslicht hinten Mitte
          signal LH_S_Rueckf_re_def_XIX_Licht_hinten_Slave_01_XIX_E3V_K2CANFD: start 14, 1 bit, little-endian, data-type-policy=OVERRIDE, i-signal-type=PRIMITIVE, init-value=0, base-type=BT_LH_S_Rueckf_re_def, compu {0=Cx0_iO (CM_LH_S_Rueckf_re_def_Cx0_iO), 1=Cx1_defekt (CM_LH_S_Rueckf_re_def_Cx1_defekt)}, range raw 0..1, transfer-property=TRIGGERED-ON-CHANGE-WITHOUT-REPETITION  # Neues Signal Licht-Hinten-Slave an Licht-Master: Fehlererkennung Rückfahrlicht hinten rechts
          signal LH_S_Schluss_Brems_li_def_XIX_Licht_hinten_Slave_01_XIX_E3V_K2CANFD: start 15, 1 bit, little-endian, data-type-policy=OVERRIDE, i-signal-type=PRIMITIVE, init-value=0, base-type=BT_LH_S_Schluss_Brems_li_def, compu {0=Cx0_iO (CM_LH_S_Schluss_Brems_li_def_Cx0_iO), 1=Cx1_defekt (CM_LH_S_Schluss_Brems_li_def_Cx1_defekt)}, range raw 0..1, transfer-property=TRIGGERED-ON-CHANGE-WITHOUT-REPETITION  # Neues Signal Licht-Hinten-Slave an Licht-Master: Konfiguration SL+ BRL + PL links und SL+ BRL links
          signal LH_S_Schluss_Brems_Nebel_li_def_XIX_Licht_hinten_Slave_01_XIX_E3V_K2CANFD: start 16, 1 bit, little-endian, data-type-policy=OVERRIDE, i-signal-type=PRIMITIVE, init-value=0, base-type=BT_LH_S_Schluss_Brems_Nebel_li_def, compu {0=Cx0_iO (CM_LH_S_Schluss_Brems_Nebel_li_def_Cx0_iO), 1=Cx1_defekt (CM_LH_S_Schluss_Brems_Nebel_li_def_Cx1_defekt)}, range raw 0..1, transfer-property=TRIGGERED-ON-CHANGE-WITHOUT-REPETITION  # Neues Signal Licht-Hinten-Slave an Licht-Master: Signal wird gesetzt, wenn eine Unterbrechung oder ein Kurzschluss am Lampenausgang für Schluss_Brems_Nebelschlusslicht erkannt wird.
          signal LH_S_Schluss_Brems_Nebel_re_def_XIX_Licht_hinten_Slave_01_XIX_E3V_K2CANFD: start 17, 1 bit, little-endian, data-type-policy=OVERRIDE, i-signal-type=PRIMITIVE, init-value=0, base-type=BT_LH_S_Schluss_Brems_Nebel_re_def, compu {0=Cx0_iO (CM_LH_S_Schluss_Brems_Nebel_re_def_Cx0_iO), 1=Cx1_defekt (CM_LH_S_Schluss_Brems_Nebel_re_def_Cx1_defekt)}, range raw 0..1, transfer-property=TRIGGERED-ON-CHANGE-WITHOUT-REPETITION  # Neues Signal Licht-Hinten-Slave an Licht-Master: Signal wird gesetzt, wenn eine Unterbrechung oder ein Kurzschluss am Lampenausgang für Schluss_Brems_Nebelschlusslicht erkannt wird.
          signal LH_S_Schluss_Brems_re_def_XIX_Licht_hinten_Slave_01_XIX_E3V_K2CANFD: start 18, 1 bit, little-endian, data-type-policy=OVERRIDE, i-signal-type=PRIMITIVE, init-value=0, base-type=BT_LH_S_Schluss_Brems_re_def, compu {0=Cx0_iO (CM_LH_S_Schluss_Brems_re_def_Cx0_iO), 1=Cx1_defekt (CM_LH_S_Schluss_Brems_re_def_Cx1_defekt)}, range raw 0..1, transfer-property=TRIGGERED-ON-CHANGE-WITHOUT-REPETITION  # Neues Signal Licht-Hinten-Slave an Licht-Master: Konfiguration SL+ BRL + PL rechts und SL+ BRL rechts
          signal LH_S_Schluss_Nebel_li_def_XIX_Licht_hinten_Slave_01_XIX_E3V_K2CANFD: start 19, 1 bit, little-endian, data-type-policy=OVERRIDE, i-signal-type=PRIMITIVE, init-value=0, base-type=BT_LH_S_Schluss_Nebel_li_def, compu {0=Cx0_iO (CM_LH_S_Schluss_Nebel_li_def_Cx0_iO), 1=Cx1_defekt (CM_LH_S_Schluss_Nebel_li_def_Cx1_defekt)}, range raw 0..1, transfer-property=TRIGGERED-ON-CHANGE-WITHOUT-REPETITION  # Neues Signal Licht-Hinten-Slave an Licht-Master: Konfiguration SL + NSL links oder SL + NSL + PL links
          signal LH_S_Schluss_Nebel_re_def_XIX_Licht_hinten_Slave_01_XIX_E3V_K2CANFD: start 20, 1 bit, little-endian, data-type-policy=OVERRIDE, i-signal-type=PRIMITIVE, init-value=0, base-type=BT_LH_S_Schluss_Nebel_re_def, compu {0=Cx0_iO (CM_LH_S_Schluss_Nebel_re_def_Cx0_iO), 1=Cx1_defekt (CM_LH_S_Schluss_Nebel_re_def_Cx1_defekt)}, range raw 0..1, transfer-property=TRIGGERED-ON-CHANGE-WITHOUT-REPETITION  # Neues Signal Licht-Hinten-Slave an Licht-Master: Konfiguration SL + NSL rechts oder SL + NSL + PL rechts
          signal LH_S_Schlusslicht_li_def_XIX_Licht_hinten_Slave_01_XIX_E3V_K2CANFD: start 21, 1 bit, little-endian, data-type-policy=OVERRIDE, i-signal-type=PRIMITIVE, init-value=0, base-type=BT_LH_S_Schlusslicht_li_def, compu {0=Cx0_iO (CM_LH_S_Schlusslicht_li_def_Cx0_iO), 1=Cx1_defekt (CM_LH_S_Schlusslicht_li_def_Cx1_defekt)}, range raw 0..1, transfer-property=TRIGGERED-ON-CHANGE-WITHOUT-REPETITION  # Neues Signal Licht-Hinten-Slave an Licht-Master: Fehlererkennung Schlusslicht hinten links
          signal LH_S_Schlusslicht_re_def_XIX_Licht_hinten_Slave_01_XIX_E3V_K2CANFD: start 22, 1 bit, little-endian, data-type-policy=OVERRIDE, i-signal-type=PRIMITIVE, init-value=0, base-type=BT_LH_S_Schlusslicht_re_def, compu {0=Cx0_iO (CM_LH_S_Schlusslicht_re_def_Cx0_iO), 1=Cx1_defekt (CM_LH_S_Schlusslicht_re_def_Cx1_defekt)}, range raw 0..1, transfer-property=TRIGGERED-ON-CHANGE-WITHOUT-REPETITION  # Neues Signal Licht-Hinten-Slave an Licht-Master: Fehlererkennung Schlusslicht hinten rechts
          signal LH_S_SL_BRL_BLK_li_def_XIX_Licht_hinten_Slave_01_XIX_E3V_K2CANFD: start 23, 1 bit, little-endian, data-type-policy=OVERRIDE, i-signal-type=PRIMITIVE, init-value=0, base-type=BT_LH_S_SL_BRL_BLK_li_def, compu {0=Cx0_iO (CM_LH_S_SL_BRL_BLK_li_def_Cx0_iO), 1=Cx1_defekt (CM_LH_S_SL_BRL_BLK_li_def_Cx1_defekt)}, range raw 0..1, transfer-property=TRIGGERED-ON-CHANGE-WITHOUT-REPETITION  # Neues Signal Licht-Hinten-Slave an Licht-Master: Konfiguration SL + BRL + BLK links oder SL + BRL + BLK + PL links
          signal LH_S_SL_BRL_BLK_re_def_XIX_Licht_hinten_Slave_01_XIX_E3V_K2CANFD: start 24, 1 bit, little-endian, data-type-policy=OVERRIDE, i-signal-type=PRIMITIVE, init-value=0, base-type=BT_LH_S_SL_BRL_BLK_re_def, compu {0=Cx0_iO (CM_LH_S_SL_BRL_BLK_re_def_Cx0_iO), 1=Cx1_defekt (CM_LH_S_SL_BRL_BLK_re_def_Cx1_defekt)}, range raw 0..1, transfer-property=TRIGGERED-ON-CHANGE-WITHOUT-REPETITION  # Neues Signal Licht-Hinten-Slave an Licht-Master: Konfiguration SL + BRL + BLK rechts oder SL + BRL + BLK + PL rechts
          signal LH_S_3_Bremsl_def_XIX_Licht_hinten_Slave_01_XIX_E3V_K2CANFD: start 25, 1 bit, little-endian, data-type-policy=OVERRIDE, i-signal-type=PRIMITIVE, init-value=0, base-type=BT_LH_S_3_Bremsl_def, compu {0=Cx0_iO (CM_LH_S_3_Bremsl_def_Cx0_iO), 1=Cx1_defekt (CM_LH_S_3_Bremsl_def_Cx1_defekt)}, range raw 0..1, transfer-property=TRIGGERED-ON-CHANGE-WITHOUT-REPETITION  # Neues Signal Licht-Hinten-Slave an Licht-Master: Fehlerstatus 3. Bremsleuchte
          signal LH_S_Aussenlicht_def_XIX_Licht_hinten_Slave_01_XIX_E3V_K2CANFD: start 26, 1 bit, little-endian, data-type-policy=OVERRIDE, i-signal-type=PRIMITIVE, init-value=0, base-type=BT_LH_S_Aussenlicht_def, compu {0=Cx0_iO (CM_LH_S_Aussenlicht_def_Cx0_iO), 1=Cx1_defekt (CM_LH_S_Aussenlicht_def_Cx1_defekt)}, range raw 0..1, transfer-property=TRIGGERED-ON-CHANGE-WITHOUT-REPETITION  # Neues Signal Licht-Hinten-Slave an Licht-Master: Aussenlicht kann nicht mehr korrekt angesteuert werden (EEPROM Codierung kann nicht mehr ausgelesen werden)
          signal LH_S_Blinker_li_def_XIX_Licht_hinten_Slave_01_XIX_E3V_K2CANFD: start 27, 1 bit, little-endian, data-type-policy=OVERRIDE, i-signal-type=PRIMITIVE, init-value=0, base-type=BT_LH_S_Blinker_li_def, compu {0=Cx0_iO (CM_LH_S_Blinker_li_def_Cx0_iO), 1=Cx1_defekt (CM_LH_S_Blinker_li_def_Cx1_defekt)}, range raw 0..1, transfer-property=TRIGGERED-ON-CHANGE-WITHOUT-REPETITION  # Neues Signal Licht-Hinten-Slave an Licht-Master: Fehlerstatus Blinker hinten links
          signal LH_S_Blinker_re_def_XIX_Licht_hinten_Slave_01_XIX_E3V_K2CANFD: start 28, 1 bit, little-endian, data-type-policy=OVERRIDE, i-signal-type=PRIMITIVE, init-value=0, base-type=BT_LH_S_Blinker_re_def, compu {0=Cx0_iO (CM_LH_S_Blinker_re_def_Cx0_iO), 1=Cx1_defekt (CM_LH_S_Blinker_re_def_Cx1_defekt)}, range raw 0..1, transfer-property=TRIGGERED-ON-CHANGE-WITHOUT-REPETITION  # Neues Signal Licht-Hinten-Slave an Licht-Master: Fehlerstatus Blinker hinten rechts
          signal LH_S_Brems_Blk_li_def_XIX_Licht_hinten_Slave_01_XIX_E3V_K2CANFD: start 29, 1 bit, little-endian, data-type-policy=OVERRIDE, i-signal-type=PRIMITIVE, init-value=0, base-type=BT_LH_S_Brems_Blk_li_def, compu {0=Cx0_iO (CM_LH_S_Brems_Blk_li_def_Cx0_iO), 1=Cx1_defekt (CM_LH_S_Brems_Blk_li_def_Cx1_defekt)}, range raw 0..1, transfer-property=TRIGGERED-ON-CHANGE-WITHOUT-REPETITION  # Neues Signal Licht-Hinten-Slave an Licht-Master: Konfiguration BRL + BLK links
          signal LH_S_Brems_Blk_re_def_XIX_Licht_hinten_Slave_01_XIX_E3V_K2CANFD: start 30, 1 bit, little-endian, data-type-policy=OVERRIDE, i-signal-type=PRIMITIVE, init-value=0, base-type=BT_LH_S_Brems_Blk_re_def, compu {0=Cx0_iO (CM_LH_S_Brems_Blk_re_def_Cx0_iO), 1=Cx1_defekt (CM_LH_S_Brems_Blk_re_def_Cx1_defekt)}, range raw 0..1, transfer-property=TRIGGERED-ON-CHANGE-WITHOUT-REPETITION  # Neues Signal Licht-Hinten-Slave an Licht-Master: Konfiguration BRL + BLK rechts
          signal LH_S_Bremsl_li_def_XIX_Licht_hinten_Slave_01_XIX_E3V_K2CANFD: start 31, 1 bit, little-endian, data-type-policy=OVERRIDE, i-signal-type=PRIMITIVE, init-value=0, base-type=BT_LH_S_Bremsl_li_def, compu {0=Cx0_iO (CM_LH_S_Bremsl_li_def_Cx0_iO), 1=Cx1_defekt (CM_LH_S_Bremsl_li_def_Cx1_defekt)}, range raw 0..1, transfer-property=TRIGGERED-ON-CHANGE-WITHOUT-REPETITION  # Neues Signal Licht-Hinten-Slave an Licht-Master: Fehlerstatus Bremslicht hinten links (Detektion Einzelausfall)
          signal LH_S_Bremsl_re_def_XIX_Licht_hinten_Slave_01_XIX_E3V_K2CANFD: start 32, 1 bit, little-endian, data-type-policy=OVERRIDE, i-signal-type=PRIMITIVE, init-value=0, base-type=BT_LH_S_Bremsl_re_def, compu {0=Cx0_iO (CM_LH_S_Bremsl_re_def_Cx0_iO), 1=Cx1_defekt (CM_LH_S_Bremsl_re_def_Cx1_defekt)}, range raw 0..1, transfer-property=TRIGGERED-ON-CHANGE-WITHOUT-REPETITION  # Neues Signal Licht-Hinten-Slave an Licht-Master: Fehlerstatus Bremslicht hinten rechts (Detektion Einzelausfall)
          signal LH_S_Bremslicht_H_aktiv_XIX_Licht_hinten_Slave_01_XIX_E3V_K2CANFD: start 33, 1 bit, little-endian, data-type-policy=OVERRIDE, i-signal-type=PRIMITIVE, init-value=0, base-type=BT_LH_S_Bremslicht_H_aktiv, compu {0=Cx0_Bremslicht_hinten_inaktiv (CM_LH_S_Bremslicht_H_aktiv_Cx0_Bremslicht_hinten_inaktiv), 1=Cx1_Bremslicht_hinten_aktiv (CM_LH_S_Bremslicht_H_aktiv_Cx1_Bremslicht_hinten_aktiv)}, range raw 0..1, transfer-property=TRIGGERED-ON-CHANGE-WITHOUT-REPETITION  # Neues Signal Licht-Hinten-Slave an Licht-Master: Bremslicht hinten
          signal LH_S_Kennzl_def_XIX_Licht_hinten_Slave_01_XIX_E3V_K2CANFD: start 34, 1 bit, little-endian, data-type-policy=OVERRIDE, i-signal-type=PRIMITIVE, init-value=0, base-type=BT_LH_S_Kennzl_def, compu {0=Cx0_iO (CM_LH_S_Kennzl_def_Cx0_iO), 1=Cx1_defekt (CM_LH_S_Kennzl_def_Cx1_defekt)}, range raw 0..1, transfer-property=TRIGGERED-ON-CHANGE-WITHOUT-REPETITION  # Neues Signal Licht-Hinten-Slave an Licht-Master: Fehlerstatus Kennzeichenbeleuchtung hinten
          signal LH_S_Nebel_li_def_XIX_Licht_hinten_Slave_01_XIX_E3V_K2CANFD: start 35, 1 bit, little-endian, data-type-policy=OVERRIDE, i-signal-type=PRIMITIVE, init-value=0, base-type=BT_LH_S_Nebel_li_def, compu {0=Cx0_iO (CM_LH_S_Nebel_li_def_Cx0_iO), 1=Cx1_defekt (CM_LH_S_Nebel_li_def_Cx1_defekt)}, range raw 0..1, transfer-property=TRIGGERED-ON-CHANGE-WITHOUT-REPETITION  # Neues Signal Licht-Hinten-Slave an Licht-Master: Fehlererkennung Nebelschlusslicht hinten links
          signal LH_S_Nebel_mi_def_XIX_Licht_hinten_Slave_01_XIX_E3V_K2CANFD: start 36, 1 bit, little-endian, data-type-policy=OVERRIDE, i-signal-type=PRIMITIVE, init-value=0, base-type=BT_LH_S_Nebel_mi_def, compu {0=Cx0_iO (CM_LH_S_Nebel_mi_def_Cx0_iO), 1=Cx1_defekt (CM_LH_S_Nebel_mi_def_Cx1_defekt)}, range raw 0..1, transfer-property=TRIGGERED-ON-CHANGE-WITHOUT-REPETITION  # Neues Signal Licht-Hinten-Slave an Licht-Master: Fehlererkennung Nebelschlusslicht hinten Mitte
          signal LH_S_Nebel_re_def_XIX_Licht_hinten_Slave_01_XIX_E3V_K2CANFD: start 37, 1 bit, little-endian, data-type-policy=OVERRIDE, i-signal-type=PRIMITIVE, init-value=0, base-type=BT_LH_S_Nebel_re_def, compu {0=Cx0_iO (CM_LH_S_Nebel_re_def_Cx0_iO), 1=Cx1_defekt (CM_LH_S_Nebel_re_def_Cx1_defekt)}, range raw 0..1, transfer-property=TRIGGERED-ON-CHANGE-WITHOUT-REPETITION  # Fehlererkennung Nebelschlusslicht hinten rechts
          signal LH_S_Bremsl_li_ges_def_XIX_Licht_hinten_Slave_01_XIX_E3V_K2CANFD: start 38, 1 bit, little-endian, data-type-policy=OVERRIDE, i-signal-type=PRIMITIVE, init-value=0, base-type=BT_LH_S_Bremsl_li_ges_def, compu {0=Cx0_OK (CM_LH_S_Bremsl_li_ges_def_Cx0_OK), 1=Cx1_Alle_Bremslichter_hinten_links_defekt (CM_LH_S_Bremsl_li_ges_def_Cx1_Alle_Bremslichter_hinten_links_defekt) (Alle Bremslichter hinten links defekt)}, range raw 0..1, transfer-property=TRIGGERED-ON-CHANGE-WITHOUT-REPETITION  # Neues Signal Licht-Hinten-Slave an Licht-Master: Fehlerstatus Bremslicht hinten links (Detektion Totalausfall)
          signal LH_S_Bremsl_re_ges_def_XIX_Licht_hinten_Slave_01_XIX_E3V_K2CANFD: start 39, 1 bit, little-endian, data-type-policy=OVERRIDE, i-signal-type=PRIMITIVE, init-value=0, base-type=BT_LH_S_Bremsl_re_ges_def, compu {0=Cx0_OK (CM_LH_S_Bremsl_re_ges_def_Cx0_OK), 1=Cx1_Alle_Bremslichter_hinten_rechts_defekt (CM_LH_S_Bremsl_re_ges_def_Cx1_Alle_Bremslichter_hinten_rechts_defekt) (Alle Bremslichter hinten rechts defekt)}, range raw 0..1, transfer-property=TRIGGERED-ON-CHANGE-WITHOUT-REPETITION  # Neues Signal Licht-Hinten-Slave an Licht-Master: Fehlerstatus Bremslicht hinten rechts (Detektion Totalausfall)
          signal LH_S_Schlusslicht_mi_def_XIX_Licht_hinten_Slave_01_XIX_E3V_K2CANFD: start 40, 1 bit, little-endian, data-type-policy=OVERRIDE, i-signal-type=PRIMITIVE, init-value=0, base-type=BT_LH_S_Schlusslicht_mi_def, compu {0=Cx0_OK (CM_LH_S_Schlusslicht_mi_def_Cx0_OK), 1=Cx1_defekt (CM_LH_S_Schlusslicht_mi_def_Cx1_defekt)}, range raw 0..1, transfer-property=TRIGGERED-ON-CHANGE-WITHOUT-REPETITION  # Fehlererkennung Schlusslicht hinten Mitte
          signal LH_S_Schluss_Brems_mi_def_XIX_Licht_hinten_Slave_01_XIX_E3V_K2CANFD: start 41, 1 bit, little-endian, data-type-policy=OVERRIDE, i-signal-type=PRIMITIVE, init-value=0, base-type=BT_LH_S_Schluss_Brems_mi_def, compu {0=Cx0_OK (CM_LH_S_Schluss_Brems_mi_def_Cx0_OK), 1=Cx1_Defekt (CM_LH_S_Schluss_Brems_mi_def_Cx1_Defekt)}, range raw 0..1, transfer-property=TRIGGERED-ON-CHANGE-WITHOUT-REPETITION  # Fehlerstatus Schluss + Bremslicht mitte defekt (Detektion Einzelausfall)
      frame Licht_vorne_01_XIX_E3V_K2CANFD: id 0x658, to SAM, frame-length=8, can-addressing-mode=STANDARD, can-frame-rx-behavior=CAN-FD, can-frame-tx-behavior=CAN-FD
        pdu Licht_vorne_01_XIX_E3V_K2CANFD: length=8, minimum-delay=0.05, transmission-mode-true-timing={cyclic-timing={time-offset=0.0, time-period=1.0}, event-controlled-timing={number-of-repetitions=0, repetition-period=0.0}}, unused-bit-pattern=0
          signal Licht_Vorne_01_CRC_XIX_Licht_vorne_01_XIX_E3V_K2CANFD: start 0, 8 bit, little-endian, data-type-policy=OVERRIDE, i-signal-type=PRIMITIVE, init-value=0, base-type=BT_Licht_Vorne_01_CRC, compu {phys=raw for raw 0..255}, range phys 0..255, raw 0..255, transfer-property=PENDING  # Für MLB: "Berechnung siehe Lastenheft "Kommunikationsabsicherung für FlexRay und CAN"" Ab MQB und MLBevo: "Berechnung siehe Lastenheft "End-to-End Kommunikationsabsicherung"" Endwerte siehe Begleitdokument "S-PDU Kennungsfolgen"
          signal Licht_Vorne_01_BZ_XIX_Licht_vorne_01_XIX_E3V_K2CANFD: start 8, 4 bit, little-endian, data-type-policy=OVERRIDE, i-signal-type=PRIMITIVE, init-value=0, base-type=BT_Licht_Vorne_01_BZ, compu {phys=raw for raw 0..15}, range phys 0..15, raw 0..15, transfer-property=PENDING
          signal LV_Standlicht_Anzeige_XIX_Licht_vorne_01_XIX_E3V_K2CANFD: start 12, 1 bit, little-endian, data-type-policy=OVERRIDE, i-signal-type=PRIMITIVE, init-value=0, base-type=BT_LV_Standlicht_Anzeige, compu {0=Cx0_nicht_aktiv (CM_LV_Standlicht_Anzeige_Cx0_nicht_aktiv) (nicht aktiv), 1=Cx1_aktiv (CM_LV_Standlicht_Anzeige_Cx1_aktiv)}, range raw 0..1, transfer-property=TRIGGERED-ON-CHANGE-WITHOUT-REPETITION  # Anzeige Standlicht
          signal LV_Abblendlicht_Anzeige_XIX_Licht_vorne_01_XIX_E3V_K2CANFD: start 13, 1 bit, little-endian, data-type-policy=OVERRIDE, i-signal-type=PRIMITIVE, init-value=0, base-type=BT_LV_Abblendlicht_Anzeige, compu {0=Cx0_inaktiv (CM_LV_Abblendlicht_Anzeige_Cx0_inaktiv), 1=Cx1_aktiv (CM_LV_Abblendlicht_Anzeige_Cx1_aktiv)}, range raw 0..1, transfer-property=TRIGGERED-ON-CHANGE-WITHOUT-REPETITION, to SAM(timeout 5 s)  # Abblendlicht aktiv
          signal LV_Fernlicht_Anzeige_XIX_Licht_vorne_01_XIX_E3V_K2CANFD: start 14, 1 bit, little-endian, data-type-policy=OVERRIDE, i-signal-type=PRIMITIVE, init-value=0, base-type=BT_LV_Fernlicht_Anzeige, compu {0=Cx0_nicht_aktiv (CM_LV_Fernlicht_Anzeige_Cx0_nicht_aktiv) (nicht aktiv), 1=Cx1_aktiv (CM_LV_Fernlicht_Anzeige_Cx1_aktiv)}, range raw 0..1, transfer-property=TRIGGERED-ON-CHANGE-WITHOUT-REPETITION  # Fernlicht_aktiv
          signal LV_Nebellicht_Anzeige_XIX_Licht_vorne_01_XIX_E3V_K2CANFD: start 15, 1 bit, little-endian, data-type-policy=OVERRIDE, i-signal-type=PRIMITIVE, init-value=0, base-type=BT_LV_Nebellicht_Anzeige, compu {0=Cx0_nicht_aktiv (CM_LV_Nebellicht_Anzeige_Cx0_nicht_aktiv) (nicht aktiv), 1=Cx1_aktiv (CM_LV_Nebellicht_Anzeige_Cx1_aktiv)}, range raw 0..1, transfer-property=TRIGGERED-ON-CHANGE-WITHOUT-REPETITION  # Nebellicht_aktiv
          signal LV_Nebelschlusslicht_Anzeige_XIX_Licht_vorne_01_XIX_E3V_K2CANFD: start 16, 1 bit, little-endian, data-type-policy=OVERRIDE, i-signal-type=PRIMITIVE, init-value=0, base-type=BT_LV_Nebelschlusslicht_Anzeige, compu {0=Cx0_nicht_aktiv (CM_LV_Nebelschlusslicht_Anzeige_Cx0_nicht_aktiv) (nicht aktiv), 1=Cx1_aktiv (CM_LV_Nebelschlusslicht_Anzeige_Cx1_aktiv)}, range raw 0..1, transfer-property=TRIGGERED-ON-CHANGE-WITHOUT-REPETITION  # Nebelschlusslicht_aktiv
          signal LV_Tagfahrlicht_Anzeige_XIX_Licht_vorne_01_XIX_E3V_K2CANFD: start 17, 1 bit, little-endian, data-type-policy=OVERRIDE, i-signal-type=PRIMITIVE, init-value=0, base-type=BT_LV_Tagfahrlicht_Anzeige, compu {0=Cx0_nicht_aktiv (CM_LV_Tagfahrlicht_Anzeige_Cx0_nicht_aktiv) (nicht aktiv), 1=Cx1_aktiv (CM_LV_Tagfahrlicht_Anzeige_Cx1_aktiv)}, range raw 0..1, transfer-property=TRIGGERED-ON-CHANGE-WITHOUT-REPETITION  # Anzeige Tagfahrlicht
          signal LV_AFL_aktiv_Anzeige_XIX_Licht_vorne_01_XIX_E3V_K2CANFD: start 18, 1 bit, little-endian, data-type-policy=OVERRIDE, i-signal-type=PRIMITIVE, init-value=0, base-type=BT_LV_AFL_aktiv_Anzeige, compu {0=Cx0_nicht_aktiv (CM_LV_AFL_aktiv_Anzeige_Cx0_nicht_aktiv) (nicht aktiv), 1=Cx1_aktiv (CM_LV_AFL_aktiv_Anzeige_Cx1_aktiv)}, range raw 0..1, transfer-property=TRIGGERED-ON-CHANGE-WITHOUT-REPETITION  # Anzeige AFL-Funktion
          signal LV_AFL_defekt_XIX_Licht_vorne_01_XIX_E3V_K2CANFD: start 19, 1 bit, little-endian, data-type-policy=OVERRIDE, i-signal-type=PRIMITIVE, init-value=0, base-type=BT_LV_AFL_defekt, compu {0=Cx0_OK (CM_LV_AFL_defekt_Cx0_OK), 1=Cx1_defekt (CM_LV_AFL_defekt_Cx1_defekt)}, range raw 0..1, transfer-property=TRIGGERED-ON-CHANGE-WITHOUT-REPETITION  # Fehlerstatus AFL
          signal LV_Blinker_li_def_XIX_Licht_vorne_01_XIX_E3V_K2CANFD: start 20, 1 bit, little-endian, data-type-policy=OVERRIDE, i-signal-type=PRIMITIVE, init-value=0, base-type=BT_LV_Blinker_li_def, compu {0=Cx0_OK (CM_LV_Blinker_li_def_Cx0_OK), 1=Cx1_defekt (CM_LV_Blinker_li_def_Cx1_defekt)}, range raw 0..1, transfer-property=PENDING  # Fehlerstatus Blinker vorne links
          signal LV_Standlicht_li_def_XIX_Licht_vorne_01_XIX_E3V_K2CANFD: start 21, 1 bit, little-endian, data-type-policy=OVERRIDE, i-signal-type=PRIMITIVE, init-value=0, base-type=BT_LV_Standlicht_li_def, compu {0=Cx0_OK (CM_LV_Standlicht_li_def_Cx0_OK), 1=Cx1_defekt (CM_LV_Standlicht_li_def_Cx1_defekt)}, range raw 0..1, transfer-property=PENDING  # Fehlerstatus Standlicht vorne links
          signal LV_Abblendlicht_li_def_XIX_Licht_vorne_01_XIX_E3V_K2CANFD: start 22, 1 bit, little-endian, data-type-policy=OVERRIDE, i-signal-type=PRIMITIVE, init-value=0, base-type=BT_LV_Abblendlicht_li_def, compu {0=Cx0_OK (CM_LV_Abblendlicht_li_def_Cx0_OK), 1=Cx1_defekt (CM_LV_Abblendlicht_li_def_Cx1_defekt)}, range raw 0..1, transfer-property=PENDING  # Fehlerstatus Abblendlicht vorne links
          signal LV_Fernlicht_li_def_XIX_Licht_vorne_01_XIX_E3V_K2CANFD: start 23, 1 bit, little-endian, data-type-policy=OVERRIDE, i-signal-type=PRIMITIVE, init-value=0, base-type=BT_LV_Fernlicht_li_def, compu {0=Cx0_OK (CM_LV_Fernlicht_li_def_Cx0_OK), 1=Cx1_defekt (CM_LV_Fernlicht_li_def_Cx1_defekt)}, range raw 0..1, transfer-property=PENDING  # Fehlerstatus Fernlicht vorne links
          signal LV_Nebellicht_li_def_XIX_Licht_vorne_01_XIX_E3V_K2CANFD: start 24, 1 bit, little-endian, data-type-policy=OVERRIDE, i-signal-type=PRIMITIVE, init-value=0, base-type=BT_LV_Nebellicht_li_def, compu {0=Cx0_OK (CM_LV_Nebellicht_li_def_Cx0_OK), 1=Cx1_defekt (CM_LV_Nebellicht_li_def_Cx1_defekt)}, range raw 0..1, transfer-property=PENDING  # Fehlerstatus Nebelscheinwerfer vorne links
          signal LV_Blk_li_Seite_def_XIX_Licht_vorne_01_XIX_E3V_K2CANFD: start 25, 1 bit, little-endian, data-type-policy=OVERRIDE, i-signal-type=PRIMITIVE, init-value=0, base-type=BT_LV_Blk_li_Seite_def, compu {0=Cx0_OK (CM_LV_Blk_li_Seite_def_Cx0_OK), 1=Cx1_defekt (CM_LV_Blk_li_Seite_def_Cx1_defekt)}, range raw 0..1, transfer-property=PENDING  # Fehlerstatus Seitenblinker links
          signal LV_Tagfahrlicht_li_def_XIX_Licht_vorne_01_XIX_E3V_K2CANFD: start 26, 1 bit, little-endian, data-type-policy=OVERRIDE, i-signal-type=PRIMITIVE, init-value=0, base-type=BT_LV_Tagfahrlicht_li_def, compu {0=Cx0_OK (CM_LV_Tagfahrlicht_li_def_Cx0_OK), 1=Cx1_defekt (CM_LV_Tagfahrlicht_li_def_Cx1_defekt)}, range raw 0..1, transfer-property=PENDING  # Fehlerstatus Tagfahrlicht links
          signal LV_FLA_aktiv_Anzeige_XIX_Licht_vorne_01_XIX_E3V_K2CANFD: start 27, 1 bit, little-endian, data-type-policy=OVERRIDE, i-signal-type=PRIMITIVE, init-value=0, base-type=BT_LV_FLA_aktiv_Anzeige, compu {0=Cx0_aus (CM_LV_FLA_aktiv_Anzeige_Cx0_aus), 1=Cx1_ein (CM_LV_FLA_aktiv_Anzeige_Cx1_ein)}, range raw 0..1, transfer-property=TRIGGERED-ON-CHANGE-WITHOUT-REPETITION  # Ansteuerung FLA-Lampe im Kombi (BCM1 Bedienmaster)
          signal LV_FLA_defekt_XIX_Licht_vorne_01_XIX_E3V_K2CANFD: start 28, 1 bit, little-endian, data-type-policy=OVERRIDE, i-signal-type=PRIMITIVE, init-value=0, base-type=BT_LV_FLA_defekt, compu {0=Cx0_i_O (CM_LV_FLA_defekt_Cx0_i_O) (i.O.), 1=Cx1_FLA_defekt (CM_LV_FLA_defekt_Cx1_FLA_defekt) (FLA defekt)}, range raw 0..1, transfer-property=PENDING  # Fehlerstatus FLA (Anzeige des entsprechenden Fehlertext im Kombi)
          signal LV_FLA_Sensor_blockiert_XIX_Licht_vorne_01_XIX_E3V_K2CANFD: start 29, 1 bit, little-endian, data-type-policy=OVERRIDE, i-signal-type=PRIMITIVE, init-value=0, base-type=BT_LV_FLA_Sensor_blockiert, compu {0=Cx0_i_O (CM_LV_FLA_Sensor_blockiert_Cx0_i_O) (i.O.), 1=Cx1_FLA_Sensor_blockiert (CM_LV_FLA_Sensor_blockiert_Cx1_FLA_Sensor_blockiert) (FLA-Sensor blockiert)}, range raw 0..1, transfer-property=PENDING  # Status FLA-Sensor (Anzeige des entsprechenden Fehlertext im Kombi)
          signal LV_Blinker_re_def_XIX_Licht_vorne_01_XIX_E3V_K2CANFD: start 30, 1 bit, little-endian, data-type-policy=OVERRIDE, i-signal-type=PRIMITIVE, init-value=0, base-type=BT_LV_Blinker_re_def, compu {0=Cx0_OK (CM_LV_Blinker_re_def_Cx0_OK), 1=Cx1_defekt (CM_LV_Blinker_re_def_Cx1_defekt)}, range raw 0..1, transfer-property=PENDING  # Fehlerstatus Blinker vorne rechts
          signal LV_Standlicht_re_def_XIX_Licht_vorne_01_XIX_E3V_K2CANFD: start 31, 1 bit, little-endian, data-type-policy=OVERRIDE, i-signal-type=PRIMITIVE, init-value=0, base-type=BT_LV_Standlicht_re_def, compu {0=Cx0_OK (CM_LV_Standlicht_re_def_Cx0_OK), 1=Cx1_defekt (CM_LV_Standlicht_re_def_Cx1_defekt)}, range raw 0..1, transfer-property=PENDING  # Fehlerstatus Standlicht vorne rechts
          signal LV_Abblendlicht_re_def_XIX_Licht_vorne_01_XIX_E3V_K2CANFD: start 32, 1 bit, little-endian, data-type-policy=OVERRIDE, i-signal-type=PRIMITIVE, init-value=0, base-type=BT_LV_Abblendlicht_re_def, compu {0=Cx0_OK (CM_LV_Abblendlicht_re_def_Cx0_OK), 1=Cx1_defekt (CM_LV_Abblendlicht_re_def_Cx1_defekt)}, range raw 0..1, transfer-property=PENDING  # Fehlerstatus Abblendlicht vorne rechts
          signal LV_Fernlicht_re_def_XIX_Licht_vorne_01_XIX_E3V_K2CANFD: start 33, 1 bit, little-endian, data-type-policy=OVERRIDE, i-signal-type=PRIMITIVE, init-value=0, base-type=BT_LV_Fernlicht_re_def, compu {0=Cx0_OK (CM_LV_Fernlicht_re_def_Cx0_OK), 1=Cx1_defekt (CM_LV_Fernlicht_re_def_Cx1_defekt)}, range raw 0..1, transfer-property=PENDING  # Fehlerstatus Fernlicht vorne rechts
          signal LV_Nebellicht_re_def_XIX_Licht_vorne_01_XIX_E3V_K2CANFD: start 34, 1 bit, little-endian, data-type-policy=OVERRIDE, i-signal-type=PRIMITIVE, init-value=0, base-type=BT_LV_Nebellicht_re_def, compu {0=Cx0_OK (CM_LV_Nebellicht_re_def_Cx0_OK), 1=Cx1_defekt (CM_LV_Nebellicht_re_def_Cx1_defekt)}, range raw 0..1, transfer-property=PENDING  # Fehlerstatus Nebelscheinwerfer vorne rechts
          signal LV_Blk_re_Seite_def_XIX_Licht_vorne_01_XIX_E3V_K2CANFD: start 35, 1 bit, little-endian, data-type-policy=OVERRIDE, i-signal-type=PRIMITIVE, init-value=0, base-type=BT_LV_Blk_re_Seite_def, compu {0=Cx0_OK (CM_LV_Blk_re_Seite_def_Cx0_OK), 1=Cx1_defekt (CM_LV_Blk_re_Seite_def_Cx1_defekt)}, range raw 0..1, transfer-property=PENDING  # Fehlerstatus Blinker Seite rechts
          signal LV_Tagfahrlicht_re_def_XIX_Licht_vorne_01_XIX_E3V_K2CANFD: start 36, 1 bit, little-endian, data-type-policy=OVERRIDE, i-signal-type=PRIMITIVE, init-value=0, base-type=BT_LV_Tagfahrlicht_re_def, compu {0=Cx0_OK (CM_LV_Tagfahrlicht_re_def_Cx0_OK), 1=Cx1_defekt (CM_LV_Tagfahrlicht_re_def_Cx1_defekt)}, range raw 0..1, transfer-property=PENDING  # Fehlerstatus Tagfahrlicht rechts
          signal LV_Aussenlicht_def_XIX_Licht_vorne_01_XIX_E3V_K2CANFD: start 37, 1 bit, little-endian, data-type-policy=OVERRIDE, i-signal-type=PRIMITIVE, init-value=0, base-type=BT_LV_Aussenlicht_def, compu {0=Cx0_OK (CM_LV_Aussenlicht_def_Cx0_OK), 1=Cx1_defekt (CM_LV_Aussenlicht_def_Cx1_defekt)}, range raw 0..1, transfer-property=TRIGGERED-ON-CHANGE-WITHOUT-REPETITION  # Aussenlicht kann nicht mehr korrekt angesteuert werden (EEPROM Codierung kann nicht mehr ausgelesen werden)
          signal LV_Abblendlicht_TFL_li_def_XIX_Licht_vorne_01_XIX_E3V_K2CANFD: start 38, 1 bit, little-endian, data-type-policy=OVERRIDE, i-signal-type=PRIMITIVE, init-value=0, base-type=BT_LV_Abblendlicht_TFL_li_def, compu {0=Cx0_OK (CM_LV_Abblendlicht_TFL_li_def_Cx0_OK), 1=Cx1_defekt (CM_LV_Abblendlicht_TFL_li_def_Cx1_defekt)}, range raw 0..1, transfer-property=PENDING  # Fehlerstatus Abblendlicht und Tagfahrlicht links
          signal LV_Nebellicht_TFL_li_def_XIX_Licht_vorne_01_XIX_E3V_K2CANFD: start 39, 1 bit, little-endian, data-type-policy=OVERRIDE, i-signal-type=PRIMITIVE, init-value=0, base-type=BT_LV_Nebellicht_TFL_li_def, compu {0=Cx0_OK (CM_LV_Nebellicht_TFL_li_def_Cx0_OK), 1=Cx1_defekt (CM_LV_Nebellicht_TFL_li_def_Cx1_defekt)}, range raw 0..1, transfer-property=PENDING  # Fehlerstatus Nebellicht und Tagfahrlicht links
          signal LV_Standlicht_TFL_li_def_XIX_Licht_vorne_01_XIX_E3V_K2CANFD: start 40, 1 bit, little-endian, data-type-policy=OVERRIDE, i-signal-type=PRIMITIVE, init-value=0, base-type=BT_LV_Standlicht_TFL_li_def, compu {0=Cx0_OK (CM_LV_Standlicht_TFL_li_def_Cx0_OK), 1=Cx1_defekt (CM_LV_Standlicht_TFL_li_def_Cx1_defekt)}, range raw 0..1, transfer-property=PENDING  # Fehlerstatus Standlicht und Tagfahrlicht links
          signal LV_Abblend_Fernlicht_li_def_XIX_Licht_vorne_01_XIX_E3V_K2CANFD: start 41, 1 bit, little-endian, data-type-policy=OVERRIDE, i-signal-type=PRIMITIVE, init-value=0, base-type=BT_LV_Abblend_Fernlicht_li_def, compu {0=Cx0_OK (CM_LV_Abblend_Fernlicht_li_def_Cx0_OK), 1=Cx1_defekt (CM_LV_Abblend_Fernlicht_li_def_Cx1_defekt)}, range raw 0..1, transfer-property=PENDING  # Fehlerstatus Abblendlicht und Fernlicht links
          signal LV_Abblendlicht_TFL_re_def_XIX_Licht_vorne_01_XIX_E3V_K2CANFD: start 42, 1 bit, little-endian, data-type-policy=OVERRIDE, i-signal-type=PRIMITIVE, init-value=0, base-type=BT_LV_Abblendlicht_TFL_re_def, compu {0=Cx0_OK (CM_LV_Abblendlicht_TFL_re_def_Cx0_OK), 1=Cx1_defekt (CM_LV_Abblendlicht_TFL_re_def_Cx1_defekt)}, range raw 0..1, transfer-property=PENDING  # Fehlerstatus Abblendlicht und Tagfahrlicht rechts
          signal LV_Nebellicht_TFL_re_def_XIX_Licht_vorne_01_XIX_E3V_K2CANFD: start 43, 1 bit, little-endian, data-type-policy=OVERRIDE, i-signal-type=PRIMITIVE, init-value=0, base-type=BT_LV_Nebellicht_TFL_re_def, compu {0=Cx0_OK (CM_LV_Nebellicht_TFL_re_def_Cx0_OK), 1=Cx1_defekt (CM_LV_Nebellicht_TFL_re_def_Cx1_defekt)}, range raw 0..1, transfer-property=PENDING  # Fehlerstatus Nebellicht und Tagfahrlicht rechts
          signal LV_Standlicht_TFL_re_def_XIX_Licht_vorne_01_XIX_E3V_K2CANFD: start 44, 1 bit, little-endian, data-type-policy=OVERRIDE, i-signal-type=PRIMITIVE, init-value=0, base-type=BT_LV_Standlicht_TFL_re_def, compu {0=Cx0_OK (CM_LV_Standlicht_TFL_re_def_Cx0_OK), 1=Cx1_defekt (CM_LV_Standlicht_TFL_re_def_Cx1_defekt)}, range raw 0..1, transfer-property=PENDING  # Fehlerstatus Standlicht und Tagfahrlicht rechts
          signal LV_Abblend_Fernlicht_re_def_XIX_Licht_vorne_01_XIX_E3V_K2CANFD: start 45, 1 bit, little-endian, data-type-policy=OVERRIDE, i-signal-type=PRIMITIVE, init-value=0, base-type=BT_LV_Abblend_Fernlicht_re_def, compu {0=Cx0_OK (CM_LV_Abblend_Fernlicht_re_def_Cx0_OK), 1=Cx1_defekt (CM_LV_Abblend_Fernlicht_re_def_Cx1_defekt)}, range raw 0..1, transfer-property=PENDING  # Fehlerstatus Abblendlicht und Fernlicht rechts
          signal LV_Abbiegelicht_li_def_XIX_Licht_vorne_01_XIX_E3V_K2CANFD: start 46, 1 bit, little-endian, data-type-policy=OVERRIDE, i-signal-type=PRIMITIVE, init-value=0, base-type=BT_LV_Abbiegelicht_li_def, compu {0=Cx0_OK (CM_LV_Abbiegelicht_li_def_Cx0_OK), 1=Cx1_defekt (CM_LV_Abbiegelicht_li_def_Cx1_defekt)}, range raw 0..1, transfer-property=PENDING  # Fehlerstatus Abbiegelicht vorne links
          signal LV_Abbiegelicht_re_def_XIX_Licht_vorne_01_XIX_E3V_K2CANFD: start 47, 1 bit, little-endian, data-type-policy=OVERRIDE, i-signal-type=PRIMITIVE, init-value=0, base-type=BT_LV_Abbiegelicht_re_def, compu {0=Cx0_OK (CM_LV_Abbiegelicht_re_def_Cx0_OK), 1=Cx1_defekt (CM_LV_Abbiegelicht_re_def_Cx1_defekt)}, range raw 0..1, transfer-property=PENDING  # Fehlerstatus Abbiegelicht vorne rechts
          signal BCM1_Licht_Dunkelheit_aktiv_XIX_Licht_vorne_01_XIX_E3V_K2CANFD: start 49, 1 bit, little-endian, data-type-policy=OVERRIDE, i-signal-type=PRIMITIVE, init-value=0, base-type=BT_BCM1_Licht_Dunkelheit_aktiv, compu {0=Cx0_inaktiv (CM_BCM1_Licht_Dunkelheit_aktiv_Cx0_inaktiv), 1=Cx1_aktiv (CM_BCM1_Licht_Dunkelheit_aktiv_Cx1_aktiv)}, range raw 0..1, transfer-property=TRIGGERED-ON-CHANGE-WITHOUT-REPETITION  # Licht aktiv aufgrund von Dunkelheit (nicht bei Autobahn-, Tagfahr- oder Regenlicht)
          signal LV_LED_Scheinwerfer_li_def_XIX_Licht_vorne_01_XIX_E3V_K2CANFD: start 50, 1 bit, little-endian, data-type-policy=OVERRIDE, i-signal-type=PRIMITIVE, init-value=0, base-type=BT_LV_LED_Scheinwerfer_li_def, compu {0=Cx0_OK (CM_LV_LED_Scheinwerfer_li_def_Cx0_OK), 1=Cx1_defekt (CM_LV_LED_Scheinwerfer_li_def_Cx1_defekt)}, range raw 0..1, transfer-property=PENDING  # Fehlerstatus LED-Scheinwerfer links
          signal LV_LED_Scheinwerfer_re_def_XIX_Licht_vorne_01_XIX_E3V_K2CANFD: start 51, 1 bit, little-endian, data-type-policy=OVERRIDE, i-signal-type=PRIMITIVE, init-value=0, base-type=BT_LV_LED_Scheinwerfer_re_def, compu {0=Cx0_OK (CM_LV_LED_Scheinwerfer_re_def_Cx0_OK), 1=Cx1_defekt (CM_LV_LED_Scheinwerfer_re_def_Cx1_defekt)}, range raw 0..1, transfer-property=PENDING  # Fehlerstatus LED-Scheinwerfer rechts
          signal LV_Blinker_VL_aktiv_XIX_Licht_vorne_01_XIX_E3V_K2CANFD: start 52, 1 bit, little-endian, data-type-policy=OVERRIDE, i-signal-type=PRIMITIVE, init-value=0, base-type=BT_LV_Blinker_VL_aktiv, compu {0=Cx0_inaktiv (CM_LV_Blinker_VL_aktiv_Cx0_inaktiv), 1=Cx1_aktiv (CM_LV_Blinker_VL_aktiv_Cx1_aktiv)}, range raw 0..1, transfer-property=TRIGGERED-ON-CHANGE-WITHOUT-REPETITION  # Blinker vorne links
          signal LV_Blinker_VR_aktiv_XIX_Licht_vorne_01_XIX_E3V_K2CANFD: start 53, 1 bit, little-endian, data-type-policy=OVERRIDE, i-signal-type=PRIMITIVE, init-value=0, base-type=BT_LV_Blinker_VR_aktiv, compu {0=Cx0_inaktiv (CM_LV_Blinker_VR_aktiv_Cx0_inaktiv), 1=Cx1_aktiv (CM_LV_Blinker_VR_aktiv_Cx1_aktiv)}, range raw 0..1, transfer-property=TRIGGERED-ON-CHANGE-WITHOUT-REPETITION  # Blinker vorne links
          signal LV_MXB_Status_Anzeige_XIX_Licht_vorne_01_XIX_E3V_K2CANFD: start 54, 2 bit, little-endian, data-type-policy=OVERRIDE, i-signal-type=PRIMITIVE, init-value=0, base-type=BT_LV_MXB_Status_Anzeige, compu {0=Cx0_MXB_aus (CM_LV_MXB_Status_Anzeige_Cx0_MXB_aus), 1=Cx1_MXB_regelt (CM_LV_MXB_Status_Anzeige_Cx1_MXB_regelt), 2=Cx2_MXB_volles_Fernlicht (CM_LV_MXB_Status_Anzeige_Cx2_MXB_volles_Fernlicht), 3=Cx3_MXB_und_Laser_aktiv (CM_LV_MXB_Status_Anzeige_Cx3_MXB_und_Laser_aktiv)}, range raw 0..3, transfer-property=TRIGGERED-ON-CHANGE-WITHOUT-REPETITION  # Aktueller Status des Fernlichts / MxB zur Signalisierung im Kombi.
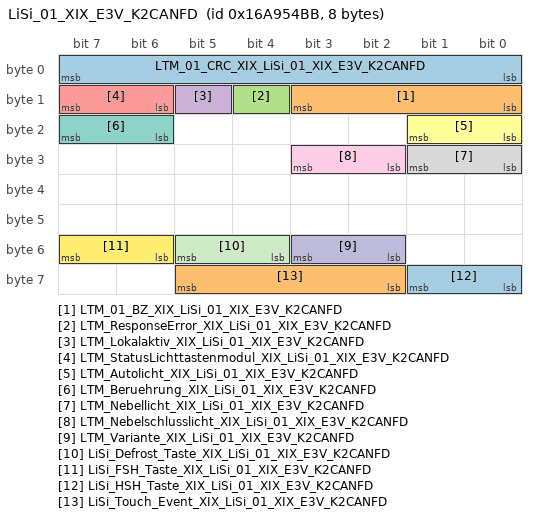
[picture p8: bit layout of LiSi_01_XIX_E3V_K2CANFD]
      frame LiSi_01_XIX_E3V_K2CANFD: id 0x16A954BB, from SAM, frame-length=8, can-addressing-mode=EXTENDED, can-frame-rx-behavior=CAN-FD, can-frame-tx-behavior=CAN-FD
        pdu LiSi_01_XIX_E3V_K2CANFD: length=8, transmission-mode-true-timing=cyclic-timing={time-offset=0.0, time-period=0.04}, unused-bit-pattern=0
          signal LTM_01_CRC_XIX_LiSi_01_XIX_E3V_K2CANFD: start 0, 8 bit, little-endian, data-type-policy=OVERRIDE, i-signal-type=PRIMITIVE, base-type=BT_LTM_01_CRC, compu {phys=raw for raw 0..255}, range phys 0..255, raw 0..255, transfer-property=PENDING  # Ab MQB und MLBevo: "Berechnung siehe Lastenheft "End-to-End Kommunikationsabsicherung"" Endwerte siehe Begleitdokument "S-PDU Kennungsfolgen"
          signal LTM_01_BZ_XIX_LiSi_01_XIX_E3V_K2CANFD: start 8, 4 bit, little-endian, data-type-policy=OVERRIDE, i-signal-type=PRIMITIVE, base-type=BT_LTM_01_BZ, compu {phys=raw for raw 0..15}, range phys 0..15, raw 0..15, transfer-property=PENDING  # 4bit Botschaftszähler
          signal LTM_ResponseError_XIX_LiSi_01_XIX_E3V_K2CANFD: start 12, 1 bit, little-endian, data-type-policy=OVERRIDE, i-signal-type=PRIMITIVE, init-value=0, base-type=BT_LTM_ResponseError, invalid-value=Invalid_LTM_ResponseError_XIX_LiSi_01_XIX_E3V_K2CANFD:1, compu {0=Cx0_normal (CM_LTM_ResponseError_Cx0_normal), 1=Cx1_Fehler (CM_LTM_ResponseError_Cx1_Fehler)}, range raw 0..1, transfer-property=PENDING  # siehe LIN2.0-Specification (Darf nicht über ein Fehlergueltigkeitsbit abgesichtert werden!)
          signal LTM_Lokalaktiv_XIX_LiSi_01_XIX_E3V_K2CANFD: start 13, 1 bit, little-endian, data-type-policy=OVERRIDE, i-signal-type=PRIMITIVE, init-value=0, base-type=BT_LTM_Lokalaktiv, compu {0=Cx0_war_nicht_lokal_aktiv (CM_LTM_Lokalaktiv_Cx0_war_nicht_lokal_aktiv), 1=Cx1_war_lokal_aktiv (CM_LTM_Lokalaktiv_Cx1_war_lokal_aktiv)}, range raw 0..1, transfer-property=PENDING  # Lokalaktiv Statusbit
          signal LTM_StatusLichttastenmodul_XIX_LiSi_01_XIX_E3V_K2CANFD: start 14, 2 bit, little-endian, data-type-policy=OVERRIDE, i-signal-type=PRIMITIVE, init-value=2, base-type=BT_LTM_StatusLichttastenmodul, compu {0=Cx0_Lichttastenmodul_betriebsbereit (CM_LTM_StatusLichttastenmodul_Cx0_Lichttastenmodul_betriebsbereit), 2=Cx2_Init (CM_LTM_StatusLichttastenmodul_Cx2_Init), 3=Cx3_Fehler_oder_defekt (CM_LTM_StatusLichttastenmodul_Cx3_Fehler_oder_defekt)}, range raw 0..3, transfer-property=PENDING  # Betriebszustand Lichttastenmodul
          signal LTM_Autolicht_XIX_LiSi_01_XIX_E3V_K2CANFD: start 16, 2 bit, little-endian, data-type-policy=OVERRIDE, i-signal-type=PRIMITIVE, init-value=0, base-type=BT_LTM_Autolicht, compu {0=Cx0_Taste_unbetaetigt (CM_LTM_Autolicht_Cx0_Taste_unbetaetigt), 1=Cx1_Taste_betaetigt (CM_LTM_Autolicht_Cx1_Taste_betaetigt), 2=Cx2_Taste_nicht_verbaut (CM_LTM_Autolicht_Cx2_Taste_nicht_verbaut)}, range raw 0..2, transfer-property=PENDING  # Status Autolicht-Taste
          signal LTM_Beruehrung_XIX_LiSi_01_XIX_E3V_K2CANFD: start 22, 2 bit, little-endian, data-type-policy=OVERRIDE, i-signal-type=PRIMITIVE, base-type=BT_LTM_Beruehrung, compu {0=Cx0_Beruehrung_inaktiv (CM_LTM_Beruehrung_Cx0_Beruehrung_inaktiv), 1=Cx1_Beruehrung_aktiv (CM_LTM_Beruehrung_Cx1_Beruehrung_aktiv), 2=Cx2_Beruehrungssensor_nicht_verbaut (CM_LTM_Beruehrung_Cx2_Beruehrungssensor_nicht_verbaut)}, range raw 0..2, transfer-property=PENDING  # Status für Berührung der Auto-Taste im Lichttastenmodul (LTM)
          signal LTM_Nebellicht_XIX_LiSi_01_XIX_E3V_K2CANFD: start 24, 2 bit, little-endian, data-type-policy=OVERRIDE, i-signal-type=PRIMITIVE, init-value=0, base-type=BT_LTM_Nebellicht, compu {0=Cx0_Taste_unbetaetigt (CM_LTM_Nebellicht_Cx0_Taste_unbetaetigt), 1=Cx1_Taste_betaetigt (CM_LTM_Nebellicht_Cx1_Taste_betaetigt), 2=Cx2_Taste_nicht_verbaut (CM_LTM_Nebellicht_Cx2_Taste_nicht_verbaut)}, range raw 0..2, transfer-property=PENDING  # Status Nebellicht-Taste
          signal LTM_Nebelschlusslicht_XIX_LiSi_01_XIX_E3V_K2CANFD: start 26, 2 bit, little-endian, data-type-policy=OVERRIDE, i-signal-type=PRIMITIVE, init-value=0, base-type=BT_LTM_Nebelschlusslicht, compu {0=Cx0_Taste_unbetaetigt (CM_LTM_Nebelschlusslicht_Cx0_Taste_unbetaetigt), 1=Cx1_Taste_betaetigt (CM_LTM_Nebelschlusslicht_Cx1_Taste_betaetigt), 2=Cx2_Taste_nicht_verbaut (CM_LTM_Nebelschlusslicht_Cx2_Taste_nicht_verbaut)}, range raw 0..2, transfer-property=PENDING  # Status Nebelschlusslicht-Taste
          signal LTM_Variante_XIX_LiSi_01_XIX_E3V_K2CANFD: start 50, 2 bit, little-endian, data-type-policy=OVERRIDE, i-signal-type=PRIMITIVE, init-value=0, base-type=BT_LTM_Variante, compu {0=Cx0_Ein_Tasten_Bedienung (CM_LTM_Variante_Cx0_Ein_Tasten_Bedienung), 1=Cx1_Drei_Tasten_Bedienung (CM_LTM_Variante_Cx1_Drei_Tasten_Bedienung), 2=Cx2_Variante_3 (CM_LTM_Variante_Cx2_Variante_3), 3=Cx3_Variante_4 (CM_LTM_Variante_Cx3_Variante_4)}, range raw 0..3, transfer-property=PENDING  # LTM_Variante dient zur Unterscheidung, welche Variante des Lichttastenmoduls verbaut ist: 0x00 1-Tasten-Bedienung (LTM mit 1-Hauptlichttaste) 0x01 3-Tasten-Bedienung (LTM mit 3-Hauptlichttasten) 0x02 Variante 3 0x03 Variante 4
          signal LiSi_Defrost_Taste_XIX_LiSi_01_XIX_E3V_K2CANFD: start 52, 2 bit, little-endian, data-type-policy=OVERRIDE, i-signal-type=PRIMITIVE, init-value=3, base-type=BT_LiSi_Defrost_Taste, invalid-value=Invalid_LiSi_Defrost_Taste_XIX_LiSi_01_XIX_E3V_K2CANFD:2, compu {0=Cx0_Taste_nicht_betaetigt (CM_LiSi_Defrost_Taste_Cx0_Taste_nicht_betaetigt), 1=Cx1_Taste_betaetigt (CM_LiSi_Defrost_Taste_Cx1_Taste_betaetigt), 2=Cx2_Fehler (CM_LiSi_Defrost_Taste_Cx2_Fehler), 3=Cx3_Init_oder_nicht_verbaut (CM_LiSi_Defrost_Taste_Cx3_Init_oder_nicht_verbaut)}, range raw 0..3, transfer-property=PENDING  # Defrost AN/AUS und Status
          signal LiSi_FSH_Taste_XIX_LiSi_01_XIX_E3V_K2CANFD: start 54, 2 bit, little-endian, data-type-policy=OVERRIDE, i-signal-type=PRIMITIVE, init-value=3, base-type=BT_LiSi_FSH_Taste, invalid-value=Invalid_LiSi_FSH_Taste_XIX_LiSi_01_XIX_E3V_K2CANFD:2, compu {0=Cx0_Taste_nicht_betaetigt (CM_LiSi_FSH_Taste_Cx0_Taste_nicht_betaetigt), 1=Cx1_Taste_betaetigt (CM_LiSi_FSH_Taste_Cx1_Taste_betaetigt), 2=Cx2_Fehler (CM_LiSi_FSH_Taste_Cx2_Fehler), 3=Cx3_Init_oder_nicht_verbaut (CM_LiSi_FSH_Taste_Cx3_Init_oder_nicht_verbaut)}, range raw 0..3, transfer-property=PENDING  # Frontscheibenheizung AN/AUS und Status
          signal LiSi_HSH_Taste_XIX_LiSi_01_XIX_E3V_K2CANFD: start 56, 2 bit, little-endian, data-type-policy=OVERRIDE, i-signal-type=PRIMITIVE, init-value=3, base-type=BT_LiSi_HSH_Taste, invalid-value=Invalid_LiSi_HSH_Taste_XIX_LiSi_01_XIX_E3V_K2CANFD:2, compu {0=Cx0_Taste_nicht_betaetigt (CM_LiSi_HSH_Taste_Cx0_Taste_nicht_betaetigt), 1=Cx1_Taste_betaetigt (CM_LiSi_HSH_Taste_Cx1_Taste_betaetigt), 2=Cx2_Fehler (CM_LiSi_HSH_Taste_Cx2_Fehler), 3=Cx3_Init_oder_nicht_verbaut (CM_LiSi_HSH_Taste_Cx3_Init_oder_nicht_verbaut)}, range raw 0..3, transfer-property=PENDING  # Heckscheibenheizung AN/AUS
          signal LiSi_Touch_Event_XIX_LiSi_01_XIX_E3V_K2CANFD: start 58, 4 bit, little-endian, data-type-policy=OVERRIDE, i-signal-type=PRIMITIVE, init-value=0, base-type=BT_LiSi_Touch_Event, invalid-value=Invalid_LiSi_Touch_Event_XIX_LiSi_01_XIX_E3V_K2CANFD:15, compu {0=Cx0_nicht_betaetigt (CM_LiSi_Touch_Event_Cx0_nicht_betaetigt), 1=Cx1_Tippen (CM_LiSi_Touch_Event_Cx1_Tippen), 2=Cx2_Wischen_Slide (CM_LiSi_Touch_Event_Cx2_Wischen_Slide), 3=Cx3_Geste (CM_LiSi_Touch_Event_Cx3_Geste), 4=Cx4_Doppeltippen (CM_LiSi_Touch_Event_Cx4_Doppeltippen), 5=Cx5_Longpress_1 (CM_LiSi_Touch_Event_Cx5_Longpress_1), 6=Cx6_Longpress_2 (CM_LiSi_Touch_Event_Cx6_Longpress_2), 7=Cx7_Longpress_3 (CM_LiSi_Touch_Event_Cx7_Longpress_3), 8=Cx8_Press (CM_LiSi_Touch_Event_Cx8_Press), 9=Cx9_Strongpress (CM_LiSi_Touch_Event_Cx9_Strongpress), 10=Cxa_reserviert (CM_LiSi_Touch_Event_Cxa_reserviert), 11=Cxb_reserviert (CM_LiSi_Touch_Event_Cxb_reserviert), 12=Cxc_reserviert (CM_LiSi_Touch_Event_Cxc_reserviert), 13=Cxd_reserviert (CM_LiSi_Touch_Event_Cxd_reserviert), 14=Cxe_Taktgeber_Inkrement (CM_LiSi_Touch_Event_Cxe_Taktgeber_Inkrement), 15=Cxf_Fehler (CM_LiSi_Touch_Event_Cxf_Fehler)}, range raw 0..15, transfer-property=PENDING  # Touch_Events für Informationen einer Funktionsauslösung auf der LiSi, welches dann für bspw. ein akustiches Signal zentral umgesetzt werden können.
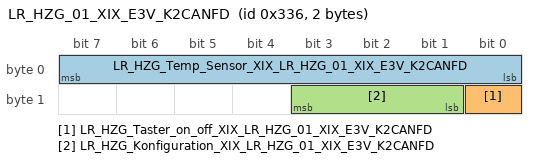
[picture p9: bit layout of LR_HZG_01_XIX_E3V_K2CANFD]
      frame LR_HZG_01_XIX_E3V_K2CANFD: id 0x336, to SAM, frame-length=2, can-addressing-mode=STANDARD, can-frame-rx-behavior=CAN-FD, can-frame-tx-behavior=CAN-FD
        pdu LR_HZG_01_XIX_E3V_K2CANFD: length=2, transmission-mode-true-timing=cyclic-timing={time-offset=0.0, time-period=0.12}, unused-bit-pattern=0
          signal LR_HZG_Temp_Sensor_XIX_LR_HZG_01_XIX_E3V_K2CANFD: start 0, 8 bit, little-endian, data-type-policy=OVERRIDE, i-signal-type=PRIMITIVE, init-value=254, base-type=BT_LR_HZG_Temp_Sensor, compu {phys=raw-50 for raw 0..154, 253=Cxfd_KS_Plus_Unterbrechung (CM_LR_HZG_Temp_Sensor_Cxfd_KS_Plus_Unterbrechung) (KS_Plus__Unterbrechung), 254=Cxfe_Init (CM_LR_HZG_Temp_Sensor_Cxfe_Init), 255=Cxff_Tempsensor_fehlerhaft_KS_GND (CM_LR_HZG_Temp_Sensor_Cxff_Tempsensor_fehlerhaft_KS_GND) (Tempsensor_fehlerhaft__KS_GND); unit Unit_DegreCelsi}, range phys -50..104 Unit_DegreCelsi, raw 0..255, unit=Unit_DegreCelsi, transfer-property=PENDING, to SAM(timeout 1.2 s)  # Temperaturwert Lenkradheizung
          signal LR_HZG_Taster_on_off_XIX_LR_HZG_01_XIX_E3V_K2CANFD: start 8, 1 bit, little-endian, data-type-policy=OVERRIDE, i-signal-type=PRIMITIVE, init-value=0, base-type=BT_LR_HZG_Taster_on_off, compu {0=Cx0_nicht_betaetigt (CM_LR_HZG_Taster_on_off_Cx0_nicht_betaetigt), 1=Cx1_betaetigt (CM_LR_HZG_Taster_on_off_Cx1_betaetigt)}, range raw 0..1, transfer-property=PENDING, to SAM(timeout 1.2 s)  # Anforderung des Schalters am MFL: Lenkradheizung aus/ein (Regelung der LR_HZG ist im SMLS)
          signal LR_HZG_Konfiguration_XIX_LR_HZG_01_XIX_E3V_K2CANFD: start 9, 3 bit, little-endian, data-type-policy=OVERRIDE, i-signal-type=PRIMITIVE, init-value=0, base-type=BT_LR_HZG_Konfiguration, compu {0=Cx0_Init (CM_LR_HZG_Konfiguration_Cx0_Init), 1=Cx1_Parametersatz_1 (CM_LR_HZG_Konfiguration_Cx1_Parametersatz_1), 2=Cx2_Parametersatz_2 (CM_LR_HZG_Konfiguration_Cx2_Parametersatz_2), 3=Cx3_Parametersatz_3 (CM_LR_HZG_Konfiguration_Cx3_Parametersatz_3), 4=Cx4_Parametersatz_4 (CM_LR_HZG_Konfiguration_Cx4_Parametersatz_4), 5=Cx5_Parametersatz_5 (CM_LR_HZG_Konfiguration_Cx5_Parametersatz_5), 6=Cx6_Parametersatz_6 (CM_LR_HZG_Konfiguration_Cx6_Parametersatz_6), 7=Cx7_Parametersatz_7 (CM_LR_HZG_Konfiguration_Cx7_Parametersatz_7)}, range raw 0..7, transfer-property=PENDING, to SAM(timeout 1.2 s)  # Konfiguration der Heizmatte der Lenkradheizung
